VERSION ""

NS_ :

BS_:

BU_:

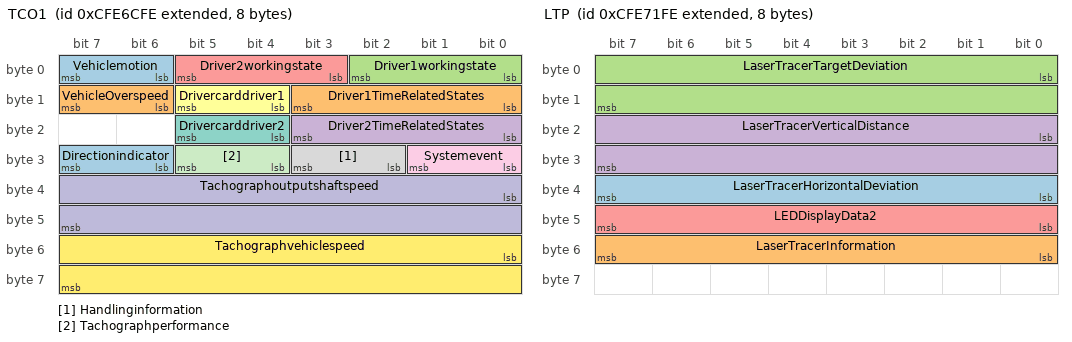
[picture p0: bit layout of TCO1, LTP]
BO_ 2365484286 TCO1: 8 Vector__XXX
 SG_ Directionindicator : 30|2@1+ (1,0) [0|3] "" Vector__XXX
 SG_ Driver1TimeRelatedStates : 8|4@1+ (1,0) [0|15] "" Vector__XXX
 SG_ Driver1workingstate : 0|3@1+ (1,0) [0|7] "" Vector__XXX
 SG_ Driver2TimeRelatedStates : 16|4@1+ (1,0) [0|15] "" Vector__XXX
 SG_ Driver2workingstate : 3|3@1+ (1,0) [0|7] "" Vector__XXX
 SG_ Drivercarddriver1 : 12|2@1+ (1,0) [0|3] "" Vector__XXX
 SG_ Drivercarddriver2 : 20|2@1+ (1,0) [0|3] "" Vector__XXX
 SG_ Handlinginformation : 26|2@1+ (1,0) [0|3] "" Vector__XXX
 SG_ Systemevent : 24|2@1+ (1,0) [0|3] "" Vector__XXX
 SG_ Tachographoutputshaftspeed : 32|16@1+ (0.125,0) [0|8031.875] "rpm" Vector__XXX
 SG_ Tachographperformance : 28|2@1+ (1,0) [0|3] "" Vector__XXX
 SG_ Tachographvehiclespeed : 48|16@1+ (0.00390625,0) [0|250.996] "km/h" Vector__XXX
 SG_ Vehiclemotion : 6|2@1+ (1,0) [0|3] "" Vector__XXX
 SG_ VehicleOverspeed : 14|2@1+ (1,0) [0|3] "" Vector__XXX

BO_ 2365485566 LTP: 8 Vector__XXX
 SG_ LaserTracerHorizontalDeviation : 32|8@1+ (1,0) [0|250] "%" Vector__XXX
 SG_ LaserTracerInformation : 48|8@1+ (1,0) [0|255] "" Vector__XXX
 SG_ LaserTracerTargetDeviation : 0|16@1+ (0.1,-3200) [-3200|3225.5] "mm" Vector__XXX
 SG_ LaserTracerVerticalDistance : 16|16@1+ (0.1,0) [0|6425.5] "mm" Vector__XXX
 SG_ LEDDisplayData2 : 40|8@1+ (1,0) [0|255] "" Vector__XXX

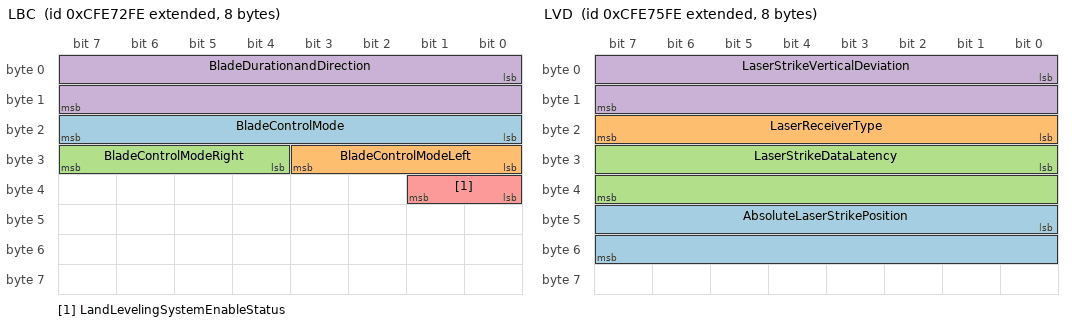
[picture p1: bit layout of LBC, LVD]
BO_ 2365485822 LBC: 8 Vector__XXX
 SG_ BladeControlMode : 16|8@1+ (1,0) [0|255] "" Vector__XXX
 SG_ BladeControlModeLeft : 24|4@1+ (1,0) [0|15] "" Vector__XXX
 SG_ BladeControlModeRight : 28|4@1+ (1,0) [0|15] "" Vector__XXX
 SG_ BladeDurationandDirection : 0|16@1+ (0.1,-3276.8) [-3276.8|3148.7] "s" Vector__XXX
 SG_ LandLevelingSystemEnableStatus : 32|2@1+ (1,0) [0|3] "" Vector__XXX

BO_ 2365486078 LMP: 8 Vector__XXX
 SG_ MastPosition : 0|16@1+ (0.1,-3200) [-3200|3225.5] "mm" Vector__XXX

BO_ 2365486334 LSP: 8 Vector__XXX
 SG_ BldHghtStPntHghRsltn : 16|32@1+ (0.0000001,-209.7152) [-209.7152|211.3929215] "m" Vector__XXX
 SG_ ModifyLevelingSystemSetPoint : 0|16@1+ (0.1,-3200) [-3200|3225.5] "mm" Vector__XXX

BO_ 2365486590 LVD: 8 Vector__XXX
 SG_ AbsoluteLaserStrikePosition : 40|16@1+ (0.1,0) [0|6425.5] "mm" Vector__XXX
 SG_ LaserReceiverType : 16|8@1+ (1,0) [0|250] "count" Vector__XXX
 SG_ LaserStrikeDataLatency : 24|16@1+ (0.0000512,0) [0|3.289856] "s" Vector__XXX
 SG_ LaserStrikeVerticalDeviation : 0|16@1+ (0.1,-3200) [-3200|3225.5] "mm" Vector__XXX

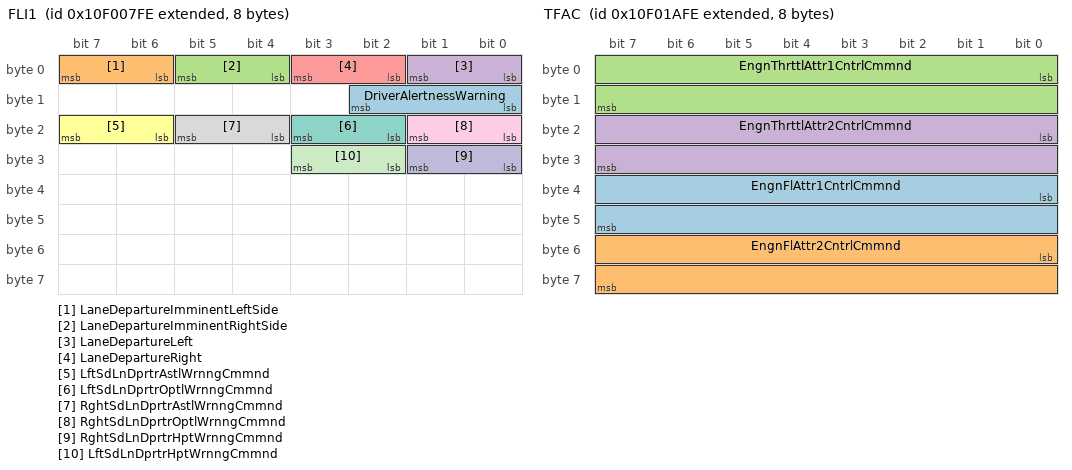
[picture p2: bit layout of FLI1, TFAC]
BO_ 2431649790 FLI1: 8 Vector__XXX
 SG_ DriverAlertnessWarning : 8|3@1+ (1,0) [0|7] "" Vector__XXX
 SG_ LaneDepartureImminentLeftSide : 6|2@1+ (1,0) [0|3] "" Vector__XXX
 SG_ LaneDepartureImminentRightSide : 4|2@1+ (1,0) [0|3] "" Vector__XXX
 SG_ LaneDepartureLeft : 0|2@1+ (1,0) [0|3] "" Vector__XXX
 SG_ LaneDepartureRight : 2|2@1+ (1,0) [0|3] "" Vector__XXX
 SG_ LftSdLnDprtrAstlWrnngCmmnd : 22|2@1+ (1,0) [0|3] "" Vector__XXX
 SG_ LftSdLnDprtrOptlWrnngCmmnd : 18|2@1+ (1,0) [0|3] "" Vector__XXX
 SG_ RghtSdLnDprtrAstlWrnngCmmnd : 20|2@1+ (1,0) [0|3] "" Vector__XXX
 SG_ RghtSdLnDprtrOptlWrnngCmmnd : 16|2@1+ (1,0) [0|3] "" Vector__XXX
 SG_ RghtSdLnDprtrHptWrnngCmmnd : 24|2@1+ (1,0) [0|3] "" Vector__XXX
 SG_ LftSdLnDprtrHptWrnngCmmnd : 26|2@1+ (1,0) [0|3] "" Vector__XXX

BO_ 2431654654 TFAC: 8 Vector__XXX
 SG_ EngnFlAttr1CntrlCmmnd : 32|16@1+ (0.0025,0) [0|160.6375] "%" Vector__XXX
 SG_ EngnFlAttr2CntrlCmmnd : 48|16@1+ (0.0025,0) [0|160.6375] "%" Vector__XXX
 SG_ EngnThrttlAttr1CntrlCmmnd : 0|16@1+ (0.0025,0) [0|160.6375] "%" Vector__XXX
 SG_ EngnThrttlAttr2CntrlCmmnd : 16|16@1+ (0.0025,0) [0|160.6375] "%" Vector__XXX

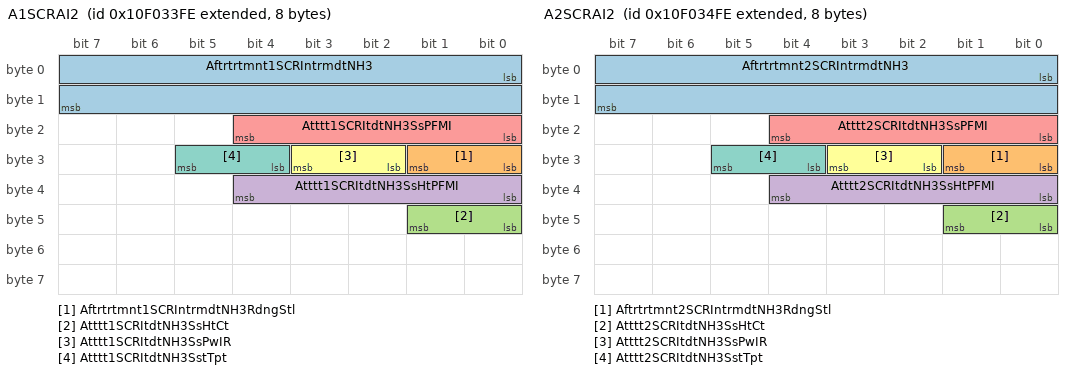
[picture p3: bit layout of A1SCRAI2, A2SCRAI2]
BO_ 2431661054 A1SCRAI2: 8 Vector__XXX
 SG_ Aftrtrtmnt1SCRIntrmdtNH3 : 0|16@1+ (0.1,-200) [-200|6225.5] "ppm" Vector__XXX
 SG_ Aftrtrtmnt1SCRIntrmdtNH3RdngStl : 24|2@1+ (1,0) [0|3] "" Vector__XXX
 SG_ Atttt1SCRItdtNH3SsHtCt : 40|2@1+ (1,0) [0|3] "" Vector__XXX
 SG_ Atttt1SCRItdtNH3SsHtPFMI : 32|5@1+ (1,0) [0|31] "binary" Vector__XXX
 SG_ Atttt1SCRItdtNH3SsPFMI : 16|5@1+ (1,0) [0|31] "binary" Vector__XXX
 SG_ Atttt1SCRItdtNH3SsPwIR : 26|2@1+ (1,0) [0|3] "" Vector__XXX
 SG_ Atttt1SCRItdtNH3SstTpt : 28|2@1+ (1,0) [0|3] "" Vector__XXX

BO_ 2431661310 A2SCRAI2: 8 Vector__XXX
 SG_ Aftrtrtmnt2SCRIntrmdtNH3 : 0|16@1+ (0.1,-200) [-200|6225.5] "ppm" Vector__XXX
 SG_ Aftrtrtmnt2SCRIntrmdtNH3RdngStl : 24|2@1+ (1,0) [0|3] "" Vector__XXX
 SG_ Atttt2SCRItdtNH3SsHtCt : 40|2@1+ (1,0) [0|3] "" Vector__XXX
 SG_ Atttt2SCRItdtNH3SsHtPFMI : 32|5@1+ (1,0) [0|31] "binary" Vector__XXX
 SG_ Atttt2SCRItdtNH3SsPFMI : 16|5@1+ (1,0) [0|31] "binary" Vector__XXX
 SG_ Atttt2SCRItdtNH3SsPwIR : 26|2@1+ (1,0) [0|3] "" Vector__XXX
 SG_ Atttt2SCRItdtNH3SstTpt : 28|2@1+ (1,0) [0|3] "" Vector__XXX

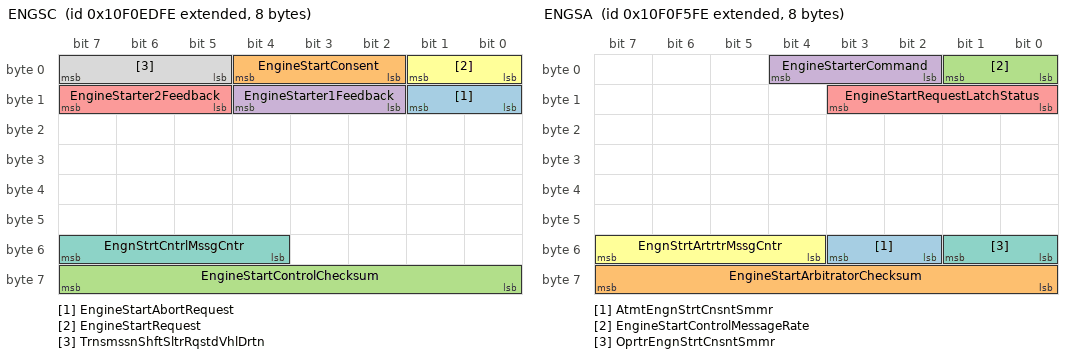
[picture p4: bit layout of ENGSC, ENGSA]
BO_ 2431708670 ENGSC: 8 Vector__XXX
 SG_ EngineStartAbortRequest : 8|2@1+ (1,0) [0|3] "" Vector__XXX
 SG_ EngineStartConsent : 2|3@1+ (1,0) [0|7] "" Vector__XXX
 SG_ EngineStartControlChecksum : 56|8@1+ (1,0) [0|255] "count" Vector__XXX
 SG_ EngineStarter1Feedback : 10|3@1+ (1,0) [0|7] "" Vector__XXX
 SG_ EngineStarter2Feedback : 13|3@1+ (1,0) [0|7] "" Vector__XXX
 SG_ EngineStartRequest : 0|2@1+ (1,0) [0|3] "" Vector__XXX
 SG_ EngnStrtCntrlMssgCntr : 52|4@1+ (1,0) [0|15] "" Vector__XXX
 SG_ TrnsmssnShftSltrRqstdVhlDrtn : 5|3@1+ (1,0) [0|7] "" Vector__XXX

BO_ 2431710718 ENGSA: 8 Vector__XXX
 SG_ AtmtEngnStrtCnsntSmmr : 50|2@1+ (1,0) [0|3] "" Vector__XXX
 SG_ EngineStartArbitratorChecksum : 56|8@1+ (1,0) [0|255] "count" Vector__XXX
 SG_ EngineStartControlMessageRate : 0|2@1+ (1,0) [0|3] "" Vector__XXX
 SG_ EngineStarterCommand : 2|3@1+ (1,0) [0|7] "" Vector__XXX
 SG_ EngineStartRequestLatchStatus : 8|4@1+ (1,0) [0|15] "" Vector__XXX
 SG_ EngnStrtArtrtrMssgCntr : 52|4@1+ (1,0) [0|15] "" Vector__XXX
 SG_ OprtrEngnStrtCnsntSmmr : 48|2@1+ (1,0) [0|3] "" Vector__XXX

BO_ 2431717886 GFP3: 8 Vector__XXX
 SG_ EngnFlVlv1DffrntlPrssrHghRsltn : 0|16@1+ (0.0078125,-100) [-100|401.99] "kPa" Vector__XXX
 SG_ EngnGssFlSpplFltrDffrntlPrssr : 16|16@1+ (0.0078125,-100) [-100|401.99] "kPa" Vector__XXX
 SG_ EngnGssFlSpplFltrIntkPrssr : 32|16@1+ (0.5,0) [0|32127.5] "kPa" Vector__XXX

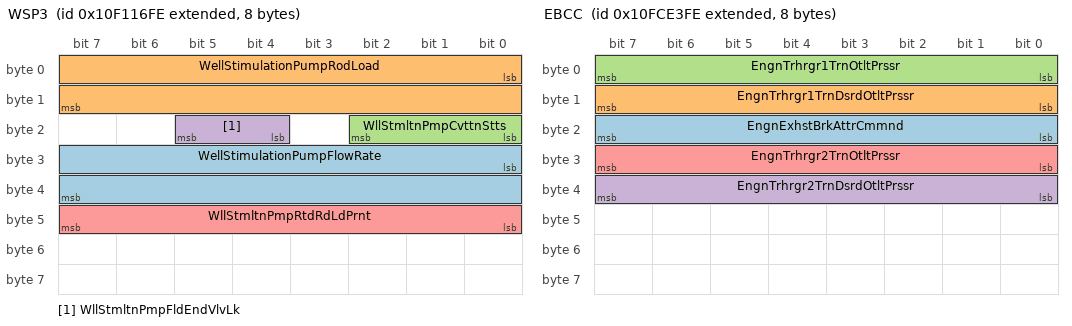
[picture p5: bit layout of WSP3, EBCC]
BO_ 2431719166 WSP3: 8 Vector__XXX
 SG_ WellStimulationPumpFlowRate : 24|16@1+ (0.5,0) [0|32127.5] "l/min" Vector__XXX
 SG_ WellStimulationPumpRodLoad : 0|16@1+ (5,0) [0|321275] "kN" Vector__XXX
 SG_ WllStmltnPmpCvttnStts : 16|3@1+ (1,0) [0|7] "" Vector__XXX
 SG_ WllStmltnPmpFldEndVlvLk : 20|2@1+ (1,0) [0|3] "" Vector__XXX
 SG_ WllStmltnPmpRtdRdLdPrnt : 40|8@1+ (0.5,0) [0|125] "%" Vector__XXX

BO_ 2432471038 AF3: 8 Vector__XXX
 SG_ EngnFlVprzr1DshrgTmprtr : 16|8@1+ (1,-40) [-40|210] "degC" Vector__XXX
 SG_ EngnGssFlSpplPrssr1ExtnddRng : 0|16@1+ (0.00390625,0) [0|250.996] "MPa" Vector__XXX
 SG_ GssFlAmltrTmprtr : 24|8@1+ (1,-40) [-40|210] "degC" Vector__XXX
 SG_ EGssFSppPssRtCtCd : 32|16@1+ (0.0025,0) [0|160.6375] "%" Vector__XXX

BO_ 2432492542 EBCC: 8 Vector__XXX
 SG_ EngnExhstBrkAttrCmmnd : 16|8@1+ (0.4,0) [0|100] "%" Vector__XXX
 SG_ EngnTrhrgr1TrnDsrdOtltPrssr : 8|8@1+ (2,0) [0|500] "kPa" Vector__XXX
 SG_ EngnTrhrgr1TrnOtltPrssr : 0|8@1+ (2,0) [0|500] "kPa" Vector__XXX
 SG_ EngnTrhrgr2TrnDsrdOtltPrssr : 32|8@1+ (2,0) [0|500] "kPa" Vector__XXX
 SG_ EngnTrhrgr2TrnOtltPrssr : 24|8@1+ (2,0) [0|500] "kPa" Vector__XXX

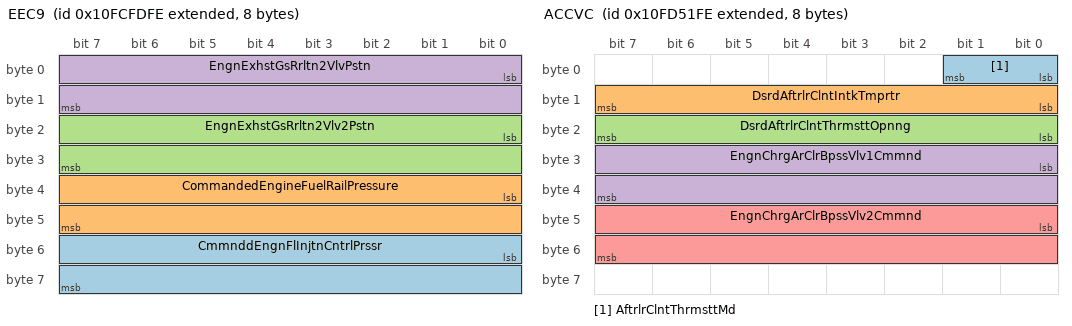
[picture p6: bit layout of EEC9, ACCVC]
BO_ 2432499198 EEC9: 8 Vector__XXX
 SG_ CmmnddEngnFlInjtnCntrlPrssr : 48|16@1+ (0.00390625,0) [0|250.996] "MPa" Vector__XXX
 SG_ CommandedEngineFuelRailPressure : 32|16@1+ (0.00390625,0) [0|250.996] "MPa" Vector__XXX
 SG_ EngnExhstGsRrltn2Vlv2Pstn : 16|16@1+ (0.0025,0) [0|160.6375] "%" Vector__XXX
 SG_ EngnExhstGsRrltn2VlvPstn : 0|16@1+ (0.0025,0) [0|160.6375] "%" Vector__XXX

BO_ 2432520702 ACCVC: 8 Vector__XXX
 SG_ AftrlrClntThrmsttMd : 0|2@1+ (1,0) [0|3] "" Vector__XXX
 SG_ DsrdAftrlrClntIntkTmprtr : 8|8@1+ (1,-40) [-40|210] "degC" Vector__XXX
 SG_ DsrdAftrlrClntThrmsttOpnng : 16|8@1+ (0.4,0) [0|100] "%" Vector__XXX
 SG_ EngnChrgArClrBpssVlv1Cmmnd : 24|16@1+ (0.0025,0) [0|160.6375] "%" Vector__XXX
 SG_ EngnChrgArClrBpssVlv2Cmmnd : 40|16@1+ (0.0025,0) [0|160.6375] "%" Vector__XXX

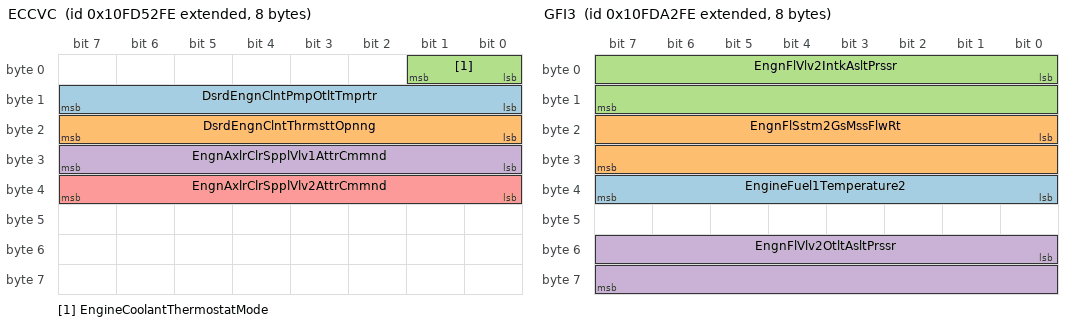
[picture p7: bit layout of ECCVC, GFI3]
BO_ 2432520958 ECCVC: 8 Vector__XXX
 SG_ DsrdEngnClntPmpOtltTmprtr : 8|8@1+ (1,-40) [-40|210] "degC" Vector__XXX
 SG_ DsrdEngnClntThrmsttOpnng : 16|8@1+ (0.4,0) [0|100] "%" Vector__XXX
 SG_ EngineCoolantThermostatMode : 0|2@1+ (1,0) [0|3] "" Vector__XXX
 SG_ EngnAxlrClrSpplVlv1AttrCmmnd : 24|8@1+ (0.4,0) [0|100] "%" Vector__XXX
 SG_ EngnAxlrClrSpplVlv2AttrCmmnd : 32|8@1+ (0.4,0) [0|100] "%" Vector__XXX

BO_ 2432541438 GFI3: 8 Vector__XXX
 SG_ EngineFuel1Temperature2 : 32|8@1+ (1,-40) [-40|210] "degC" Vector__XXX
 SG_ EngnFlSstm2GsMssFlwRt : 16|16@1+ (0.05,0) [0|3212.75] "kg/h" Vector__XXX
 SG_ EngnFlVlv2IntkAsltPrssr : 0|16@1+ (0.1,0) [0|6425.5] "kPa" Vector__XXX
 SG_ EngnFlVlv2OtltAsltPrssr : 48|16@1+ (0.1,0) [0|6425.5] "kPa" Vector__XXX

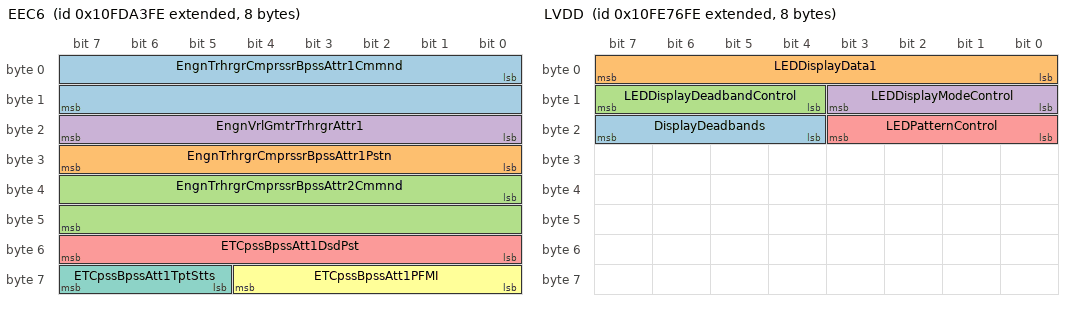
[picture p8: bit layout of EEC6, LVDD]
BO_ 2432541694 EEC6: 8 Vector__XXX
 SG_ EngnTrhrgrCmprssrBpssAttr1Cmmnd : 0|16@1+ (0.0025,0) [0|160.6375] "%" Vector__XXX
 SG_ EngnTrhrgrCmprssrBpssAttr1Pstn : 24|8@1+ (0.4,0) [0|100] "%" Vector__XXX
 SG_ EngnTrhrgrCmprssrBpssAttr2Cmmnd : 32|16@1+ (0.0025,0) [0|160.6375] "%" Vector__XXX
 SG_ EngnVrlGmtrTrhrgrAttr1 : 16|8@1+ (0.4,0) [0|100] "%" Vector__XXX
 SG_ ETCpssBpssAtt1DsdPst : 48|8@1+ (0.4,0) [0|100] "%" Vector__XXX
 SG_ ETCpssBpssAtt1PFMI : 56|5@1+ (1,0) [0|31] "binary" Vector__XXX
 SG_ ETCpssBpssAtt1TptStts : 61|3@1+ (1,0) [0|7] "" Vector__XXX

BO_ 2432593918 ACC1: 8 Vector__XXX
 SG_ ACCDistanceAlertSignal : 52|2@1+ (1,0) [0|3] "" Vector__XXX
 SG_ ACCSystemShutoffWarning : 50|2@1+ (1,0) [0|3] "" Vector__XXX
 SG_ ACCTargetDetected : 48|2@1+ (1,0) [0|3] "" Vector__XXX
 SG_ AdaptiveCruiseControlMode : 24|3@1+ (1,0) [0|7] "" Vector__XXX
 SG_ AdaptiveCruiseControlSetSpeed : 16|8@1+ (1,0) [0|250] "km/h" Vector__XXX
 SG_ Adptvrsntrlstdstnmd : 27|3@1+ (1,0) [0|7] "" Vector__XXX
 SG_ Distancetoforwardvehicle : 8|8@1+ (1,0) [0|250] "m" Vector__XXX
 SG_ ForwardCollisionWarning : 54|2@1+ (1,0) [0|3] "" Vector__XXX
 SG_ Roadcurvature : 32|16@1+ (0.0078125,-250) [-250|251.992] "1/km" Vector__XXX
 SG_ Speedofforwardvehicle : 0|8@1+ (1,0) [0|250] "km/h" Vector__XXX

BO_ 2432595710 LVDD: 8 Vector__XXX
 SG_ DisplayDeadbands : 20|4@1+ (1,0) [0|15] "" Vector__XXX
 SG_ LEDDisplayData1 : 0|8@1+ (1,0) [0|255] "" Vector__XXX
 SG_ LEDDisplayDeadbandControl : 12|4@1+ (1,0) [0|15] "" Vector__XXX
 SG_ LEDDisplayModeControl : 8|4@1+ (1,0) [0|15] "" Vector__XXX
 SG_ LEDPatternControl : 16|4@1+ (1,0) [0|15] "" Vector__XXX

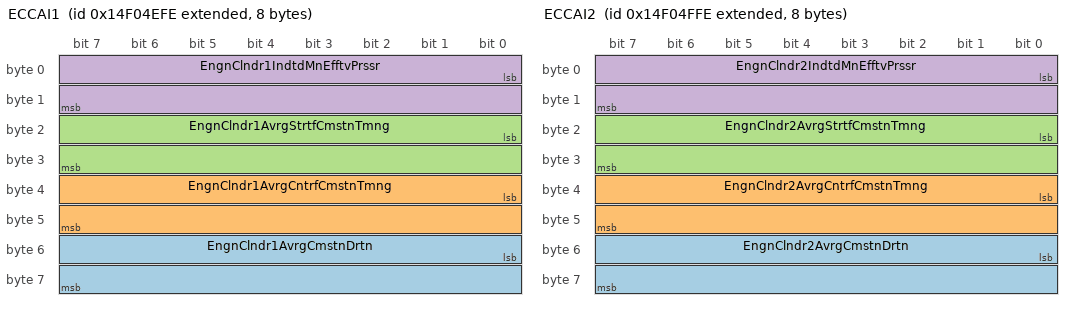
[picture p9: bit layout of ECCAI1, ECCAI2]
BO_ 2498776830 ECCAI1: 8 Vector__XXX
 SG_ EngnClndr1AvrgCmstnDrtn : 48|16@1+ (0.0078125,0) [0|501.99] "deg" Vector__XXX
 SG_ EngnClndr1AvrgCntrfCmstnTmng : 32|16@1+ (0.0078125,-250) [-250|250.992] "deg" Vector__XXX
 SG_ EngnClndr1AvrgStrtfCmstnTmng : 16|16@1+ (0.0078125,-250) [-250|250.992] "deg" Vector__XXX
 SG_ EngnClndr1IndtdMnEfftvPrssr : 0|16@1+ (0.0001220703125,-1) [-1|6.84362793] "MPa" Vector__XXX

BO_ 2498777086 ECCAI2: 8 Vector__XXX
 SG_ EngnClndr2AvrgCmstnDrtn : 48|16@1+ (0.0078125,0) [0|501.99] "deg" Vector__XXX
 SG_ EngnClndr2AvrgCntrfCmstnTmng : 32|16@1+ (0.0078125,-250) [-250|250.992] "deg" Vector__XXX
 SG_ EngnClndr2AvrgStrtfCmstnTmng : 16|16@1+ (0.0078125,-250) [-250|250.992] "deg" Vector__XXX
 SG_ EngnClndr2IndtdMnEfftvPrssr : 0|16@1+ (0.0001220703125,-1) [-1|6.84362793] "MPa" Vector__XXX

BO_ 2498777342 ECCAI3: 8 Vector__XXX
 SG_ EngnClndr3AvrgCmstnDrtn : 48|16@1+ (0.0078125,0) [0|501.99] "deg" Vector__XXX
 SG_ EngnClndr3AvrgCntrfCmstnTmng : 32|16@1+ (0.0078125,-250) [-250|250.992] "deg" Vector__XXX
 SG_ EngnClndr3AvrgStrtfCmstnTmng : 16|16@1+ (0.0078125,-250) [-250|250.992] "deg" Vector__XXX
 SG_ EngnClndr3IndtdMnEfftvPrssr : 0|16@1+ (0.0001220703125,-1) [-1|6.84362793] "MPa" Vector__XXX

BO_ 2498777598 ECCAI4: 8 Vector__XXX
 SG_ EngnClndr4AvrgCmstnDrtn : 48|16@1+ (0.0078125,0) [0|501.99] "deg" Vector__XXX
 SG_ EngnClndr4AvrgCntrfCmstnTmng : 32|16@1+ (0.0078125,-250) [-250|250.992] "deg" Vector__XXX
 SG_ EngnClndr4AvrgStrtfCmstnTmng : 16|16@1+ (0.0078125,-250) [-250|250.992] "deg" Vector__XXX
 SG_ EngnClndr4IndtdMnEfftvPrssr : 0|16@1+ (0.0001220703125,-1) [-1|6.84362793] "MPa" Vector__XXX

BO_ 2498777854 ECCAI5: 8 Vector__XXX
 SG_ EngnClndr5AvrgCmstnDrtn : 48|16@1+ (0.0078125,0) [0|501.99] "deg" Vector__XXX
 SG_ EngnClndr5AvrgCntrfCmstnTmng : 32|16@1+ (0.0078125,-250) [-250|250.992] "deg" Vector__XXX
 SG_ EngnClndr5AvrgStrtfCmstnTmng : 16|16@1+ (0.0078125,-250) [-250|250.992] "deg" Vector__XXX
 SG_ EngnClndr5IndtdMnEfftvPrssr : 0|16@1+ (0.0001220703125,-1) [-1|6.84362793] "MPa" Vector__XXX

BO_ 2498778110 ECCAI6: 8 Vector__XXX
 SG_ EngnClndr6AvrgCmstnDrtn : 48|16@1+ (0.0078125,0) [0|501.99] "deg" Vector__XXX
 SG_ EngnClndr6AvrgCntrfCmstnTmng : 32|16@1+ (0.0078125,-250) [-250|250.992] "deg" Vector__XXX
 SG_ EngnClndr6AvrgStrtfCmstnTmng : 16|16@1+ (0.0078125,-250) [-250|250.992] "deg" Vector__XXX
 SG_ EngnClndr6IndtdMnEfftvPrssr : 0|16@1+ (0.0001220703125,-1) [-1|6.84362793] "MPa" Vector__XXX

BO_ 2498778366 ECCAI7: 8 Vector__XXX
 SG_ EngnClndr7AvrgCmstnDrtn : 48|16@1+ (0.0078125,0) [0|501.99] "deg" Vector__XXX
 SG_ EngnClndr7AvrgCntrfCmstnTmng : 32|16@1+ (0.0078125,-250) [-250|250.992] "deg" Vector__XXX
 SG_ EngnClndr7AvrgStrtfCmstnTmng : 16|16@1+ (0.0078125,-250) [-250|250.992] "deg" Vector__XXX
 SG_ EngnClndr7IndtdMnEfftvPrssr : 0|16@1+ (0.0001220703125,-1) [-1|6.84362793] "MPa" Vector__XXX

BO_ 2498778622 ECCAI8: 8 Vector__XXX
 SG_ EngnClndr8AvrgCmstnDrtn : 48|16@1+ (0.0078125,0) [0|501.99] "deg" Vector__XXX
 SG_ EngnClndr8AvrgCntrfCmstnTmng : 32|16@1+ (0.0078125,-250) [-250|250.992] "deg" Vector__XXX
 SG_ EngnClndr8AvrgStrtfCmstnTmng : 16|16@1+ (0.0078125,-250) [-250|250.992] "deg" Vector__XXX
 SG_ EngnClndr8IndtdMnEfftvPrssr : 0|16@1+ (0.0001220703125,-1) [-1|6.84362793] "MPa" Vector__XXX

BO_ 2498778878 ECCAI9: 8 Vector__XXX
 SG_ EngnClndr9AvrgCmstnDrtn : 48|16@1+ (0.0078125,0) [0|501.99] "deg" Vector__XXX
 SG_ EngnClndr9AvrgCntrfCmstnTmng : 32|16@1+ (0.0078125,-250) [-250|250.992] "deg" Vector__XXX
 SG_ EngnClndr9AvrgStrtfCmstnTmng : 16|16@1+ (0.0078125,-250) [-250|250.992] "deg" Vector__XXX
 SG_ EngnClndr9IndtdMnEfftvPrssr : 0|16@1+ (0.0001220703125,-1) [-1|6.84362793] "MPa" Vector__XXX

BO_ 2498779134 ECCAI10: 8 Vector__XXX
 SG_ EngnClndr10AvrgCmstnDrtn : 48|16@1+ (0.0078125,0) [0|501.99] "deg" Vector__XXX
 SG_ EngnClndr10AvrgCntrfCmstnTmng : 32|16@1+ (0.0078125,-250) [-250|250.992] "deg" Vector__XXX
 SG_ EngnClndr10AvrgStrtfCmstnTmng : 16|16@1+ (0.0078125,-250) [-250|250.992] "deg" Vector__XXX
 SG_ EngnClndr10IndtdMnEfftvPrssr : 0|16@1+ (0.0001220703125,-1) [-1|6.84362793] "MPa" Vector__XXX

BO_ 2498779390 ECCAI11: 8 Vector__XXX
 SG_ EngnClndr11AvrgCmstnDrtn : 48|16@1+ (0.0078125,0) [0|501.99] "deg" Vector__XXX
 SG_ EngnClndr11AvrgCntrfCmstnTmng : 32|16@1+ (0.0078125,-250) [-250|250.992] "deg" Vector__XXX
 SG_ EngnClndr11AvrgStrtfCmstnTmng : 16|16@1+ (0.0078125,-250) [-250|250.992] "deg" Vector__XXX
 SG_ EngnClndr11IndtdMnEfftvPrssr : 0|16@1+ (0.0001220703125,-1) [-1|6.84362793] "MPa" Vector__XXX

BO_ 2498779646 ECCAI12: 8 Vector__XXX
 SG_ EngnClndr12AvrgCmstnDrtn : 48|16@1+ (0.0078125,0) [0|501.99] "deg" Vector__XXX
 SG_ EngnClndr12AvrgCntrfCmstnTmng : 32|16@1+ (0.0078125,-250) [-250|250.992] "deg" Vector__XXX
 SG_ EngnClndr12AvrgStrtfCmstnTmng : 16|16@1+ (0.0078125,-250) [-250|250.992] "deg" Vector__XXX
 SG_ EngnClndr12IndtdMnEfftvPrssr : 0|16@1+ (0.0001220703125,-1) [-1|6.84362793] "MPa" Vector__XXX

BO_ 2498779902 ECCAI13: 8 Vector__XXX
 SG_ EngnClndr13AvrgCmstnDrtn : 48|16@1+ (0.0078125,0) [0|501.99] "deg" Vector__XXX
 SG_ EngnClndr13AvrgCntrfCmstnTmng : 32|16@1+ (0.0078125,-250) [-250|250.992] "deg" Vector__XXX
 SG_ EngnClndr13AvrgStrtfCmstnTmng : 16|16@1+ (0.0078125,-250) [-250|250.992] "deg" Vector__XXX
 SG_ EngnClndr13IndtdMnEfftvPrssr : 0|16@1+ (0.0001220703125,-1) [-1|6.84362793] "MPa" Vector__XXX

BO_ 2498780158 ECCAI14: 8 Vector__XXX
 SG_ EngnClndr14AvrgCmstnDrtn : 48|16@1+ (0.0078125,0) [0|501.99] "deg" Vector__XXX
 SG_ EngnClndr14AvrgCntrfCmstnTmng : 32|16@1+ (0.0078125,-250) [-250|250.992] "deg" Vector__XXX
 SG_ EngnClndr14AvrgStrtfCmstnTmng : 16|16@1+ (0.0078125,-250) [-250|250.992] "deg" Vector__XXX
 SG_ EngnClndr14IndtdMnEfftvPrssr : 0|16@1+ (0.0001220703125,-1) [-1|6.84362793] "MPa" Vector__XXX

BO_ 2498780414 ECCAI15: 8 Vector__XXX
 SG_ EngnClndr15AvrgCmstnDrtn : 48|16@1+ (0.0078125,0) [0|501.99] "deg" Vector__XXX
 SG_ EngnClndr15AvrgCntrfCmstnTmng : 32|16@1+ (0.0078125,-250) [-250|250.992] "deg" Vector__XXX
 SG_ EngnClndr15AvrgStrtfCmstnTmng : 16|16@1+ (0.0078125,-250) [-250|250.992] "deg" Vector__XXX
 SG_ EngnClndr15IndtdMnEfftvPrssr : 0|16@1+ (0.0001220703125,-1) [-1|6.84362793] "MPa" Vector__XXX

BO_ 2498780670 ECCAI16: 8 Vector__XXX
 SG_ EngnClndr16AvrgCmstnDrtn : 48|16@1+ (0.0078125,0) [0|501.99] "deg" Vector__XXX
 SG_ EngnClndr16AvrgCntrfCmstnTmng : 32|16@1+ (0.0078125,-250) [-250|250.992] "deg" Vector__XXX
 SG_ EngnClndr16AvrgStrtfCmstnTmng : 16|16@1+ (0.0078125,-250) [-250|250.992] "deg" Vector__XXX
 SG_ EngnClndr16IndtdMnEfftvPrssr : 0|16@1+ (0.0001220703125,-1) [-1|6.84362793] "MPa" Vector__XXX

BO_ 2498780926 ECCAI17: 8 Vector__XXX
 SG_ EngnClndr17AvrgCmstnDrtn : 48|16@1+ (0.0078125,0) [0|501.99] "deg" Vector__XXX
 SG_ EngnClndr17AvrgCntrfCmstnTmng : 32|16@1+ (0.0078125,-250) [-250|250.992] "deg" Vector__XXX
 SG_ EngnClndr17AvrgStrtfCmstnTmng : 16|16@1+ (0.0078125,-250) [-250|250.992] "deg" Vector__XXX
 SG_ EngnClndr17IndtdMnEfftvPrssr : 0|16@1+ (0.0001220703125,-1) [-1|6.84362793] "MPa" Vector__XXX

BO_ 2498781182 ECCAI18: 8 Vector__XXX
 SG_ EngnClndr18AvrgCmstnDrtn : 48|16@1+ (0.0078125,0) [0|501.99] "deg" Vector__XXX
 SG_ EngnClndr18AvrgCntrfCmstnTmng : 32|16@1+ (0.0078125,-250) [-250|250.992] "deg" Vector__XXX
 SG_ EngnClndr18AvrgStrtfCmstnTmng : 16|16@1+ (0.0078125,-250) [-250|250.992] "deg" Vector__XXX
 SG_ EngnClndr18IndtdMnEfftvPrssr : 0|16@1+ (0.0001220703125,-1) [-1|6.84362793] "MPa" Vector__XXX

BO_ 2498781438 ECCAI19: 8 Vector__XXX
 SG_ EngnClndr19AvrgCmstnDrtn : 48|16@1+ (0.0078125,0) [0|501.99] "deg" Vector__XXX
 SG_ EngnClndr19AvrgCntrfCmstnTmng : 32|16@1+ (0.0078125,-250) [-250|250.992] "deg" Vector__XXX
 SG_ EngnClndr19AvrgStrtfCmstnTmng : 16|16@1+ (0.0078125,-250) [-250|250.992] "deg" Vector__XXX
 SG_ EngnClndr19IndtdMnEfftvPrssr : 0|16@1+ (0.0001220703125,-1) [-1|6.84362793] "MPa" Vector__XXX

BO_ 2498781694 ECCAI20: 8 Vector__XXX
 SG_ EngnClndr20AvrgCmstnDrtn : 48|16@1+ (0.0078125,0) [0|501.99] "deg" Vector__XXX
 SG_ EngnClndr20AvrgCntrfCmstnTmng : 32|16@1+ (0.0078125,-250) [-250|250.992] "deg" Vector__XXX
 SG_ EngnClndr20AvrgStrtfCmstnTmng : 16|16@1+ (0.0078125,-250) [-250|250.992] "deg" Vector__XXX
 SG_ EngnClndr20IndtdMnEfftvPrssr : 0|16@1+ (0.0001220703125,-1) [-1|6.84362793] "MPa" Vector__XXX

BO_ 2498825982 DTBI1: 8 Vector__XXX
 SG_ DmpBdRsPstnRltvtRmmnddMxmm : 32|16@1+ (0.005,-150) [-150|171.275] "%" Vector__XXX
 SG_ DumpBodyEjectorBladePosition : 48|8@1+ (0.4,0) [0|100] "%" Vector__XXX
 SG_ DumpBodyRaiseAngle : 16|16@1+ (0.0078125,-200) [-200|301.99] "deg" Vector__XXX
 SG_ DumpBodyRollAngle : 0|16@1+ (0.0078125,-200) [-200|301.99] "deg" Vector__XXX

BO_ 2499547902 CDC1: 8 Vector__XXX
 SG_ CabDoorsLockActuationCommand : 0|3@1+ (1,0) [0|7] "" Vector__XXX
 SG_ LeftFrontWindowPositionCommand : 16|3@1+ (1,0) [0|7] "" Vector__XXX
 SG_ LeftRearWindowPositionCommand : 24|3@1+ (1,0) [0|7] "" Vector__XXX
 SG_ MirrorLeft1HeatCommand : 48|2@1+ (1,0) [0|3] "" Vector__XXX
 SG_ MirrorLeft1HorizontalCommand : 32|2@1+ (1,0) [0|3] "" Vector__XXX
 SG_ MirrorLeft1VerticalCommand : 34|2@1+ (1,0) [0|3] "" Vector__XXX
 SG_ MirrorLeft2HeatCommand : 52|2@1+ (1,0) [0|3] "" Vector__XXX
 SG_ MirrorLeft2HorizontalCommand : 40|2@1+ (1,0) [0|3] "" Vector__XXX
 SG_ MirrorLeft2VerticalCommand : 42|2@1+ (1,0) [0|3] "" Vector__XXX
 SG_ MirrorRight1HeatCommand : 50|2@1+ (1,0) [0|3] "" Vector__XXX
 SG_ MirrorRight1HorizontalCommand : 36|2@1+ (1,0) [0|3] "" Vector__XXX
 SG_ MirrorRight1VerticalCommand : 38|2@1+ (1,0) [0|3] "" Vector__XXX
 SG_ MirrorRight2HeatCommand : 54|2@1+ (1,0) [0|3] "" Vector__XXX
 SG_ MirrorRight2HorizontalCommand : 44|2@1+ (1,0) [0|3] "" Vector__XXX
 SG_ MirrorRight2VerticalCommand : 46|2@1+ (1,0) [0|3] "" Vector__XXX
 SG_ RemoteCabDoorLockRequest : 8|3@1+ (1,0) [0|7] "" Vector__XXX
 SG_ RightFrontWindowPositionCommand : 19|3@1+ (1,0) [0|7] "" Vector__XXX
 SG_ RightRearWindowPositionCommand : 27|3@1+ (1,0) [0|7] "" Vector__XXX
 SG_ MirrorFoldingSwitch : 22|2@1+ (1,0) [0|3] "" Vector__XXX
 SG_ MirrorAutoPanningEnable : 30|2@1+ (1,0) [0|3] "" Vector__XXX

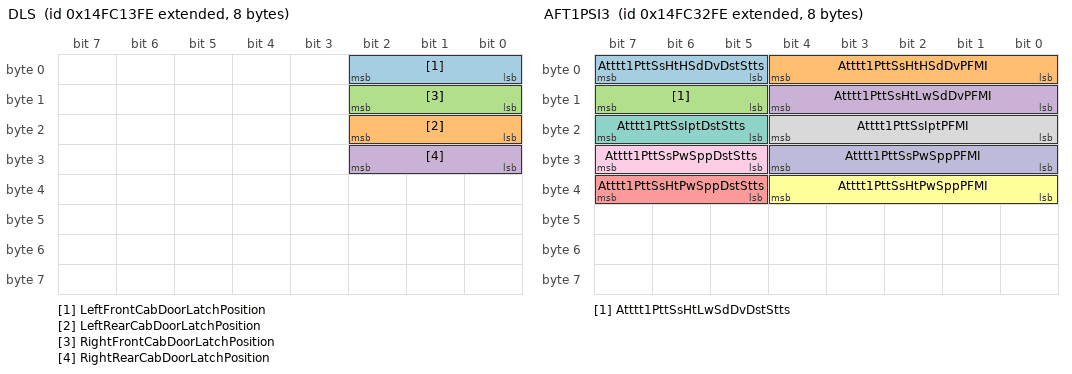
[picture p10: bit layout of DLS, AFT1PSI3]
BO_ 2499548158 DLS: 8 Vector__XXX
 SG_ LeftFrontCabDoorLatchPosition : 0|3@1+ (1,0) [0|7] "" Vector__XXX
 SG_ LeftRearCabDoorLatchPosition : 16|3@1+ (1,0) [0|7] "" Vector__XXX
 SG_ RightFrontCabDoorLatchPosition : 8|3@1+ (1,0) [0|7] "" Vector__XXX
 SG_ RightRearCabDoorLatchPosition : 24|3@1+ (1,0) [0|7] "" Vector__XXX

BO_ 2499548670 VEP6: 8 Vector__XXX
 SG_ BatteryPotentialPowerInput3 : 0|16@1+ (0.05,0) [0|3212.75] "V" Vector__XXX
 SG_ BatteryPotentialPowerInput4 : 16|16@1+ (0.05,0) [0|3212.75] "V" Vector__XXX
 SG_ SLIBattery3NetCurrent : 32|16@1+ (0.05,-1600) [-1600|1612.75] "A" Vector__XXX
 SG_ SLIBattery4NetCurrent : 48|16@1+ (0.05,-1600) [-1600|1612.75] "A" Vector__XXX

BO_ 2499548926 PLT2: 8 Vector__XXX
 SG_ PayloadTemperature5 : 0|16@1+ (0.03125,-273) [-273|1734.96875] "degC" Vector__XXX

BO_ 2499549182 PLT1: 8 Vector__XXX
 SG_ PayloadTemperature1 : 0|16@1+ (0.03125,-273) [-273|1734.96875] "degC" Vector__XXX
 SG_ PayloadTemperature2 : 16|16@1+ (0.03125,-273) [-273|1734.96875] "degC" Vector__XXX
 SG_ PayloadTemperature3 : 32|16@1+ (0.03125,-273) [-273|1734.96875] "degC" Vector__XXX
 SG_ PayloadTemperature4 : 48|16@1+ (0.03125,-273) [-273|1734.96875] "degC" Vector__XXX

BO_ 2499556094 AFT1PSI3: 8 Vector__XXX
 SG_ Atttt1PttSsHtHSdDvDstStts : 5|3@1+ (1,0) [0|7] "" Vector__XXX
 SG_ Atttt1PttSsHtHSdDvPFMI : 0|5@1+ (1,0) [0|31] "" Vector__XXX
 SG_ Atttt1PttSsHtLwSdDvDstStts : 13|3@1+ (1,0) [0|7] "" Vector__XXX
 SG_ Atttt1PttSsHtLwSdDvPFMI : 8|5@1+ (1,0) [0|31] "" Vector__XXX
 SG_ Atttt1PttSsHtPwSppDstStts : 37|3@1+ (1,0) [0|7] "" Vector__XXX
 SG_ Atttt1PttSsHtPwSppPFMI : 32|5@1+ (1,0) [0|31] "" Vector__XXX
 SG_ Atttt1PttSsIptDstStts : 21|3@1+ (1,0) [0|7] "" Vector__XXX
 SG_ Atttt1PttSsIptPFMI : 16|5@1+ (1,0) [0|31] "" Vector__XXX
 SG_ Atttt1PttSsPwSppDstStts : 29|3@1+ (1,0) [0|7] "" Vector__XXX
 SG_ Atttt1PttSsPwSppPFMI : 24|5@1+ (1,0) [0|31] "" Vector__XXX

BO_ 2499556350 EFIMRPI3: 8 Vector__XXX
 SG_ EngnFl1InjtrMtrngRl1DsrdPrssr : 0|16@1+ (5,0) [0|321275] "kPa" Vector__XXX
 SG_ EngnFl1InjtrMtrngRl2DsrdPrssr : 16|16@1+ (5,0) [0|321275] "kPa" Vector__XXX

BO_ 2499556606 EFIMRPI2: 8 Vector__XXX
 SG_ EF1ItMtR1Pss1ExtddR : 0|16@1+ (5,0) [0|321275] "kPa" Vector__XXX
 SG_ EF1ItMtR1Pss2ExtddR : 16|16@1+ (5,0) [0|321275] "kPa" Vector__XXX
 SG_ EF1ItMtR2Pss1ExtddR : 32|16@1+ (5,0) [0|321275] "kPa" Vector__XXX
 SG_ EF1ItMtR2Pss2ExtddR : 48|16@1+ (5,0) [0|321275] "kPa" Vector__XXX

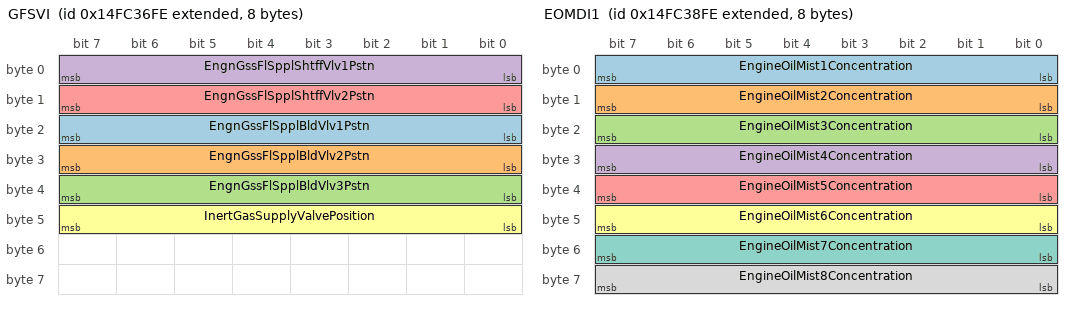
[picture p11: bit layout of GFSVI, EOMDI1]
BO_ 2499557118 GFSVI: 8 Vector__XXX
 SG_ EngnGssFlSpplBldVlv1Pstn : 16|8@1+ (0.4,0) [0|100] "%" Vector__XXX
 SG_ EngnGssFlSpplBldVlv2Pstn : 24|8@1+ (0.4,0) [0|100] "%" Vector__XXX
 SG_ EngnGssFlSpplBldVlv3Pstn : 32|8@1+ (0.4,0) [0|100] "%" Vector__XXX
 SG_ EngnGssFlSpplShtffVlv1Pstn : 0|8@1+ (0.4,0) [0|100] "%" Vector__XXX
 SG_ EngnGssFlSpplShtffVlv2Pstn : 8|8@1+ (0.4,0) [0|100] "%" Vector__XXX
 SG_ InertGasSupplyValvePosition : 40|8@1+ (0.4,0) [0|100] "%" Vector__XXX

BO_ 2499557374 EOMDI2: 8 Vector__XXX
 SG_ EngineOilMist10Concentration : 8|8@1+ (1,0) [0|250] "%" Vector__XXX
 SG_ EngineOilMist9Concentration : 0|8@1+ (1,0) [0|250] "%" Vector__XXX

BO_ 2499557630 EOMDI1: 8 Vector__XXX
 SG_ EngineOilMist1Concentration : 0|8@1+ (1,0) [0|250] "%" Vector__XXX
 SG_ EngineOilMist2Concentration : 8|8@1+ (1,0) [0|250] "%" Vector__XXX
 SG_ EngineOilMist3Concentration : 16|8@1+ (1,0) [0|250] "%" Vector__XXX
 SG_ EngineOilMist4Concentration : 24|8@1+ (1,0) [0|250] "%" Vector__XXX
 SG_ EngineOilMist5Concentration : 32|8@1+ (1,0) [0|250] "%" Vector__XXX
 SG_ EngineOilMist6Concentration : 40|8@1+ (1,0) [0|250] "%" Vector__XXX
 SG_ EngineOilMist7Concentration : 48|8@1+ (1,0) [0|250] "%" Vector__XXX
 SG_ EngineOilMist8Concentration : 56|8@1+ (1,0) [0|250] "%" Vector__XXX

BO_ 2499557886 GFSP2: 8 Vector__XXX
 SG_ PlntGssFlSpplOtltPrssr : 0|16@1+ (0.5,0) [0|32127.5] "kPa" Vector__XXX
 SG_ PlntInrtGsSpplOtltPrssr : 16|16@1+ (0.5,0) [0|32127.5] "kPa" Vector__XXX

BO_ 2499558142 GFSP1: 8 Vector__XXX
 SG_ EngnGssFlSpplPrssr2 : 0|16@1+ (0.5,0) [0|32127.5] "kPa" Vector__XXX
 SG_ EngnGssFlSpplShtffVlv1IntkPrssr : 32|16@1+ (0.5,0) [0|32127.5] "kPa" Vector__XXX
 SG_ EngnGssFlSpplShtffVlv2IntkPrssr : 48|16@1+ (0.5,0) [0|32127.5] "kPa" Vector__XXX
 SG_ EngnGssFlSpplUntIntkPrssr : 16|16@1+ (0.5,0) [0|32127.5] "kPa" Vector__XXX

BO_ 2499580158 EFIMRPI1: 8 Vector__XXX
 SG_ EngnFl1InjtrMtrngRl1Prssr1 : 0|16@1+ (0.00390625,0) [0|250.996] "MPa" Vector__XXX
 SG_ EngnFl1InjtrMtrngRl1Prssr2 : 16|16@1+ (0.00390625,0) [0|250.996] "MPa" Vector__XXX
 SG_ EngnFl1InjtrMtrngRl2Prssr1 : 32|16@1+ (0.00390625,0) [0|250.996] "MPa" Vector__XXX
 SG_ EngnFl1InjtrMtrngRl2Prssr2 : 48|16@1+ (0.00390625,0) [0|250.996] "MPa" Vector__XXX

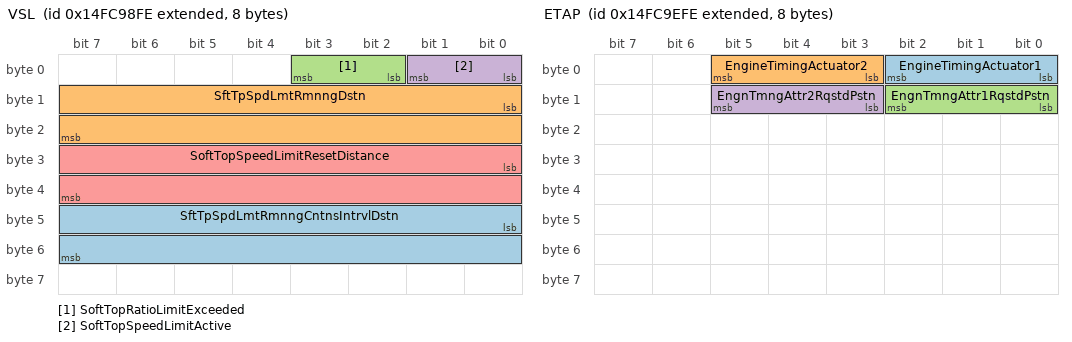
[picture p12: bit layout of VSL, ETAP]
BO_ 2499582206 VSL: 8 Vector__XXX
 SG_ SftTpSpdLmtRmnngCntnsIntrvlDstn : 40|16@1+ (1,0) [0|64255] "km" Vector__XXX
 SG_ SftTpSpdLmtRmnngDstn : 8|16@1+ (1,0) [0|64255] "km" Vector__XXX
 SG_ SoftTopRatioLimitExceeded : 2|2@1+ (1,0) [0|3] "" Vector__XXX
 SG_ SoftTopSpeedLimitActive : 0|2@1+ (1,0) [0|3] "" Vector__XXX
 SG_ SoftTopSpeedLimitResetDistance : 24|16@1+ (1,0) [0|64255] "km" Vector__XXX

BO_ 2499583486 ETAPC: 8 Vector__XXX
 SG_ EngnTmngAttr1PstnCmmnd : 0|3@1+ (1,0) [0|7] "" Vector__XXX
 SG_ EngnTmngAttr2PstnCmmnd : 3|3@1+ (1,0) [0|7] "" Vector__XXX

BO_ 2499583742 ETAP: 8 Vector__XXX
 SG_ EngineTimingActuator1 : 0|3@1+ (1,0) [0|7] "" Vector__XXX
 SG_ EngineTimingActuator2 : 3|3@1+ (1,0) [0|7] "" Vector__XXX
 SG_ EngnTmngAttr1RqstdPstn : 8|3@1+ (1,0) [0|7] "" Vector__XXX
 SG_ EngnTmngAttr2RqstdPstn : 11|3@1+ (1,0) [0|7] "" Vector__XXX

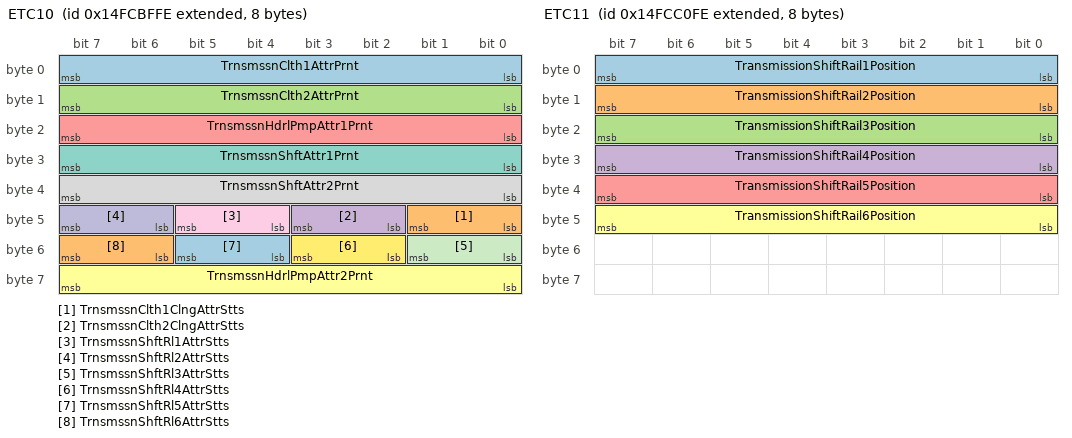
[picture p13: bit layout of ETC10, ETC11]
BO_ 2499592190 ETC10: 8 Vector__XXX
 SG_ TrnsmssnClth1AttrPrnt : 0|8@1+ (0.4,0) [0|100] "%" Vector__XXX
 SG_ TrnsmssnClth1ClngAttrStts : 40|2@1+ (1,0) [0|3] "" Vector__XXX
 SG_ TrnsmssnClth2AttrPrnt : 8|8@1+ (0.4,0) [0|100] "%" Vector__XXX
 SG_ TrnsmssnClth2ClngAttrStts : 42|2@1+ (1,0) [0|3] "" Vector__XXX
 SG_ TrnsmssnHdrlPmpAttr1Prnt : 16|8@1+ (0.4,0) [0|100] "%" Vector__XXX
 SG_ TrnsmssnHdrlPmpAttr2Prnt : 56|8@1+ (0.4,0) [0|100] "%" Vector__XXX
 SG_ TrnsmssnShftAttr1Prnt : 24|8@1+ (0.4,0) [0|100] "%" Vector__XXX
 SG_ TrnsmssnShftAttr2Prnt : 32|8@1+ (0.4,0) [0|100] "%" Vector__XXX
 SG_ TrnsmssnShftRl1AttrStts : 44|2@1+ (1,0) [0|3] "" Vector__XXX
 SG_ TrnsmssnShftRl2AttrStts : 46|2@1+ (1,0) [0|3] "" Vector__XXX
 SG_ TrnsmssnShftRl3AttrStts : 48|2@1+ (1,0) [0|3] "" Vector__XXX
 SG_ TrnsmssnShftRl4AttrStts : 50|2@1+ (1,0) [0|3] "" Vector__XXX
 SG_ TrnsmssnShftRl5AttrStts : 52|2@1+ (1,0) [0|3] "" Vector__XXX
 SG_ TrnsmssnShftRl6AttrStts : 54|2@1+ (1,0) [0|3] "" Vector__XXX

BO_ 2499592446 ETC11: 8 Vector__XXX
 SG_ TransmissionShiftRail1Position : 0|8@1+ (0.4,0) [0|100] "%" Vector__XXX
 SG_ TransmissionShiftRail2Position : 8|8@1+ (0.4,0) [0|100] "%" Vector__XXX
 SG_ TransmissionShiftRail3Position : 16|8@1+ (0.4,0) [0|100] "%" Vector__XXX
 SG_ TransmissionShiftRail4Position : 24|8@1+ (0.4,0) [0|100] "%" Vector__XXX
 SG_ TransmissionShiftRail5Position : 32|8@1+ (0.4,0) [0|100] "%" Vector__XXX
 SG_ TransmissionShiftRail6Position : 40|8@1+ (0.4,0) [0|100] "%" Vector__XXX

BO_ 2499604222 LLRE: 8 Vector__XXX
 SG_ BladeElevationDeviationLeft : 0|16@1+ (1,-32000) [-32000|32255] "mm" Vector__XXX
 SG_ BladeElevationDeviationRight : 16|16@1+ (1,-32000) [-32000|32255] "mm" Vector__XXX
 SG_ BldRfrnElvtnOffstLft : 32|16@1+ (1,-32000) [-32000|32255] "mm" Vector__XXX
 SG_ BldRfrnElvtnOffstRght : 48|16@1+ (1,-32000) [-32000|32255] "mm" Vector__XXX

BO_ 2499604478 EFLP11: 8 Vector__XXX
 SG_ EExstGsRt1OttAstPssHRst : 16|16@1+ (0.1,0) [0|6425.5] "kPa" Vector__XXX
 SG_ EFDvPssHRstExtddR : 48|16@1+ (0.1,0) [0|6425.5] "kPa" Vector__XXX
 SG_ EngnExhstGsRrltn1IntkAsltPrssr : 0|16@1+ (0.1,0) [0|6425.5] "kPa" Vector__XXX
 SG_ EngnOlPrssrHghRsltnExtnddRng : 32|16@1+ (0.1,0) [0|6425.5] "kPa" Vector__XXX

BO_ 2499607550 EMAP: 8 Vector__XXX
 SG_ EExstMdB1FwBVvAttPst : 0|16@1+ (0.0025,0) [0|160.6375] "%" Vector__XXX
 SG_ EExstMdB2FwBVvAttPst : 16|16@1+ (0.0025,0) [0|160.6375] "%" Vector__XXX

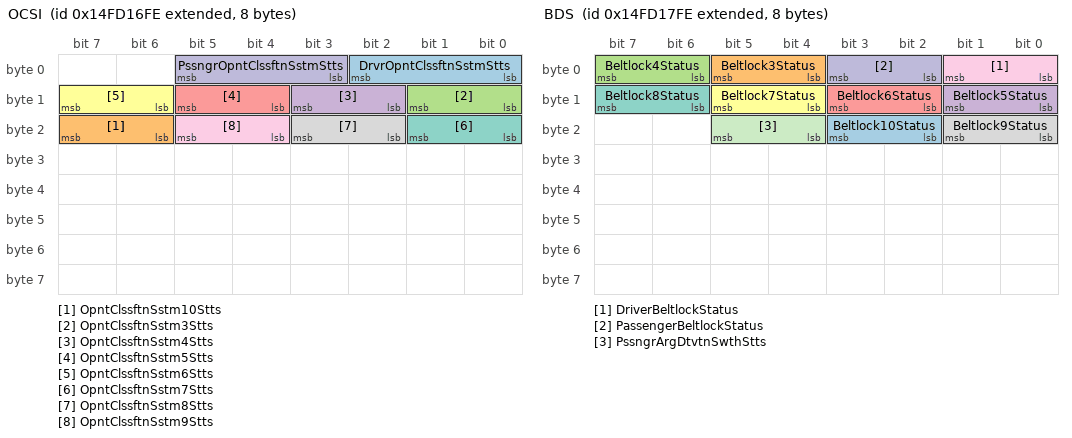
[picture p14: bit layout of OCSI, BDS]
BO_ 2499614462 OCSI: 8 Vector__XXX
 SG_ DrvrOpntClssftnSstmStts : 0|3@1+ (1,0) [0|7] "" Vector__XXX
 SG_ OpntClssftnSstm10Stts : 22|2@1+ (1,0) [0|3] "" Vector__XXX
 SG_ OpntClssftnSstm3Stts : 8|2@1+ (1,0) [0|3] "" Vector__XXX
 SG_ OpntClssftnSstm4Stts : 10|2@1+ (1,0) [0|3] "" Vector__XXX
 SG_ OpntClssftnSstm5Stts : 12|2@1+ (1,0) [0|3] "" Vector__XXX
 SG_ OpntClssftnSstm6Stts : 14|2@1+ (1,0) [0|3] "" Vector__XXX
 SG_ OpntClssftnSstm7Stts : 16|2@1+ (1,0) [0|3] "" Vector__XXX
 SG_ OpntClssftnSstm8Stts : 18|2@1+ (1,0) [0|3] "" Vector__XXX
 SG_ OpntClssftnSstm9Stts : 20|2@1+ (1,0) [0|3] "" Vector__XXX
 SG_ PssngrOpntClssftnSstmStts : 3|3@1+ (1,0) [0|7] "" Vector__XXX

BO_ 2499614718 BDS: 8 Vector__XXX
 SG_ Beltlock10Status : 18|2@1+ (1,0) [0|3] "" Vector__XXX
 SG_ Beltlock3Status : 4|2@1+ (1,0) [0|3] "" Vector__XXX
 SG_ Beltlock4Status : 6|2@1+ (1,0) [0|3] "" Vector__XXX
 SG_ Beltlock5Status : 8|2@1+ (1,0) [0|3] "" Vector__XXX
 SG_ Beltlock6Status : 10|2@1+ (1,0) [0|3] "" Vector__XXX
 SG_ Beltlock7Status : 12|2@1+ (1,0) [0|3] "" Vector__XXX
 SG_ Beltlock8Status : 14|2@1+ (1,0) [0|3] "" Vector__XXX
 SG_ Beltlock9Status : 16|2@1+ (1,0) [0|3] "" Vector__XXX
 SG_ DriverBeltlockStatus : 0|2@1+ (1,0) [0|3] "" Vector__XXX
 SG_ PassengerBeltlockStatus : 2|2@1+ (1,0) [0|3] "" Vector__XXX
 SG_ PssngrArgDtvtnSwthStts : 20|2@1+ (1,0) [0|3] "" Vector__XXX

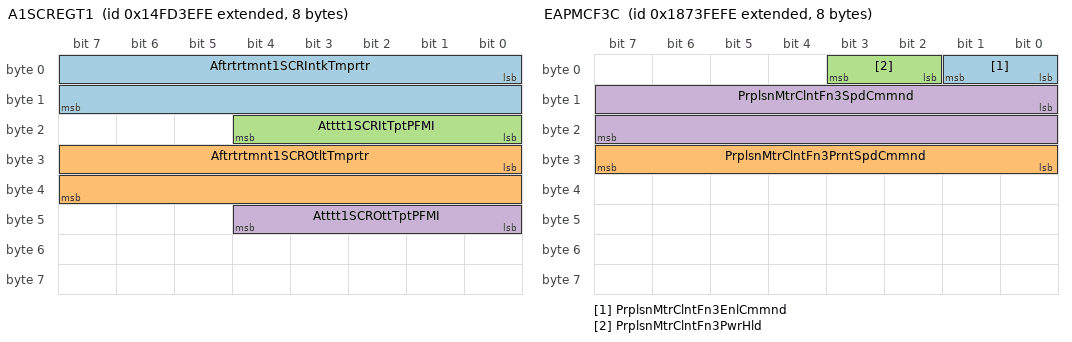
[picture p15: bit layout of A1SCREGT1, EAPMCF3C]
BO_ 2499624702 A1SCREGT1: 8 Vector__XXX
 SG_ Aftrtrtmnt1SCRIntkTmprtr : 0|16@1+ (0.03125,-273) [-273|1734.96875] "degC" Vector__XXX
 SG_ Aftrtrtmnt1SCROtltTmprtr : 24|16@1+ (0.03125,-273) [-273|1734.96875] "degC" Vector__XXX
 SG_ Atttt1SCRItTptPFMI : 16|5@1+ (1,0) [0|31] "" Vector__XXX
 SG_ Atttt1SCROttTptPFMI : 40|5@1+ (1,0) [0|31] "" Vector__XXX

BO_ 2499630078 EAI: 8 Vector__XXX
 SG_ EngineExhaustTemperatureAverage : 0|16@1+ (0.03125,-273) [-273|1734.96875] "degC" Vector__XXX
 SG_ EngnExhstBnk1TmprtrAvrg : 16|16@1+ (0.03125,-273) [-273|1734.96875] "degC" Vector__XXX
 SG_ EngnExhstBnk2TmprtrAvrg : 32|16@1+ (0.03125,-273) [-273|1734.96875] "degC" Vector__XXX

BO_ 2499635454 GCVW: 8 Vector__XXX
 SG_ GrossCombinationWeight : 0|24@1+ (2,0) [0|32899070] "kg" Vector__XXX
 SG_ NetVehicleWeightChange : 24|24@1+ (2,-16449535) [-16449535|16449535] "kg" Vector__XXX

BO_ 2499635966 AGW: 8 Vector__XXX
 SG_ AdditionalAxleGroupLocation : 4|4@1+ (1,0) [0|15] "" Vector__XXX
 SG_ AxleGroupLocation : 0|4@1+ (1,0) [0|15] "" Vector__XXX
 SG_ AxleGroupWeight : 8|16@1+ (2,0) [0|128510] "kg" Vector__XXX

BO_ 2499641854 EGRBV: 8 Vector__XXX
 SG_ EExstGsRt1CBpssAttPst : 0|8@1+ (0.4,0) [0|100] "%" Vector__XXX

BO_ 2550660862 GPV4: 8 Vector__XXX
 SG_ ValveAssemblyLoadsensePressure : 24|16@1+ (5,0) [0|321275] "kPa" Vector__XXX
 SG_ ValveAssemblySupplyPressure : 40|16@1+ (5,0) [0|321275] "kPa" Vector__XXX
 SG_ ValveLoadSensePressure : 0|16@1+ (5,0) [0|321275] "kPa" Vector__XXX
 SG_ ValvePilotPressure : 16|8@1+ (16,0) [0|4000] "kPa" Vector__XXX

BO_ 2550988542 EEC16: 8 Vector__XXX
 SG_ EngineClutchEngageRequestStatus : 10|2@1+ (1,0) [0|3] "" Vector__XXX
 SG_ ReadyForClutchEngagementStatus : 8|2@1+ (1,0) [0|3] "" Vector__XXX
 SG_ AcceleratorPedal3Position : 0|8@1+ (0.4,0) [0|100] "%" Vector__XXX

BO_ 2557214462 WSPSCC: 8 Vector__XXX
 SG_ WSttPpDsPssCtStPtCd : 8|4@1+ (1,0) [0|15] "" Vector__XXX
 SG_ WSttPpStPssCtStPtCd : 0|4@1+ (1,0) [0|15] "" Vector__XXX

BO_ 2557345534 WSPT1: 19 Vector__XXX
 SG_ WllStmltnPmpPlngrFrngOrdr : 144|4@1+ (1,0) [0|15] "" Vector__XXX
 SG_ WllStmltnPmpRdLdHghThrshld : 128|16@1+ (5,0) [0|321275] "kN" Vector__XXX
 SG_ WllStmltnPmpStnPrssrHghThrshld : 64|16@1+ (0.1,-3212.7) [-3212.7|3212.8] "kPa" Vector__XXX
 SG_ WllStmltnPmpStnPrssrLwThrshld : 48|16@1+ (0.1,-3212.7) [-3212.7|3212.8] "kPa" Vector__XXX
 SG_ WSttPpCstSpdHTsd : 112|16@1+ (0.125,0) [0|8031.875] "rpm" Vector__XXX
 SG_ WSttPpCstSpdLwTsd : 96|16@1+ (0.125,0) [0|8031.875] "rpm" Vector__XXX
 SG_ WSttPpDsPssHTsd : 80|16@1+ (5,0) [0|321275] "kPa" Vector__XXX
 SG_ WSttPpGBxOPssHTsd : 16|16@1+ (0.1,0) [0|6425.5] "kPa" Vector__XXX
 SG_ WSttPpGBxOPssLwTsd : 0|16@1+ (0.1,0) [0|6425.5] "kPa" Vector__XXX
 SG_ WSttPpGBxOTptHTsd : 40|8@1+ (1,-40) [-40|210] "degC" Vector__XXX
 SG_ WSttPpGBxOTptLwTsd : 32|8@1+ (1,-40) [-40|210] "degC" Vector__XXX

BO_ 2557673214 ODMCC: 37 Vector__XXX
 SG_ OlDrsMntrCnfgrtnIdntftnNmr : 0|8@1+ (1,0) [0|250] "count" Vector__XXX
 SG_ OlDrsMntrFrrsBn1CntCmmnd : 8|24@1+ (1,0) [0|16449535] "count" Vector__XXX
 SG_ OlDrsMntrFrrsBn2CntCmmnd : 32|24@1+ (1,0) [0|16449535] "count" Vector__XXX
 SG_ OlDrsMntrFrrsBn3CntCmmnd : 56|24@1+ (1,0) [0|16449535] "count" Vector__XXX
 SG_ OlDrsMntrFrrsBn4CntCmmnd : 80|24@1+ (1,0) [0|16449535] "count" Vector__XXX
 SG_ OlDrsMntrFrrsBn5CntCmmnd : 104|24@1+ (1,0) [0|16449535] "count" Vector__XXX
 SG_ OlDrsMntrFrrsBn6CntCmmnd : 128|24@1+ (1,0) [0|16449535] "count" Vector__XXX
 SG_ OlDrsMntrNnFrrsBn1CntCmmnd : 152|24@1+ (1,0) [0|16449535] "count" Vector__XXX
 SG_ OlDrsMntrNnFrrsBn2CntCmmnd : 176|24@1+ (1,0) [0|16449535] "count" Vector__XXX
 SG_ OlDrsMntrNnFrrsBn3CntCmmnd : 200|24@1+ (1,0) [0|16449535] "count" Vector__XXX
 SG_ OlDrsMntrNnFrrsBn4CntCmmnd : 224|24@1+ (1,0) [0|16449535] "count" Vector__XXX
 SG_ OlDrsMntrNnFrrsBn5CntCmmnd : 248|24@1+ (1,0) [0|16449535] "count" Vector__XXX
 SG_ OlDrsMntrNnFrrsBn6CntCmmnd : 272|24@1+ (1,0) [0|16449535] "count" Vector__XXX

BO_ 2557738750 EAPMCF3C: 8 Vector__XXX
 SG_ PrplsnMtrClntFn3EnlCmmnd : 0|2@1+ (1,0) [0|3] "" Vector__XXX
 SG_ PrplsnMtrClntFn3PrntSpdCmmnd : 24|8@1+ (0.5,0) [0|125] "%" Vector__XXX
 SG_ PrplsnMtrClntFn3PwrHld : 2|2@1+ (1,0) [0|3] "" Vector__XXX
 SG_ PrplsnMtrClntFn3SpdCmmnd : 8|16@1+ (0.5,0) [0|32127.5] "rpm" Vector__XXX

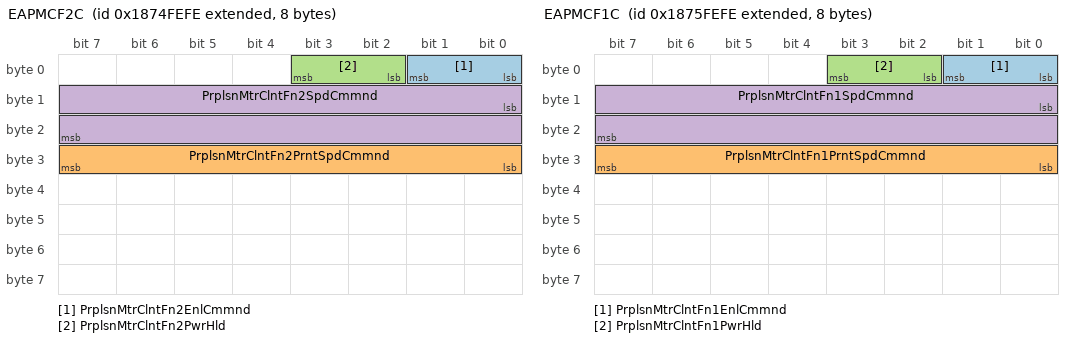
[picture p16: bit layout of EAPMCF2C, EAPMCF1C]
BO_ 2557804286 EAPMCF2C: 8 Vector__XXX
 SG_ PrplsnMtrClntFn2EnlCmmnd : 0|2@1+ (1,0) [0|3] "" Vector__XXX
 SG_ PrplsnMtrClntFn2PrntSpdCmmnd : 24|8@1+ (0.5,0) [0|125] "%" Vector__XXX
 SG_ PrplsnMtrClntFn2PwrHld : 2|2@1+ (1,0) [0|3] "" Vector__XXX
 SG_ PrplsnMtrClntFn2SpdCmmnd : 8|16@1+ (0.5,0) [0|32127.5] "rpm" Vector__XXX

BO_ 2557869822 EAPMCF1C: 8 Vector__XXX
 SG_ PrplsnMtrClntFn1EnlCmmnd : 0|2@1+ (1,0) [0|3] "" Vector__XXX
 SG_ PrplsnMtrClntFn1PrntSpdCmmnd : 24|8@1+ (0.5,0) [0|125] "%" Vector__XXX
 SG_ PrplsnMtrClntFn1PwrHld : 2|2@1+ (1,0) [0|3] "" Vector__XXX
 SG_ PrplsnMtrClntFn1SpdCmmnd : 8|16@1+ (0.5,0) [0|32127.5] "rpm" Vector__XXX

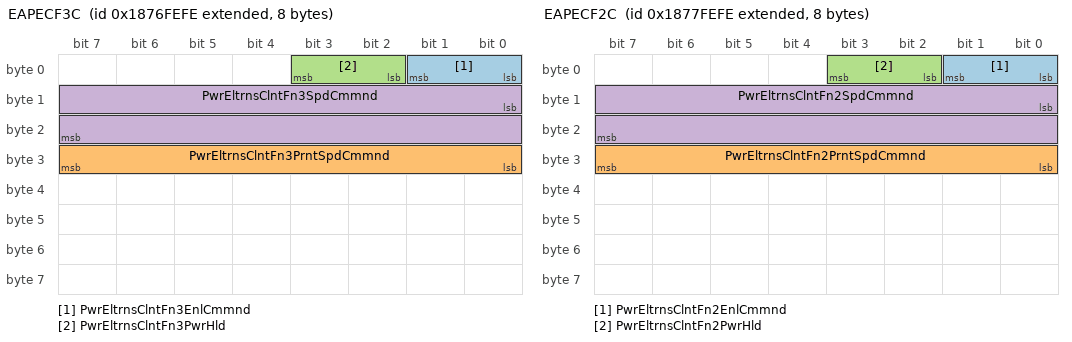
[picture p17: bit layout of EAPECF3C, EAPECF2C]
BO_ 2557935358 EAPECF3C: 8 Vector__XXX
 SG_ PwrEltrnsClntFn3EnlCmmnd : 0|2@1+ (1,0) [0|3] "" Vector__XXX
 SG_ PwrEltrnsClntFn3PrntSpdCmmnd : 24|8@1+ (0.5,0) [0|125] "%" Vector__XXX
 SG_ PwrEltrnsClntFn3PwrHld : 2|2@1+ (1,0) [0|3] "" Vector__XXX
 SG_ PwrEltrnsClntFn3SpdCmmnd : 8|16@1+ (0.5,0) [0|32127.5] "rpm" Vector__XXX

BO_ 2558000894 EAPECF2C: 8 Vector__XXX
 SG_ PwrEltrnsClntFn2EnlCmmnd : 0|2@1+ (1,0) [0|3] "" Vector__XXX
 SG_ PwrEltrnsClntFn2PrntSpdCmmnd : 24|8@1+ (0.5,0) [0|125] "%" Vector__XXX
 SG_ PwrEltrnsClntFn2PwrHld : 2|2@1+ (1,0) [0|3] "" Vector__XXX
 SG_ PwrEltrnsClntFn2SpdCmmnd : 8|16@1+ (0.5,0) [0|32127.5] "rpm" Vector__XXX

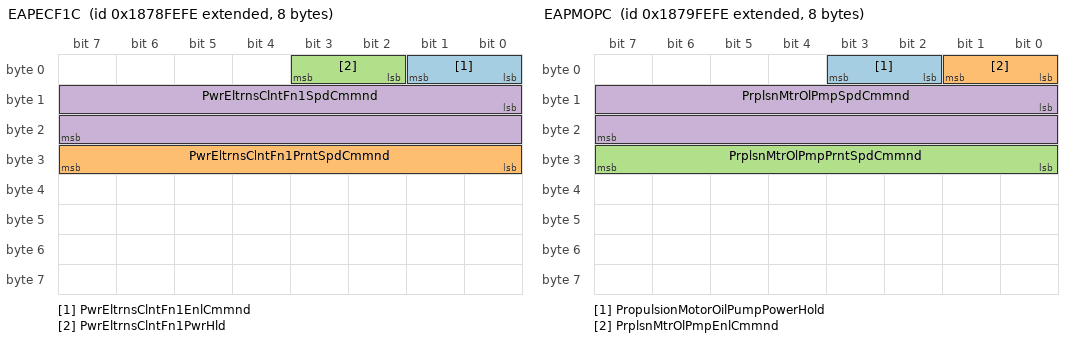
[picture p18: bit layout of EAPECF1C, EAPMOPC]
BO_ 2558066430 EAPECF1C: 8 Vector__XXX
 SG_ PwrEltrnsClntFn1EnlCmmnd : 0|2@1+ (1,0) [0|3] "" Vector__XXX
 SG_ PwrEltrnsClntFn1PrntSpdCmmnd : 24|8@1+ (0.5,0) [0|125] "%" Vector__XXX
 SG_ PwrEltrnsClntFn1PwrHld : 2|2@1+ (1,0) [0|3] "" Vector__XXX
 SG_ PwrEltrnsClntFn1SpdCmmnd : 8|16@1+ (0.5,0) [0|32127.5] "rpm" Vector__XXX

BO_ 2558131966 EAPMOPC: 8 Vector__XXX
 SG_ PropulsionMotorOilPumpPowerHold : 2|2@1+ (1,0) [0|3] "" Vector__XXX
 SG_ PrplsnMtrOlPmpEnlCmmnd : 0|2@1+ (1,0) [0|3] "" Vector__XXX
 SG_ PrplsnMtrOlPmpPrntSpdCmmnd : 24|8@1+ (0.5,0) [0|125] "%" Vector__XXX
 SG_ PrplsnMtrOlPmpSpdCmmnd : 8|16@1+ (0.5,0) [0|32127.5] "rpm" Vector__XXX

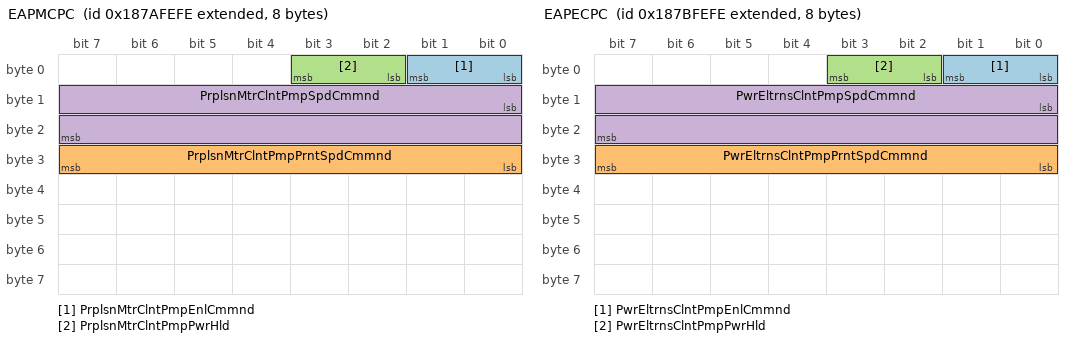
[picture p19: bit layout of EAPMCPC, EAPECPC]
BO_ 2558197502 EAPMCPC: 8 Vector__XXX
 SG_ PrplsnMtrClntPmpEnlCmmnd : 0|2@1+ (1,0) [0|3] "" Vector__XXX
 SG_ PrplsnMtrClntPmpPrntSpdCmmnd : 24|8@1+ (0.5,0) [0|125] "%" Vector__XXX
 SG_ PrplsnMtrClntPmpPwrHld : 2|2@1+ (1,0) [0|3] "" Vector__XXX
 SG_ PrplsnMtrClntPmpSpdCmmnd : 8|16@1+ (0.5,0) [0|32127.5] "rpm" Vector__XXX

BO_ 2558263038 EAPECPC: 8 Vector__XXX
 SG_ PwrEltrnsClntPmpEnlCmmnd : 0|2@1+ (1,0) [0|3] "" Vector__XXX
 SG_ PwrEltrnsClntPmpPrntSpdCmmnd : 24|8@1+ (0.5,0) [0|125] "%" Vector__XXX
 SG_ PwrEltrnsClntPmpPwrHld : 2|2@1+ (1,0) [0|3] "" Vector__XXX
 SG_ PwrEltrnsClntPmpSpdCmmnd : 8|16@1+ (0.5,0) [0|32127.5] "rpm" Vector__XXX

CM_ BO_ 2365484286 "Tachograph";
CM_ SG_ 2365484286 Directionindicator "Direction indicator: Indicates the direction of the vehicle.00b = Forward01b = Reverse10b = Error11b = Not available";
CM_ SG_ 2365484286 Driver1TimeRelatedStates "Driver 1 Time Related States: Indicates if the driver approaches or exceeds working time limits (or other limits).  0000b = Normal/No limits reached0001b = Limit #1 – 15 min before 4 ½ h0010b = Limit #2 – 4 ½ h reached0011b = Limit #3 – 15 min before...";
CM_ SG_ 2365484286 Driver1workingstate "Driver 1 working state: State of work of the driver.  000b = Rest - sleeping001b = Driver available – short break010b = Work – loading, unloading, working in an office011b = Drive – behind wheel 100b = Reserved101b = Reserved110b = Error111b = Not av...";
CM_ SG_ 2365484286 Driver2TimeRelatedStates "Driver 2 Time Related States: Indicates if the driver approaches or exceeds working time limits (or other limits).  0000b = Normal/No limits reached0001b = Limit #1 – 15 min before 4 ½ h0010b = Limit #2 – 4 ½ h reached0011b = Limit #3 – 15 min before...";
CM_ SG_ 2365484286 Driver2workingstate "Driver 2 working state: State of work of the driver.  000b = Rest - sleeping001b = Driver available – short break010b = Work – loading, unloading, working in an office011b = Drive – behind wheel 100b = Reserved101b = Reserved110b = Error111b = Not av...";
CM_ SG_ 2365484286 Drivercarddriver1 "Driver card, driver 1: Indicates the presence of a driver card00b = Driver card not present01b = Driver card present10b = Error11b = Not available";
CM_ SG_ 2365484286 Drivercarddriver2 "Driver card, driver 2: Indicates the presence of a driver card00b = Driver card not present01b = Driver card present10b = Error11b = Not available";
CM_ SG_ 2365484286 Handlinginformation "Handling information: Indicates that handling information is present.  Information could include no printer paper, no driver card, etc.00b = No handling information01b = Handling information10b = Error11b = Not available";
CM_ SG_ 2365484286 Systemevent "System event: Indicates that a tachograph event has occurred.  This may include power supply interruption, interruption of the speed sensor, incorrect data on the driver card, driving without a driver card, illegal removal of a driver card, insertion...";
CM_ SG_ 2365484286 Tachographoutputshaftspeed "Tachograph output shaft speed: Calculated speed of the transmission output shaft.";
CM_ SG_ 2365484286 Tachographperformance "Tachograph performance: Indicates the tachograph performance; including electronic or mechanical analysis, instrument analysis, speed sensor analysis, mass storage analysis, and printer analysis.00b = Normal performance01b = Performance analysis10b =...";
CM_ SG_ 2365484286 Tachographvehiclespeed "Tachograph vehicle speed: Speed of the vehicle registered by the tachograph.";
CM_ SG_ 2365484286 Vehiclemotion "Vehicle motion: Indicates whether motion of the vehicle is detected or not.00b = Vehicle motion not detected01b = Vehicle motion detected10b = Error11b = Not available";
CM_ SG_ 2365484286 VehicleOverspeed "Vehicle Overspeed: Indicates whether the vehicle is exceeding the legal speed limit set in the tachograph.00b = No overspeed01b = Overspeed10b = Error11b = Not available";
CM_ BO_ 2365485566 "Laser Tracer Position";
CM_ SG_ 2365485566 LaserTracerHorizontalDeviation "Laser Tracer Horizontal Deviation: The calculated percent deviation between the target distance and the center of the laser tracer.The values 0 to 99% indicates target is left of center, 101 to 200% indicates  target is right of center, 100% indicate...";
CM_ SG_ 2365485566 LaserTracerInformation "Laser Tracer Information: Provides the status of the laser tracer to the operator. 00000001b = Laser power is on00000010b = Laser is ready00000100b = Valid target (1 = yes)00001000b = Previous pass (1 = yes)00010000b = Stringline (1 = yes)00100000b =...";
CM_ SG_ 2365485566 LaserTracerTargetDeviation "Laser Tracer Target Deviation: The calculated distance for the laser target to the current laser tracer reference point.Negative values are below setpoint, positive values are above setpoint, zero is on grade.Parameter specific parameter: FE03h indic...";
CM_ SG_ 2365485566 LaserTracerVerticalDistance "Laser Tracer Vertical Distance: The elevation of the laser tracer sensor in a laser leveling system.";
CM_ SG_ 2365485566 LEDDisplayData2 "LED Display Data #2: Informs display devices how to display the current position of the laser tracer.Values which are less than 128 decimal are bit-mapped values and any combination of these values is considered a valid value.  For example communicat...";
CM_ BO_ 2365485822 "Laser Leveling System Blade Control";
CM_ SG_ 2365485822 BladeControlMode "Blade Control Mode: Allows the user to select the type of blade control for the land leveling system.  00000000b = Manual mode00000001b = Automatic mode00000010b = Inactive automatic modeAll other values Reserved";
CM_ SG_ 2365485822 BladeControlModeLeft "Blade Control Mode - Left: Indicate if the land leveling system's automatic control is active or inactive for the elevation sensor on the left side of the blade.  The left notation is applicable to grading machines such tractors and motor graders whe...";
CM_ SG_ 2365485822 BladeControlModeRight "Blade Control Mode - Right: Indicate if the land leveling system's automatic control is active or inactive for the elevation sensor on the right side of the blade.  The left notation is applicable to grading machines such tractors and motor graders w...";
CM_ SG_ 2365485822 BladeDurationandDirection "Blade Duration and Direction: Used to indicate the duration and direction that the land leveling system blade moves.Negative values indicate move the blade up, positive values indicate move the blade down, zero indicates no change.";
CM_ SG_ 2365485822 LandLevelingSystemEnableStatus "Land Leveling System Enable Status: Communicate the enable/disable status of the Land Leveling System.00b = Disabled01b = Enabled10b = Error11b = Not available / Not installed";
CM_ BO_ 2365486078 "Laser Receiver Mast Position";
CM_ SG_ 2365486078 MastPosition "Mast Position: Used to monitor the position of the sensor attached to the land leveling mast.Negative values indicate below current position, positive values are above current position, zero indicates no change.";
CM_ BO_ 2365486334 "Modify Leveling System Control Set Point";
CM_ SG_ 2365486334 BldHghtStPntHghRsltn "Blade Height Set Point (High Resolution): High resolution for the laser guided blade set point.  The high resolution required for more accurate control and 'accurate' unit conversions.Negative values are below grade, positive values are above grade, ...";
CM_ SG_ 2365486334 ModifyLevelingSystemSetPoint "Modify Leveling System Set Point: Used to control and coordinate the set point for the leveling system.Operating Range: -3200 to +3200 mm, negative values are below current position, positive values are above current position, zero is no change.Param...";
CM_ BO_ 2365486590 "Laser Leveling System Vertical Deviation";
CM_ SG_ 2365486590 AbsoluteLaserStrikePosition "Absolute Laser Strike Position: Laser Strike location on the survey type  laser receiver.";
CM_ SG_ 2365486590 LaserReceiverType "Laser Receiver Type: Identifies which type of Laser Receiver transmitted the message.0 = Reserved 1 = Linear Laser Receiver2 = 1 Meter Survey Receiver3 = 2 Meter Survey Receiver4 = 2.5 Meter Survey Receiver5 to 250 = Reserved";
CM_ SG_ 2365486590 LaserStrikeDataLatency "Laser Strike Data Latency: Time from laser strike to CAN message transmission.  This parameter will be reported by survey receiver type devices only. Byte 3 (SPN 2576) of  PGN 65141 identifies the type of Laser Receiver.";
CM_ SG_ 2365486590 LaserStrikeVerticalDeviation "Laser Strike Vertical Deviation: The calculated distance from the laser strike position to the current land leveling system reference point.Negative values indicate below grade, positive values are above grade, zero is on gradeParameter specific para...";
CM_ BO_ 2431649790 "Forward Lane Image 1";
CM_ SG_ 2431649790 DriverAlertnessWarning "Driver Alertness Warning: Indicates when a distracted driving condition is detected. This signal can be used independent of the technology and ECU used to estimate the distracted driver condition.000b = No distracted driving condition detected001b = ...";
CM_ SG_ 2431649790 LaneDepartureImminentLeftSide "Lane Departure Imminent, Left Side: Indicates departure imminent on left side of lane.00b = Not imminent01b = Imminent10b = Reserved11b = Not used";
CM_ SG_ 2431649790 LaneDepartureImminentRightSide "Lane Departure Imminent, Right Side: Indicates departure imminent on right side of lane.00b = Not imminent01b = Imminent10b = Reserved11b = Not Used";
CM_ SG_ 2431649790 LaneDepartureLeft "Lane Departure Left: Indicates that the middle of vehicle departs the lane on the left side. The parameter indicates that the vehicle is changing the lane to the left.00b = Middle of the vehicle does not depart the lane to the left side01b = Middle o...";
CM_ SG_ 2431649790 LaneDepartureRight "Lane Departure Right: Indicates that the middle of vehicle departs the lane on the right side. The parameter indicates that the vehicle is changing the lane to the right.00b = Middle of the vehicle does not depart the lane to the right side01b = Midd...";
CM_ SG_ 2431649790 LftSdLnDprtrAstlWrnngCmmnd "Left Side Lane Departure Acoustical Warning Command: Indicates that the forward lane imaging system is commanding an acoustical warning for the lane departure on the left side of the vehicle.Used for driving acoustical alert devices with minimal inte...";
CM_ SG_ 2431649790 LftSdLnDprtrOptlWrnngCmmnd "Left Side Lane Departure Optical Warning Command: Indicates that the forward lane imaging system is commanding an optical warning for the lane departure on the left side of the vehicle.Used for driving optical alert devices with minimal internal logi...";
CM_ SG_ 2431649790 RghtSdLnDprtrAstlWrnngCmmnd "Right Side Lane Departure Acoustical Warning Command: Indicates that the forward lane imaging system is commanding an acoustical warning for the lane departure on the right side of the vehicle.Used for driving acoustical alert devices with minimal in...";
CM_ SG_ 2431649790 RghtSdLnDprtrOptlWrnngCmmnd "Right Side Lane Departure Optical Warning Command: Indicates that the forward lane imaging system is commanding an optical warning for the lane departure on the right side of the vehicle.Used for driving optical alert devices with minimal internal lo...";
CM_ SG_ 2431649790 RghtSdLnDprtrHptWrnngCmmnd "Right Side Lane Departure Haptic Warning Command: Indicates that the forward lane imaging system is commanding an haptic warning for the lane departure on the right side of the vehicle.Used for driving haptic alert devices with minimal internal logic...";
CM_ SG_ 2431649790 LftSdLnDprtrHptWrnngCmmnd "Left Side Lane Departure Haptic Warning Command: Indicates that the forward lane imaging system is commanding an haptic warning for the lane departure on the left side of the vehicle.Used for driving haptic alert devices with minimal internal logic (...";
CM_ BO_ 2431654654 "Engine Throttle / Fuel Actuator Control Command";
CM_ SG_ 2431654654 EngnFlAttr1CntrlCmmnd "Engine Fuel Actuator 1 Control Command: The control command to fuel actuator 1, normalized to percent, where 0% represents fully closed and 100% represents fully open. In applications where the fuel actuator controls to differential pressure, 0% repr...";
CM_ SG_ 2431654654 EngnFlAttr2CntrlCmmnd "Engine Fuel Actuator 2 Control Command: The control command to fuel actuator 2, normalized to percent, where 0% represents fully closed and 100% represents fully open. Typically, this fuel actuator is used to regulate low pressure natural gas flow ra...";
CM_ SG_ 2431654654 EngnThrttlAttr1CntrlCmmnd "Engine Throttle Actuator 1 Control Command: The control command to throttle actuator 1, normalized to percent, where 0% represents fully closed and 100% represents fully open.  Typically, this throttle actuator is used to regulate air or air / fuel m...";
CM_ SG_ 2431654654 EngnThrttlAttr2CntrlCmmnd "Engine Throttle Actuator 2 Control Command: The control command to throttle actuator 2, normalized to percent, where 0% represents fully closed and 100% represents fully open.  Typically, this throttle actuator is used to regulate air or air / fuel m...";
CM_ BO_ 2431661054 "Aftertreatment 1 SCR Ammonia Information 2";
CM_ SG_ 2431661054 Aftrtrtmnt1SCRIntrmdtNH3 "Aftertreatment 1 SCR Intermediate NH3: The amount of NH3 in the exhaust aftertreatment system measured by a NH3 sensor at an intermediate point in the SCR system, represented in NH3 molecule parts per million non-NH3 molecules in exhaust bank 1.";
CM_ SG_ 2431661054 Aftrtrtmnt1SCRIntrmdtNH3RdngStl "Aftertreatment 1 SCR Intermediate NH3 Reading Stable: Indicates that the NH3 reading of the aftertreatment SCR intermediate NH3 sensor is stable as determined by the manufacturer's control software in exhaust bank 1.00b = Reading is not stable01b = R...";
CM_ SG_ 2431661054 Atttt1SCRItdtNH3SsHtCt "Aftertreatment 1 SCR Intermediate NH3 Sensor Heater Control: Indicates the heater status in the warm-up process. Upon receiving a power-up command, the NH3 sensor ramps up according to a manufacturer defined profile. The Preheat 1, Preheat 2, and Aut...";
CM_ SG_ 2431661054 Atttt1SCRItdtNH3SsHtPFMI "Aftertreatment 1 SCR Intermediate NH3 Sensor Heater Preliminary FMI: Used to identify the applicable J1939-73 FMI detected in the heater of the outlet NH3 exhaust sensor by the manufacturer’s sensor control software in exhaust bank 1. In the case of ...";
CM_ SG_ 2431661054 Atttt1SCRItdtNH3SsPFMI "Aftertreatment 1 SCR Intermediate NH3 Sensor Preliminary FMI: Used to identify the applicable J1939-73 FMI detected in the aftertreatment SCR intermediate NH3 sensor by the manufacturer’s sensor control software in exhaust bank 1. In the case of mult...";
CM_ SG_ 2431661054 Atttt1SCRItdtNH3SsPwIR "Aftertreatment 1 SCR Intermediate NH3 Sensor Power In Range: Indicates that the power supplied to the aftertreatment SCR intermediate NH3 sensor is within the manufacturer's specification in exhaust bank 1.00b = Power is not in range01b = Power is in...";
CM_ SG_ 2431661054 Atttt1SCRItdtNH3SstTpt "Aftertreatment 1 SCR Intermediate NH3 Sensor at Temperature: Indicates that the heater element of the aftertreatment SCR intermediate NH3 sensor is within the manufacturer's specified range for accurate measurements in exhaust bank 1.00b = Heater ele...";
CM_ BO_ 2431661310 "Aftertreatment 2 SCR Ammonia Information 2";
CM_ SG_ 2431661310 Aftrtrtmnt2SCRIntrmdtNH3 "Aftertreatment 2 SCR Intermediate NH3: The amount of NH3 in the exhaust aftertreatment system measured by a NH3 sensor at an intermediate point in the SCR system, represented in NH3 molecule parts per million non-NH3 molecules in exhaust bank 2.";
CM_ SG_ 2431661310 Aftrtrtmnt2SCRIntrmdtNH3RdngStl "Aftertreatment 2 SCR Intermediate NH3 Reading Stable: Indicates that the NH3 reading of the aftertreatment SCR intermediate NH3 sensor is stable as determined by the manufacturer's control software in exhaust bank 2.00b = Reading is not stable01b = R...";
CM_ SG_ 2431661310 Atttt2SCRItdtNH3SsHtCt "Aftertreatment 2 SCR Intermediate NH3 Sensor Heater Control: Indicates the heater status in the warm-up process. Upon receiving a power-up command, the NH3 sensor ramps up according to a manufacturer defined profile. The Preheat 1, Preheat 2, and Aut...";
CM_ SG_ 2431661310 Atttt2SCRItdtNH3SsHtPFMI "Aftertreatment 2 SCR Intermediate NH3 Sensor Heater Preliminary FMI: Used to identify the applicable J1939-73 FMI detected in the heater of the SCR intermediate NH3 exhaust sensor by the manufacturer’s sensor control software in exhaust bank 2. In th...";
CM_ SG_ 2431661310 Atttt2SCRItdtNH3SsPFMI "Aftertreatment 2 SCR Intermediate NH3 Sensor Preliminary FMI: Used to identify the applicable J1939-73 FMI detected in the aftertreatment SCR intermediate NH3 sensor by the manufacturer’s sensor control software in exhaust bank 2. In the case of mult...";
CM_ SG_ 2431661310 Atttt2SCRItdtNH3SsPwIR "Aftertreatment 2 SCR Intermediate NH3 Sensor Power In Range: Indicates that the power supplied to the aftertreatment SCR intermediate NH3 sensor is within the manufacturer's specification in exhaust bank 2.00b = Heater element is not in range01b = He...";
CM_ SG_ 2431661310 Atttt2SCRItdtNH3SstTpt "Aftertreatment 2 SCR Intermediate NH3 Sensor at Temperature: Indicates that the heater element of the aftertreatment SCR intermediate NH3 sensor is within the manufacturer's specified range for accurate measurements in exhaust bank 2.00b = Heater ele...";
CM_ BO_ 2431708670 "Engine Start Control";
CM_ SG_ 2431708670 EngineStartAbortRequest "Engine Start Abort Request: Indicates the sender's desire to abort an engine start. This signal is used by requesters and consenters to request that the arbitrator cancel an engine start that is in progress.The sender of this signal may increase the ...";
CM_ SG_ 2431708670 EngineStartConsent "Engine Start Consent: Indicates the sender's consent to start the engine for different start types. An operator-requested engine start is a start that is initiated directly by the operator (i.e. via the key switch). An automatic engine start is one t...";
CM_ SG_ 2431708670 EngineStartControlChecksum "Engine Start Control Checksum: Checksum to allow detection of data integrity issues. The receiving node shall calculate the checksum and compare its calculated value with the received checksum. In case of a mismatch the message shall be discarded.The...";
CM_ SG_ 2431708670 EngineStarter1Feedback "Engine Starter 1 Feedback: Feedback of the current state of first engine starter. This signal is intended to be used by the arbitrator as feedback to its command signal (SPN 7753).Additional details regarding the starter state may be available in SPN...";
CM_ SG_ 2431708670 EngineStarter2Feedback "Engine Starter 2 Feedback: Feedback of the current state of second engine starter. This signal is intended to be used by the arbitrator as feedback to its command signal (SPN 7753).Additional details regarding the starter state may be available in SP...";
CM_ SG_ 2431708670 EngineStartRequest "Engine Start Request: Indicates the sender's desire to start the engine. The engine start arbitrator latches this signal and, if possible, completes the engine start regardless of a change of state of this signal. Use Engine Start Abort Request (SPN ...";
CM_ SG_ 2431708670 EngnStrtCntrlMssgCntr "Engine Start Control Message Counter: Message counter to allow detection of data integrity issues. The counter is incremented every time a device sends out the Engine Start Control message. When the counter has reached a value of 15 it starts over at...";
CM_ SG_ 2431708670 TrnsmssnShftSltrRqstdVhlDrtn "Transmission Shift Selector Requested Vehicle Direction: This parameter indicates the direction selected by the operator via the active transmission shift selector.Some regulations (e.g., Federal Motor Vehicle Safety Standards 102) require specific E...";
CM_ BO_ 2431710718 "Engine Start Arbitrator";
CM_ SG_ 2431710718 AtmtEngnStrtCnsntSmmr "Automatic Engine Start Consent Summary: Arbitrator's summary of the consent statuses of all devices which the arbitrator considers for automatic start requests. The purpose of this parameter is for requesters to determine if an automatic start reques...";
CM_ SG_ 2431710718 EngineStartArbitratorChecksum "Engine Start Arbitrator Checksum: Checksum to allow detection of data integrity issues. The receiving node shall calculate the checksum and compare its calculated value with the received checksum. In case of a mismatch the message shall be discarded....";
CM_ SG_ 2431710718 EngineStartControlMessageRate "Engine Start Control Message Rate: This signal is sent by the arbitrator to control the rate at which other participants send the Engine Start Control Message (ENGSC). The arbitrator sets this signal to the slower rate after the first engine start at...";
CM_ SG_ 2431710718 EngineStarterCommand "Engine Starter Command: Command from the arbitrator to the engine starter controller(s).The arbitrator takes input from consenters and requesters to initiate an engine start. This signal is used by the arbitrator to command the first or second starte...";
CM_ SG_ 2431710718 EngineStartRequestLatchStatus "Engine Start Request Latch Status: Indicates the arbitrator's latch status for engine start requests. All unlatched states shall transition to state 0 – Start Request not received after 1000 ms unless a different state becomes more appropriate in the...";
CM_ SG_ 2431710718 EngnStrtArtrtrMssgCntr "Engine Start Arbitrator Message Counter: Message counter to allow detection of data integrity issues. The counter is incremented every time a device sends out the Engine Start Control message. When the counter has reached a value of 15 it starts over...";
CM_ SG_ 2431710718 OprtrEngnStrtCnsntSmmr "Operator Engine Start Consent Summary: Arbitrator's summary of the consent statuses of all devices which the arbitrator considers for operator start requests. The purpose of this parameter is for requesters to determine if an operator start request w...";
CM_ BO_ 2431717886 "Gaseous Fuel Pressure 3";
CM_ SG_ 2431717886 EngnFlVlv1DffrntlPrssrHghRsltn "Engine Fuel Valve 1 Differential Pressure (High Resolution): The differential pressure between the intake and the outlet of the first or only gaseous fuel valve.See SPN 1391 for alternate range and resolution.";
CM_ SG_ 2431717886 EngnGssFlSpplFltrDffrntlPrssr "Engine Gaseous Fuel Supply Filter Differential Pressure: Change in gaseous fuel delivery pressure, measured across the filter, due to accumulation of solid or semisolid matter on the filter element.";
CM_ SG_ 2431717886 EngnGssFlSpplFltrIntkPrssr "Engine Gaseous Fuel Supply Filter Intake Pressure: Pressure of gaseous fuel supply measured at the intake of gaseous fuel supply filter.";
CM_ BO_ 2431719166 "Well Stimulation Pump System 3";
CM_ SG_ 2431719166 WellStimulationPumpFlowRate "Well Stimulation Pump Flow Rate: The amount of fluid that is being pumped by the well stimulation pump.";
CM_ SG_ 2431719166 WellStimulationPumpRodLoad "Well Stimulation Pump Rod Load: The load on the plungers of the well stimulation pump.";
CM_ SG_ 2431719166 WllStmltnPmpCvttnStts "Well Stimulation Pump Cavitation Status: Indicates the level of cavitation detected on the well stimulation pump.000b = No Cavitation001b = Low010b = Medium011b = High100b = Reserved101b = Reserved110b = Error111b = Not Available";
CM_ SG_ 2431719166 WllStmltnPmpFldEndVlvLk "Well Stimulation Pump Fluid End Valve Leak: Indicates the leakage detected in the well stimulation pump fluid end.00b = No Leak Detected01b = Leak Detected10b = Error11b = Not Available";
CM_ SG_ 2431719166 WllStmltnPmpRtdRdLdPrnt "Well Stimulation Pump Rated Rod Load Percent: Parameter which represents the ratio of the calculated rod load (reference SPN 8648) divided by the rated rod load of the pump * 100.";
CM_ BO_ 2432471038 "Alternate Fuel 3";
CM_ SG_ 2432471038 EngnFlVprzr1DshrgTmprtr "Engine Fuel Vaporizer 1 Discharge Temperature: The temperature of the fuel in its gaseous state at the outlet of the first fuel vaporizer";
CM_ SG_ 2432471038 EngnGssFlSpplPrssr1ExtnddRng "Engine Gaseous Fuel Supply Pressure 1 (Extended Range): Pressure of gaseous fuel supply to fuel metering device in systems where the pressure range defined for SPN 159 is not sufficient.";
CM_ SG_ 2432471038 GssFlAmltrTmprtr "Gaseous Fuel Accumulator Temperature: Gaseous fuel temperature at the outlet of the Gas Filter.";
CM_ SG_ 2432471038 EGssFSppPssRtCtCd "Engine Gaseous Fuel Supply Pressure Regulator Control Command: The command to the fuel pressure regulator which regulates the pressure of gaseous fuel supply to the engine. This command is normalized to percent, where 0% nominally represents fully cl...";
CM_ BO_ 2432492542 "Engine Exhaust Brake Control";
CM_ SG_ 2432492542 EngnExhstBrkAttrCmmnd "Engine Exhaust Brake Actuator Command: The control command applied to the engine exhaust brake actuator, where 0% represents no braking and 100% represents full braking.";
CM_ SG_ 2432492542 EngnTrhrgr1TrnDsrdOtltPrssr "Engine Turbocharger 1 Turbine Desired Outlet Pressure: The desired gage pressure of the combustion by-products exiting the turbine side of the turbocharger 1 at the current engine operating conditions.";
CM_ SG_ 2432492542 EngnTrhrgr1TrnOtltPrssr "Engine Turbocharger 1 Turbine Outlet Pressure: Gage pressure of the combustion by-products exiting the turbine side of the turbocharger 1.";
CM_ SG_ 2432492542 EngnTrhrgr2TrnDsrdOtltPrssr "Engine Turbocharger 2 Turbine Desired Outlet Pressure: The desired gage pressure of the combustion by-products exiting the turbine side of the turbocharger 2 at the current engine operating conditions.";
CM_ SG_ 2432492542 EngnTrhrgr2TrnOtltPrssr "Engine Turbocharger 2 Turbine Outlet Pressure: Gage pressure of the combustion by-products exiting the turbine side of the turbocharger 2.";
CM_ BO_ 2432499198 "Electronic Engine Controller 9";
CM_ SG_ 2432499198 CmmnddEngnFlInjtnCntrlPrssr "Commanded Engine Fuel Injection Control Pressure: Provides the commanded set point value for the engine fuel injection control pressure.";
CM_ SG_ 2432499198 CommandedEngineFuelRailPressure "Commanded Engine Fuel Rail Pressure: Provides the commanded set point value for the engine fuel rail gage pressure";
CM_ SG_ 2432499198 EngnExhstGsRrltn2Vlv2Pstn "Engine Exhaust Gas Recirculation 2 Valve 2 Position: The position of the second exhaust gas recirculation valve of EGR 2 expressed as a percentage of full travel. 0% means the valve is closed and no exhaust gas is flowing into the air stream. 100% me...";
CM_ SG_ 2432499198 EngnExhstGsRrltn2VlvPstn "Engine Exhaust Gas Recirculation 2 Valve Position: Position of EGR2 valve expressed as a percentage of full travel. 0% means the valve is closed and no exhaust gas is flowing into the air stream. 100% means the valve is fully opened.";
CM_ BO_ 2432520702 "Aftercooler Coolant Control Valve Command";
CM_ SG_ 2432520702 AftrlrClntThrmsttMd "Aftercooler Coolant Thermostat Mode: Specifies if the aftercooler coolant thermostat valve will operate in temperature control mode or position control mode.00b = temperature control mode01b = position control mode (used for service only)10b = reserv...";
CM_ SG_ 2432520702 DsrdAftrlrClntIntkTmprtr "Desired Aftercooler Coolant Intake Temperature: Indicates the desired temperature of the fluid in the low temperature aftercooler circuit to an electronic thermostat.  If the aftercooler coolant thermostat valve is operating in position control mode ...";
CM_ SG_ 2432520702 DsrdAftrlrClntThrmsttOpnng "Desired Aftercooler Coolant Thermostat Opening: Used to transmit the desired position of the low temperature aftercooler temperature control valve.  0% represents the thermostat allows flow to completely bypass the aftercooler and 100% represents the...";
CM_ SG_ 2432520702 EngnChrgArClrBpssVlv1Cmmnd "Engine Charge Air Cooler Bypass Valve 1 Command: Desired percentage of charge air cooler Bypass Valve 1 opening. 0% means no air is bypassed. 100% means full bypass capacity.";
CM_ SG_ 2432520702 EngnChrgArClrBpssVlv2Cmmnd "Engine Charge Air Cooler Bypass Valve 2 Command: Desired percentage of charge air cooler Bypass Valve 2 opening. 0% means no air is bypassed. 100% means full bypass capacity.";
CM_ BO_ 2432520958 "Engine Coolant Control Valve Command";
CM_ SG_ 2432520958 DsrdEngnClntPmpOtltTmprtr "Desired Engine Coolant Pump Outlet Temperature: Desired engine coolant temperature of the engine to an electronic thermostat.  If the electronic thermostat valve is operating in position control mode (see SPN 4195)  then transmit FFh.";
CM_ SG_ 2432520958 DsrdEngnClntThrmsttOpnng "Desired Engine Coolant Thermostat Opening: Indicates the desired position of the engine coolant control valve.   0% represents the thermostat allows flow to completely bypass the radiator and 100% represents the flow is fully through the radiator.  I...";
CM_ SG_ 2432520958 EngineCoolantThermostatMode "Engine Coolant Thermostat Mode: Specifies if the engine coolant thermostat valve will operate in temperature control mode or position control mode.00b = temperature control mode01b = position control mode (used for service only)10b = reserved11b = do...";
CM_ SG_ 2432520958 EngnAxlrClrSpplVlv1AttrCmmnd "Engine Auxiliary Cooler Supply Valve 1 Actuator Command: The control command applied to the engine auxiliary cooler supply valve 1 actuator, where 0% represents closed and 100% represents open.See SPN 4197 for primary engine thermostat valve.";
CM_ SG_ 2432520958 EngnAxlrClrSpplVlv2AttrCmmnd "Engine Auxiliary Cooler Supply Valve 2 Actuator Command: The control command applied to the engine auxiliary cooler supply valve 2 actuator, where 0% represents closed and 100% represents open.";
CM_ BO_ 2432541438 "Fuel Information 3 (Gaseous)";
CM_ SG_ 2432541438 EngineFuel1Temperature2 "Engine Fuel 1 Temperature 2: Second Temperature measurement of fuel (or gas) of the first fuel type. See SPN 174 for first fuel temperature measurement.";
CM_ SG_ 2432541438 EngnFlSstm2GsMssFlwRt "Engine Fuel System 2 Gas Mass Flow Rate: Gas mass flow rate delivered to an engine through its second fuel control system, using standard convention for determining position.In a system with two fuel system control valves, left/front is #1 (SPN 1241)...";
CM_ SG_ 2432541438 EngnFlVlv2IntkAsltPrssr "Engine Fuel Valve 2 Intake Absolute Pressure: Absolute pressure of gas on intake side of the second fuel system control valve, using standard convention for determining position.In a system with two fuel system control valves, left/front is #1 (SPN 1...";
CM_ SG_ 2432541438 EngnFlVlv2OtltAsltPrssr "Engine Fuel Valve 2 Outlet Absolute Pressure: Absolute pressure of gas on outlet side of the second fuel system control valve.  See SPN 2980 for the first or only fuel system control valve.";
CM_ BO_ 2432541694 "Electronic Engine Controller 6";
CM_ SG_ 2432541694 EngnTrhrgrCmprssrBpssAttr1Cmmnd "Engine Turbocharger Compressor Bypass Actuator 1 Command: The command to a compressor bypass actuator, normalized to percent, where 0% nominally represents fully closed and 100% represents fully open.  Typically, the turbocharger compressor bypass ac...";
CM_ SG_ 2432541694 EngnTrhrgrCmprssrBpssAttr1Pstn "Engine Turbocharger Compressor Bypass Actuator 1 Position: Measures the position of the turbocharger compressor bypass actuator, where 0% represents bypass fully closed and 100% represents bypass fully open.  Typically, the compressor bypass is used ...";
CM_ SG_ 2432541694 EngnTrhrgrCmprssrBpssAttr2Cmmnd "Engine Turbocharger Compressor Bypass Actuator 2 Command: The command to a compressor bypass actuator 2, normalized to percent, where 0% nominally represents fully closed and 100% represents fully open. Typically, the turbocharger compressor bypass a...";
CM_ SG_ 2432541694 EngnVrlGmtrTrhrgrAttr1 "Engine Variable Geometry Turbocharger Actuator #1: Actuator that controls the variable geometry turbocharger geometry.The control command to the actuator, normalized to percent, where 0% nominally represents fully closed (smallest turbocharger geomet...";
CM_ SG_ 2432541694 ETCpssBpssAtt1DsdPst "Engine Turbocharger Compressor Bypass Actuator 1 Desired Position: The requested position of the Engine Turbocharger Compressor Bypass actuator by the engine ECU, where 0% represents bypass fully closed and 100% represents bypass fully open.This is t...";
CM_ SG_ 2432541694 ETCpssBpssAtt1PFMI "Engine Turbocharger Compressor Bypass Actuator 1 Preliminary FMI: Used to identify the applicable J1939-73 FMI detected in the Engine Turbocharger Compressor Bypass Actuator 1 by the manufacturers software.  When there is multiple failures, the most ...";
CM_ SG_ 2432541694 ETCpssBpssAtt1TptStts "Engine Turbocharger Compressor Bypass Actuator 1 Temperature Status: Used to identify the status of the Engine Turbocharger Compresssor Bypass Actuator 1 drive circuitry temperature.  Temperature excursions may affect the torque output.000b = High Mo...";
CM_ BO_ 2432593918 "Adaptive Cruise Control 1";
CM_ SG_ 2432593918 ACCDistanceAlertSignal "ACC Distance Alert Signal: Signal to indicate to the operator that the ACC system is not able to maintain the distance to the target. Example: Target stopping rapidly. This signal may be used to activate warning sounds or indicators.00b = ACC DAS Not...";
CM_ SG_ 2432593918 ACCSystemShutoffWarning "ACC System Shutoff Warning: Signal to warn the driver of system deactivation due to non-driver actions. Example: Attempting to control vehicle speed below or above limits of ACC. This signal may be used to activate warning sounds or indicators.00b = ...";
CM_ SG_ 2432593918 ACCTargetDetected "ACC Target Detected: Signal to indicate to the driver that the ACC system has detected a target. 00b = No targets detected01b = Target detected10b = Reserved11b = Take no action";
CM_ SG_ 2432593918 AdaptiveCruiseControlMode "Adaptive Cruise Control Mode: This parameter is used to indicate the current state, or mode, of operation by the Adaptive Cruise Control (ACC) device. The states characterize independent system states (e.g., it is not possible to express distance con...";
CM_ SG_ 2432593918 AdaptiveCruiseControlSetSpeed "Adaptive Cruise Control Set Speed: Value of the desired (chosen) velocity of the adaptive cruise control system.";
CM_ SG_ 2432593918 Adptvrsntrlstdstnmd "Adaptive cruise control set distance mode: Selected distance mode for adaptive cruise control. 000b = ACC Distance mode #1 (largest distance)001b = ACC Distance mode #2010b = ACC Distance mode #3011b = ACC Distance mode #4100b = ACC Distance mode #5 ...";
CM_ SG_ 2432593918 Distancetoforwardvehicle "Distance to forward vehicle: Distance to the preceding vehicle situated within 250 m in the same lane and moving in the same direction.The value of FFh indicates that no vehicle is detected.";
CM_ SG_ 2432593918 ForwardCollisionWarning "Forward Collision Warning: This parameter indicates if a collision is imminent and strong driver reaction either by braking hard or by an avoidance maneuver are imperative to prevent a collision.  00b = No warning01b = Collision is imminent10b = Erro...";
CM_ SG_ 2432593918 Roadcurvature "Road curvature: Estimated value of the current road curvature for use by the adaptive cruise control system.  Positive values are used for left curves.  Curvature is the inverse of the radius and is zero for straight roads.";
CM_ SG_ 2432593918 Speedofforwardvehicle "Speed of forward vehicle: Absolute velocity of the preceding vehicle situated within 250 m in the same lane and moving in the same direction.The value of FFh indicates that no vehicle is detected.";
CM_ BO_ 2432595710 "Laser Leveling System Vertical Position Display Data";
CM_ SG_ 2432595710 DisplayDeadbands "Display Deadbands: Sets Display Deadbands mode.0000b = Narrow = +/- 4.5mm0001b = Standard = +/- 12mm0010b = Wide = +/- 24mm0011b to 1110b = Reserved1111b = Not Available";
CM_ SG_ 2432595710 LEDDisplayData1 "LED Display Data #1: Informs display devices how to display the current vertical position.Values which are less than 128 decimal are bit-mapped values and any combination of these values is considered a valid value.  For example communicating the Hig...";
CM_ SG_ 2432595710 LEDDisplayDeadbandControl "LED Display Deadband Control: This parameter informs the system what the selected Display deadband will be.0000b = +/- 4.5 mm  (0.015 feet, 0.18 inches)0001b = +/- 12 mm   (0.040 feet, 0.45 inches)0010b = +/- 24 mm   (0.080 feet, 0.96 inches)0011b = ...";
CM_ SG_ 2432595710 LEDDisplayModeControl "LED Display Mode Control: This parameter informs the system what the selected Display mode will be.0000b = Center On-Grade Display Mode 1 ( 5 CHANNEL )0001b = Offset On-Grade Display Mode 0010b = Center On-Grade Display Mode 2 ( 7 CHANNEL )0011b to 1...";
CM_ SG_ 2432595710 LEDPatternControl "LED Pattern Control: Sets LED Pattern control mode on laser leveling systems.0000b = 5 Channel0001b = Offset0010b = 7 Channel0011b to 1110b = Reserved1111b = Not Available";
CM_ BO_ 2498776830 "Engine Cylinder 1 Combustion Average Information";
CM_ SG_ 2498776830 EngnClndr1AvrgCmstnDrtn "Engine Cylinder 1 Average Combustion Duration: Average duration of combustion calculated over defined number of combustion cycles for engine cylinder 1 with reference to the crank angle.  Combustion duration is the difference between end of combustio...";
CM_ SG_ 2498776830 EngnClndr1AvrgCntrfCmstnTmng "Engine Cylinder 1 Average Center of Combustion Timing: Average timing calculated over defined number of combustion cycles for the center of combustion in engine cylinder 1 with reference to the crank angle.  Center of Combustion is used to indicate t...";
CM_ SG_ 2498776830 EngnClndr1AvrgStrtfCmstnTmng "Engine Cylinder 1 Average Start of Combustion Timing: Average start of combustion timing calculated over defined number of combustion cycles for engine cylinder 1 with reference to the crank angle.  When the combustion happens after the TDC (Top Dead...";
CM_ SG_ 2498776830 EngnClndr1IndtdMnEfftvPrssr "Engine Cylinder 1 Indicated Mean Effective Pressure: Average cylinder pressure calculated over defined number of combustion cycles for engine cylinder 1.   Negative range is to cover thermodynamic behavior during misfire.";
CM_ BO_ 2498777086 "Engine Cylinder 2 Combustion Average Information";
CM_ SG_ 2498777086 EngnClndr2AvrgCmstnDrtn "Engine Cylinder 2 Average Combustion Duration: Average duration of combustion calculated over defined number of combustion cycles for engine cylinder 2 with reference to the crank angle.  Combustion duration is the difference between end of combustio...";
CM_ SG_ 2498777086 EngnClndr2AvrgCntrfCmstnTmng "Engine Cylinder 2 Average Center of Combustion Timing: Average timing calculated over defined number of combustion cycles for the center of combustion in engine cylinder 2 with reference to the crank angle.  Center of Combustion is used to indicate t...";
CM_ SG_ 2498777086 EngnClndr2AvrgStrtfCmstnTmng "Engine Cylinder 2 Average Start of Combustion Timing: Average start of combustion timing calculated over defined number of combustion cycles for engine cylinder 2 with reference to the crank angle.  When the combustion happens after the TDC (Top Dead...";
CM_ SG_ 2498777086 EngnClndr2IndtdMnEfftvPrssr "Engine Cylinder 2 Indicated Mean Effective Pressure: Average cylinder pressure calculated over defined number of combustion cycles for engine cylinder 2.  Negative range is to cover thermodynamic behavior during misfire.";
CM_ BO_ 2498777342 "Engine Cylinder 3 Combustion Average Information";
CM_ SG_ 2498777342 EngnClndr3AvrgCmstnDrtn "Engine Cylinder 3 Average Combustion Duration: Average duration of combustion calculated over defined number of combustion cycles for engine cylinder 3 with reference to the crank angle.  Combustion duration is the difference between end of combustio...";
CM_ SG_ 2498777342 EngnClndr3AvrgCntrfCmstnTmng "Engine Cylinder 3 Average Center of Combustion Timing: Average timing calculated over defined number of combustion cycles for the center of combustion in engine cylinder 3 with reference to the crank angle.  Center of Combustion is used to indicate t...";
CM_ SG_ 2498777342 EngnClndr3AvrgStrtfCmstnTmng "Engine Cylinder 3 Average Start of Combustion Timing: Average start of combustion timing calculated over defined number of combustion cycles for engine cylinder 3 with reference to the crank angle.  When the combustion happens after the TDC (Top Dead...";
CM_ SG_ 2498777342 EngnClndr3IndtdMnEfftvPrssr "Engine Cylinder 3 Indicated Mean Effective Pressure: Average cylinder pressure calculated over defined number of combustion cycles for engine cylinder 3.  Negative range is to cover thermodynamic behavior during misfire.";
CM_ BO_ 2498777598 "Engine Cylinder 4 Combustion Average Information";
CM_ SG_ 2498777598 EngnClndr4AvrgCmstnDrtn "Engine Cylinder 4 Average Combustion Duration: Average duration of combustion calculated over defined number of combustion cycles for engine cylinder 4 with reference to the crank angle.  Combustion duration is the difference between end of combustio...";
CM_ SG_ 2498777598 EngnClndr4AvrgCntrfCmstnTmng "Engine Cylinder 4 Average Center of Combustion Timing: Average timing calculated over defined number of combustion cycles for the center of combustion in engine cylinder 4 with reference to the crank angle.  Center of Combustion is used to indicate t...";
CM_ SG_ 2498777598 EngnClndr4AvrgStrtfCmstnTmng "Engine Cylinder 4 Average Start of Combustion Timing: Average start of combustion timing calculated over defined number of combustion cycles for engine cylinder 4 with reference to the crank angle.  When the combustion happens after the TDC (Top Dead...";
CM_ SG_ 2498777598 EngnClndr4IndtdMnEfftvPrssr "Engine Cylinder 4 Indicated Mean Effective Pressure: Average cylinder pressure calculated over defined number of combustion cycles for engine cylinder 4.  Negative range is to cover thermodynamic behavior during misfire.";
CM_ BO_ 2498777854 "Engine Cylinder 5 Combustion Average Information";
CM_ SG_ 2498777854 EngnClndr5AvrgCmstnDrtn "Engine Cylinder 5 Average Combustion Duration: Average duration of combustion calculated over defined number of combustion cycles for engine cylinder 5 with reference to the crank angle.  Combustion duration is the difference between end of combustio...";
CM_ SG_ 2498777854 EngnClndr5AvrgCntrfCmstnTmng "Engine Cylinder 5 Average Center of Combustion Timing: Average timing calculated over defined number of combustion cycles for the center of combustion in engine cylinder 5 with reference to the crank angle.  Center of Combustion is used to indicate t...";
CM_ SG_ 2498777854 EngnClndr5AvrgStrtfCmstnTmng "Engine Cylinder 5 Average Start of Combustion Timing: Average start of combustion timing calculated over defined number of combustion cycles for engine cylinder 5 with reference to the crank angle.  When the combustion happens after the TDC (Top Dead...";
CM_ SG_ 2498777854 EngnClndr5IndtdMnEfftvPrssr "Engine Cylinder 5 Indicated Mean Effective Pressure: Average cylinder pressure calculated over defined number of combustion cycles for engine cylinder 5.  Negative range is to cover thermodynamic behavior during misfire.";
CM_ BO_ 2498778110 "Engine Cylinder 6 Combustion Average Information";
CM_ SG_ 2498778110 EngnClndr6AvrgCmstnDrtn "Engine Cylinder 6 Average Combustion Duration: Average duration of combustion calculated over defined number of combustion cycles for engine cylinder 6 with reference to the crank angle.  Combustion duration is the difference between end of combustio...";
CM_ SG_ 2498778110 EngnClndr6AvrgCntrfCmstnTmng "Engine Cylinder 6 Average Center of Combustion Timing: Average timing calculated over defined number of combustion cycles for the center of combustion in engine cylinder 6 with reference to the crank angle.  Center of Combustion is used to indicate t...";
CM_ SG_ 2498778110 EngnClndr6AvrgStrtfCmstnTmng "Engine Cylinder 6 Average Start of Combustion Timing: Average start of combustion timing calculated over defined number of combustion cycles for engine cylinder 6 with reference to the crank angle.  When the combustion happens after the TDC (Top Dead...";
CM_ SG_ 2498778110 EngnClndr6IndtdMnEfftvPrssr "Engine Cylinder 6 Indicated Mean Effective Pressure: Average cylinder pressure calculated over defined number of combustion cycles for engine cylinder 6.  Negative range is to cover thermodynamic behavior during misfire.";
CM_ BO_ 2498778366 "Engine Cylinder 7 Combustion Average Information";
CM_ SG_ 2498778366 EngnClndr7AvrgCmstnDrtn "Engine Cylinder 7 Average Combustion Duration: Average duration of combustion calculated over defined number of combustion cycles for engine cylinder 7 with reference to the crank angle.  Combustion duration is the difference between end of combustio...";
CM_ SG_ 2498778366 EngnClndr7AvrgCntrfCmstnTmng "Engine Cylinder 7 Average Center of Combustion Timing: Average timing calculated over defined number of combustion cycles for the center of combustion in engine cylinder 7 with reference to the crank angle.  Center of Combustion is used to indicate t...";
CM_ SG_ 2498778366 EngnClndr7AvrgStrtfCmstnTmng "Engine Cylinder 7 Average Start of Combustion Timing: Average start of combustion timing calculated over defined number of combustion cycles for engine cylinder 7 with reference to the crank angle.  When the combustion happens after the TDC (Top Dead...";
CM_ SG_ 2498778366 EngnClndr7IndtdMnEfftvPrssr "Engine Cylinder 7 Indicated Mean Effective Pressure: Average cylinder pressure calculated over defined number of combustion cycles for engine cylinder 7.  Negative range is to cover thermodynamic behavior during misfire.";
CM_ BO_ 2498778622 "Engine Cylinder 8 Combustion Average Information";
CM_ SG_ 2498778622 EngnClndr8AvrgCmstnDrtn "Engine Cylinder 8 Average Combustion Duration: Average duration of combustion calculated over defined number of combustion cycles for engine cylinder 8 with reference to the crank angle.  Combustion duration is the difference between end of combustio...";
CM_ SG_ 2498778622 EngnClndr8AvrgCntrfCmstnTmng "Engine Cylinder 8 Average Center of Combustion Timing: Average timing calculated over defined number of combustion cycles for the center of combustion in engine cylinder 8 with reference to the crank angle.  Center of Combustion is used to indicate t...";
CM_ SG_ 2498778622 EngnClndr8AvrgStrtfCmstnTmng "Engine Cylinder 8 Average Start of Combustion Timing: Average start of combustion timing calculated over defined number of combustion cycles for engine cylinder 8 with reference to the crank angle.  When the combustion happens after the TDC (Top Dead...";
CM_ SG_ 2498778622 EngnClndr8IndtdMnEfftvPrssr "Engine Cylinder 8 Indicated Mean Effective Pressure: Average cylinder pressure calculated over defined number of combustion cycles for engine cylinder 8.  Negative range is to cover thermodynamic behavior during misfire.";
CM_ BO_ 2498778878 "Engine Cylinder 9 Combustion Average Information";
CM_ SG_ 2498778878 EngnClndr9AvrgCmstnDrtn "Engine Cylinder 9 Average Combustion Duration: Average duration of combustion calculated over defined number of combustion cycles for engine cylinder 9 with reference to the crank angle.  Combustion duration is the difference between end of combustio...";
CM_ SG_ 2498778878 EngnClndr9AvrgCntrfCmstnTmng "Engine Cylinder 9 Average Center of Combustion Timing: Average timing calculated over defined number of combustion cycles for the center of combustion in engine cylinder 9 with reference to the crank angle.  Center of Combustion is used to indicate t...";
CM_ SG_ 2498778878 EngnClndr9AvrgStrtfCmstnTmng "Engine Cylinder 9 Average Start of Combustion Timing: Average start of combustion timing calculated over defined number of combustion cycles for engine cylinder 9 with reference to the crank angle.  When the combustion happens after the TDC (Top Dead...";
CM_ SG_ 2498778878 EngnClndr9IndtdMnEfftvPrssr "Engine Cylinder 9 Indicated Mean Effective Pressure: Average cylinder pressure calculated over defined number of combustion cycles for engine cylinder 9.  Negative range is to cover thermodynamic behavior during misfire.";
CM_ BO_ 2498779134 "Engine Cylinder 10 Combustion Average Information";
CM_ SG_ 2498779134 EngnClndr10AvrgCmstnDrtn "Engine Cylinder 10 Average Combustion Duration: Average duration of combustion calculated over defined number of combustion cycles for engine cylinder 10 with reference to the crank angle.  Combustion duration is the difference between end of combust...";
CM_ SG_ 2498779134 EngnClndr10AvrgCntrfCmstnTmng "Engine Cylinder 10 Average Center of Combustion Timing: Average timing calculated over defined number of combustion cycles for the center of combustion in engine cylinder 10 with reference to the crank angle.  Center of Combustion is used to indicate...";
CM_ SG_ 2498779134 EngnClndr10AvrgStrtfCmstnTmng "Engine Cylinder 10 Average Start of Combustion Timing: Average start of combustion timing calculated over defined number of combustion cycles for engine cylinder 10 with reference to the crank angle.  When the combustion happens after the TDC (Top De...";
CM_ SG_ 2498779134 EngnClndr10IndtdMnEfftvPrssr "Engine Cylinder 10 Indicated Mean Effective Pressure: Average cylinder pressure calculated over defined number of combustion cycles for engine cylinder 10.  Negative range is to cover thermodynamic behavior during misfire.";
CM_ BO_ 2498779390 "Engine Cylinder 11 Combustion Average Information";
CM_ SG_ 2498779390 EngnClndr11AvrgCmstnDrtn "Engine Cylinder 11 Average Combustion Duration: Average duration of combustion calculated over defined number of combustion cycles for engine cylinder 11 with reference to the crank angle.  Combustion duration is the difference between end of combust...";
CM_ SG_ 2498779390 EngnClndr11AvrgCntrfCmstnTmng "Engine Cylinder 11 Average Center of Combustion Timing: Average timing calculated over defined number of combustion cycles for the center of combustion in engine cylinder 11 with reference to the crank angle.  Center of Combustion is used to indicate...";
CM_ SG_ 2498779390 EngnClndr11AvrgStrtfCmstnTmng "Engine Cylinder 11 Average Start of Combustion Timing: Average start of combustion timing calculated over defined number of combustion cycles for engine cylinder 11 with reference to the crank angle.  When the combustion happens after the TDC (Top De...";
CM_ SG_ 2498779390 EngnClndr11IndtdMnEfftvPrssr "Engine Cylinder 11 Indicated Mean Effective Pressure: Average cylinder pressure calculated over defined number of combustion cycles for engine cylinder 11.  Negative range is to cover thermodynamic behavior during misfire.";
CM_ BO_ 2498779646 "Engine Cylinder 12 Combustion Average Information";
CM_ SG_ 2498779646 EngnClndr12AvrgCmstnDrtn "Engine Cylinder 12 Average Combustion Duration: Average duration of combustion calculated over defined number of combustion cycles for engine cylinder 12 with reference to the crank angle.  Combustion duration is the difference between end of combust...";
CM_ SG_ 2498779646 EngnClndr12AvrgCntrfCmstnTmng "Engine Cylinder 12 Average Center of Combustion Timing: Average timing calculated over defined number of combustion cycles for the center of combustion in engine cylinder 12 with reference to the crank angle.  Center of Combustion is used to indicate...";
CM_ SG_ 2498779646 EngnClndr12AvrgStrtfCmstnTmng "Engine Cylinder 12 Average Start of Combustion Timing: Average start of combustion timing calculated over defined number of combustion cycles for engine cylinder 12 with reference to the crank angle.  When the combustion happens after the TDC (Top De...";
CM_ SG_ 2498779646 EngnClndr12IndtdMnEfftvPrssr "Engine Cylinder 12 Indicated Mean Effective Pressure: Average cylinder pressure calculated over defined number of combustion cycles for engine cylinder 12.  Negative range is to cover thermodynamic behavior during misfire.";
CM_ BO_ 2498779902 "Engine Cylinder 13 Combustion Average Information";
CM_ SG_ 2498779902 EngnClndr13AvrgCmstnDrtn "Engine Cylinder 13 Average Combustion Duration: Average duration of combustion calculated over defined number of combustion cycles for engine cylinder 13 with reference to the crank angle.  Combustion duration is the difference between end of combust...";
CM_ SG_ 2498779902 EngnClndr13AvrgCntrfCmstnTmng "Engine Cylinder 13 Average Center of Combustion Timing: Average timing calculated over defined number of combustion cycles for the center of combustion in engine cylinder 13 with reference to the crank angle.  Center of Combustion is used to indicate...";
CM_ SG_ 2498779902 EngnClndr13AvrgStrtfCmstnTmng "Engine Cylinder 13 Average Start of Combustion Timing: Average start of combustion timing calculated over defined number of combustion cycles for engine cylinder 13 with reference to the crank angle.  When the combustion happens after the TDC (Top De...";
CM_ SG_ 2498779902 EngnClndr13IndtdMnEfftvPrssr "Engine Cylinder 13 Indicated Mean Effective Pressure: Average cylinder pressure calculated over defined number of combustion cycles for engine cylinder 13.  Negative range is to cover thermodynamic behavior during misfire.";
CM_ BO_ 2498780158 "Engine Cylinder 14 Combustion Average Information";
CM_ SG_ 2498780158 EngnClndr14AvrgCmstnDrtn "Engine Cylinder 14 Average Combustion Duration: Average duration of combustion calculated over defined number of combustion cycles for engine cylinder 14 with reference to the crank angle.  Combustion duration is the difference between end of combust...";
CM_ SG_ 2498780158 EngnClndr14AvrgCntrfCmstnTmng "Engine Cylinder 14 Average Center of Combustion Timing: Average timing calculated over defined number of combustion cycles for the center of combustion in engine cylinder 14 with reference to the crank angle.  Center of Combustion is used to indicate...";
CM_ SG_ 2498780158 EngnClndr14AvrgStrtfCmstnTmng "Engine Cylinder 14 Average Start of Combustion Timing: Average start of combustion timing calculated over defined number of combustion cycles for engine cylinder 14 with reference to the crank angle.  When the combustion happens after the TDC (Top De...";
CM_ SG_ 2498780158 EngnClndr14IndtdMnEfftvPrssr "Engine Cylinder 14 Indicated Mean Effective Pressure: Average cylinder pressure calculated over defined number of combustion cycles for engine cylinder 14.  Negative range is to cover thermodynamic behavior during misfire.";
CM_ BO_ 2498780414 "Engine Cylinder 15 Combustion Average Information";
CM_ SG_ 2498780414 EngnClndr15AvrgCmstnDrtn "Engine Cylinder 15 Average Combustion Duration: Average duration of combustion calculated over defined number of combustion cycles for engine cylinder 15 with reference to the crank angle.  Combustion duration is the difference between end of combust...";
CM_ SG_ 2498780414 EngnClndr15AvrgCntrfCmstnTmng "Engine Cylinder 15 Average Center of Combustion Timing: Average timing calculated over defined number of combustion cycles for the center of combustion in engine cylinder 15 with reference to the crank angle.  Center of Combustion is used to indicate...";
CM_ SG_ 2498780414 EngnClndr15AvrgStrtfCmstnTmng "Engine Cylinder 15 Average Start of Combustion Timing: Average start of combustion timing calculated over defined number of combustion cycles for engine cylinder 15 with reference to the crank angle.  When the combustion happens after the TDC (Top De...";
CM_ SG_ 2498780414 EngnClndr15IndtdMnEfftvPrssr "Engine Cylinder 15 Indicated Mean Effective Pressure: Average cylinder pressure calculated over defined number of combustion cycles for engine cylinder 15.  Negative range is to cover thermodynamic behavior during misfire.";
CM_ BO_ 2498780670 "Engine Cylinder 16 Combustion Average Information";
CM_ SG_ 2498780670 EngnClndr16AvrgCmstnDrtn "Engine Cylinder 16 Average Combustion Duration: Average duration of combustion calculated over defined number of combustion cycles for engine cylinder 16 with reference to the crank angle.  Combustion duration is the difference between end of combust...";
CM_ SG_ 2498780670 EngnClndr16AvrgCntrfCmstnTmng "Engine Cylinder 16 Average Center of Combustion Timing: Average timing calculated over defined number of combustion cycles for the center of combustion in engine cylinder 16 with reference to the crank angle.  Center of Combustion is used to indicate...";
CM_ SG_ 2498780670 EngnClndr16AvrgStrtfCmstnTmng "Engine Cylinder 16 Average Start of Combustion Timing: Average start of combustion timing calculated over defined number of combustion cycles for engine cylinder 16 with reference to the crank angle.  When the combustion happens after the TDC (Top De...";
CM_ SG_ 2498780670 EngnClndr16IndtdMnEfftvPrssr "Engine Cylinder 16 Indicated Mean Effective Pressure: Average cylinder pressure calculated over defined number of combustion cycles for engine cylinder 16.  Negative range is to cover thermodynamic behavior during misfire.";
CM_ BO_ 2498780926 "Engine Cylinder 17 Combustion Average Information";
CM_ SG_ 2498780926 EngnClndr17AvrgCmstnDrtn "Engine Cylinder 17 Average Combustion Duration: Average duration of combustion calculated over defined number of combustion cycles for engine cylinder 17 with reference to the crank angle.  Combustion duration is the difference between end of combust...";
CM_ SG_ 2498780926 EngnClndr17AvrgCntrfCmstnTmng "Engine Cylinder 17 Average Center of Combustion Timing: Average timing calculated over defined number of combustion cycles for the center of combustion in engine cylinder 17 with reference to the crank angle.  Center of Combustion is used to indicate...";
CM_ SG_ 2498780926 EngnClndr17AvrgStrtfCmstnTmng "Engine Cylinder 17 Average Start of Combustion Timing: Average start of combustion timing calculated over defined number of combustion cycles for engine cylinder 17 with reference to the crank angle.  When the combustion happens after the TDC (Top De...";
CM_ SG_ 2498780926 EngnClndr17IndtdMnEfftvPrssr "Engine Cylinder 17 Indicated Mean Effective Pressure: Average cylinder pressure calculated over defined number of combustion cycles for engine cylinder 17.  Negative range is to cover thermodynamic behavior during misfire.";
CM_ BO_ 2498781182 "Engine Cylinder 18 Combustion Average Information";
CM_ SG_ 2498781182 EngnClndr18AvrgCmstnDrtn "Engine Cylinder 18 Average Combustion Duration: Average duration of combustion calculated over defined number of combustion cycles for engine cylinder 18 with reference to the crank angle.  Combustion duration is the difference between end of combust...";
CM_ SG_ 2498781182 EngnClndr18AvrgCntrfCmstnTmng "Engine Cylinder 18 Average Center of Combustion Timing: Average timing calculated over defined number of combustion cycles for the center of combustion in engine cylinder 18 with reference to the crank angle.  Center of Combustion is used to indicate...";
CM_ SG_ 2498781182 EngnClndr18AvrgStrtfCmstnTmng "Engine Cylinder 18 Average Start of Combustion Timing: Average start of combustion timing calculated over defined number of combustion cycles for engine cylinder 18 with reference to the crank angle.  When the combustion happens after the TDC (Top De...";
CM_ SG_ 2498781182 EngnClndr18IndtdMnEfftvPrssr "Engine Cylinder 18 Indicated Mean Effective Pressure: Average cylinder pressure calculated over defined number of combustion cycles for engine cylinder 18.  Negative range is to cover thermodynamic behavior during misfire.";
CM_ BO_ 2498781438 "Engine Cylinder 19 Combustion Average Information";
CM_ SG_ 2498781438 EngnClndr19AvrgCmstnDrtn "Engine Cylinder 19 Average Combustion Duration: Average duration of combustion calculated over defined number of combustion cycles for engine cylinder 19 with reference to the crank angle.  Combustion duration is the difference between end of combust...";
CM_ SG_ 2498781438 EngnClndr19AvrgCntrfCmstnTmng "Engine Cylinder 19 Average Center of Combustion Timing: Average timing calculated over defined number of combustion cycles for the center of combustion in engine cylinder 19 with reference to the crank angle.  Center of Combustion is used to indicate...";
CM_ SG_ 2498781438 EngnClndr19AvrgStrtfCmstnTmng "Engine Cylinder 19 Average Start of Combustion Timing: Average start of combustion timing calculated over defined number of combustion cycles for engine cylinder 19 with reference to the crank angle.  When the combustion happens after the TDC (Top De...";
CM_ SG_ 2498781438 EngnClndr19IndtdMnEfftvPrssr "Engine Cylinder 19 Indicated Mean Effective Pressure: Average cylinder pressure calculated over defined number of combustion cycles for engine cylinder 19.  Negative range is to cover thermodynamic behavior during misfire.";
CM_ BO_ 2498781694 "Engine Cylinder 20 Combustion Average Information";
CM_ SG_ 2498781694 EngnClndr20AvrgCmstnDrtn "Engine Cylinder 20 Average Combustion Duration: Average duration of combustion calculated over defined number of combustion cycles for engine cylinder 20 with reference to the crank angle.  Combustion duration is the difference between end of combust...";
CM_ SG_ 2498781694 EngnClndr20AvrgCntrfCmstnTmng "Engine Cylinder 20 Average Center of Combustion Timing: Average timing calculated over defined number of combustion cycles for the center of combustion in engine cylinder 20 with reference to the crank angle.  Center of Combustion is used to indicate...";
CM_ SG_ 2498781694 EngnClndr20AvrgStrtfCmstnTmng "Engine Cylinder 20 Average Start of Combustion Timing: Average start of combustion timing calculated over defined number of combustion cycles for engine cylinder 20 with reference to the crank angle.  When the combustion happens after the TDC (Top De...";
CM_ SG_ 2498781694 EngnClndr20IndtdMnEfftvPrssr "Engine Cylinder 20 Indicated Mean Effective Pressure: Average cylinder pressure calculated over defined number of combustion cycles for engine cylinder 20.  Negative range is to cover thermodynamic behavior during misfire.";
CM_ BO_ 2498825982 "Dump Truck Body Information";
CM_ SG_ 2498825982 DmpBdRsPstnRltvtRmmnddMxmm "Dump Body Raise Position Relative to Recommended Maximum: The angular position of the dump body expressed as a percentage of the maximum recommended body raised position. 100% represents the maximum default raised position of the dump body and is mea...";
CM_ SG_ 2498825982 DumpBodyEjectorBladePosition "Dump Body Ejector Blade Position: The dump body ejector blade is used to push material out of the dump body of a dump truck. 0% represents the fully retracted position and 100% represents the fully extended position.";
CM_ SG_ 2498825982 DumpBodyRaiseAngle "Dump Body Raise Angle: The angular position of the dump body referenced to the vehicle chassis. 0 degrees represents the body in its resting position.";
CM_ SG_ 2498825982 DumpBodyRollAngle "Dump Body Roll Angle: The angle between the dump body y-axis and the ground plane (i.e. rotation about the X-axis). The roll angle for a roll to the right is reported with a positive value. Roll angle is the same for both Z-Down and Z-Up axis systems...";
CM_ BO_ 2499547902 "Cab Door Control 1";
CM_ SG_ 2499547902 CabDoorsLockActuationCommand "Cab Doors Lock Actuation Command: Commands cab door latch state change: lock or unlock.000b = Unlock left front cab door latch (driver door on LH steer vehicles)001b = Unlock right front cab door latch (front passenger door for LH steer vehicles)010b...";
CM_ SG_ 2499547902 LeftFrontWindowPositionCommand "Left Front Window Position Command: Commands position change of left front window (driver door window on left-hand steer vehicles).000b = Window move up001b = Window move down010b = Window auto up011b = Window auto down100b = Reserved101b = Reserved1...";
CM_ SG_ 2499547902 LeftRearWindowPositionCommand "Left Rear Window Position Command: Commands position change of left rear window.000b = Window move up001b = Window move down010b = Window auto up011b = Window auto down100b = Reserved101b = Reserved110b = Reserved111b = Take no action...";
CM_ SG_ 2499547902 MirrorLeft1HeatCommand "Mirror Left 1 Heat Command: Command to activate heater for primary mirror on the left side (driver side for left-hand steer vehicle).  Mirror heat may be expected to latch in the on state upon receipt of the command, stay on while the command is take...";
CM_ SG_ 2499547902 MirrorLeft1HorizontalCommand "Mirror Left 1 Horizontal Command: Commands horizontal position change of the primary mirror on the left side (driver side for left-hand steer vehicles).00b = Move left01b = Move right10b = Reset (Move to predefined position)11b = Take no action...";
CM_ SG_ 2499547902 MirrorLeft1VerticalCommand "Mirror Left 1 Vertical Command: Commands vertical position change of the primary mirror on the left side (driver side for left-hand steer vehicles).00b = Move up01b = Move down10b = Reset (Move to predefined position)11b = Take no action";
CM_ SG_ 2499547902 MirrorLeft2HeatCommand "Mirror Left 2 Heat Command: Command to activate heater for second mirror on the left side (driver side for left-hand steer vehicle).  Mirror heat may be expected to latch in the on state upon receipt of the command, stay on while the command is take ...";
CM_ SG_ 2499547902 MirrorLeft2HorizontalCommand "Mirror Left 2 Horizontal Command: Commands horizontal position change of the second mirror on the left side (driver side for left-hand steer vehicles).00b = Move left01b = Move right10b = Reset (Move to predefined position)11b = Take no action...";
CM_ SG_ 2499547902 MirrorLeft2VerticalCommand "Mirror Left 2 Vertical Command: Commands vertical position change of the second mirror on the left side (driver side for left-hand steer vehicles). 00b = Move up01b = Move down10b = Reset (Move to predefined position)11b = Take no action";
CM_ SG_ 2499547902 MirrorRight1HeatCommand "Mirror Right 1 Heat Command: Command to activate heater for primary mirror on the right side (passenger side for left-hand steer vehicle).  Mirror heat may be expected to latch in the on state upon receipt of the command, stay on while the command is...";
CM_ SG_ 2499547902 MirrorRight1HorizontalCommand "Mirror Right 1 Horizontal Command: Commands horizontal position change of the primary mirror on the right side (passenger side for lefthand steer vehicles).00b = Move left01b = Move right10b = Reset (Move to predefined position)11b = Take no action...";
CM_ SG_ 2499547902 MirrorRight1VerticalCommand "Mirror Right 1 Vertical Command: Commands vertical position change of the primary mirror on the right side (passenger side for lefthand steer vehicles).00b = Move up01b = Move down10b = Reset (Move to predefined position)11b = Take no action...";
CM_ SG_ 2499547902 MirrorRight2HeatCommand "Mirror Right 2 Heat Command: Command to activate heater for second mirror on the right side (passenger side for left-hand steer vehicle).  Mirror heat may be expected to latch in the on state upon receipt of the command, stay on while the command is ...";
CM_ SG_ 2499547902 MirrorRight2HorizontalCommand "Mirror Right 2 Horizontal Command: Commands horizontal position change of the second mirror on the right side (passenger side for lefthand steer vehicles).00b = Move left01b = Move right10b = Reset (Move to predefined position)11b = Take no action...";
CM_ SG_ 2499547902 MirrorRight2VerticalCommand "Mirror Right 2 Vertical Command: Commands vertical position change of the second mirror on the right side (passenger side for lefthand steer vehicles).00b = Move up01b = Move down10b = Reset (Move to predefined position)11b = Take no action";
CM_ SG_ 2499547902 RemoteCabDoorLockRequest "Remote Cab Door Lock Request: Request to the cab door lock controller from Remote Keyless Entry or or other external device to lock or unlock doors.This parameter is different from Cab Doors Lock Actuation Command (SPN 7727) because this is a request...";
CM_ SG_ 2499547902 RightFrontWindowPositionCommand "Right Front Window Position Command: Commands position change of right front window (passenger door window on left-hand steer vehicles).000b = Window move up001b = Window move down010b = Window auto up011b = Window auto down100b = Reserved101b = Rese...";
CM_ SG_ 2499547902 RightRearWindowPositionCommand "Right Rear Window Position Command: Commands position change of the right rear window.000b = Window move up001b = Window move down010b = Window auto up011b = Window auto down100b = Reserved101b = Reserved110b = Reserved111b = Take no action...";
CM_ SG_ 2499547902 MirrorFoldingSwitch "Mirror Folding Switch: Status of momentary switch used to toggle position of folding mirrors.00b = No Request01b = Request to toggle mirror position (fold/unfold)10b = Reserved11b = Take no action";
CM_ SG_ 2499547902 MirrorAutoPanningEnable "Mirror Auto Panning Enable: Command to enable/disable the auto panning (trailer tracking) function of the mirror or mirror replacement camera.00b = Disable panning01b = Enable panning10b = Reserved11b = Not available/Take no action";
CM_ BO_ 2499548158 "Door Latch Status";
CM_ SG_ 2499548158 LeftFrontCabDoorLatchPosition "Left Front Cab Door Latch Position: Status of the left front cab door latch (driver door for left-hand steer vehicles). Door latches may have 3 positions indicating fully open, 1st detent or ajar, and 2nd detent or fully closed.000b = Door Latch Open...";
CM_ SG_ 2499548158 LeftRearCabDoorLatchPosition "Left Rear Cab Door Latch Position: Status of the left rear cab door latch. Door latches may have 3 positions indicating fully open, 1st detent or ajar, and 2nd detent or fully closed.000b = Door Latch Open001b = Door Latch Fully Closed/Latched010b = ...";
CM_ SG_ 2499548158 RightFrontCabDoorLatchPosition "Right Front Cab Door Latch Position: Status of the right front cab door latch (passenger door for left-hand steer vehicles). Door latches may have 3 positions indicating fully open, 1st detent or ajar, and 2nd detent or fully closed.000b = Door Latch...";
CM_ SG_ 2499548158 RightRearCabDoorLatchPosition "Right Rear Cab Door Latch Position: Status of the right rear cab door latch. Door latches may have 3 positions indicating fully open, 1st detent or ajar, and 2nd detent or fully closed.000b = Door Latch Open001b = Door Latch Fully Closed/Latched010b ...";
CM_ BO_ 2499548670 "Vehicle Electrical Power 6";
CM_ SG_ 2499548670 BatteryPotentialPowerInput3 "Battery Potential / Power Input 3: This parameter measures the third source of battery potential as measured at the input of the ECU/actuator etc. coming from one or more batteries, irrespective of the distance between the component and the battery. ...";
CM_ SG_ 2499548670 BatteryPotentialPowerInput4 "Battery Potential / Power Input 4: This parameter measures the fourth source of battery potential as measured at the input of the ECU/actuator etc. coming from one or more batteries, irrespective of the distance between the component and the battery....";
CM_ SG_ 2499548670 SLIBattery3NetCurrent "SLI Battery 3 Net Current: Net flow of electrical current into/out of the third battery or third set of batteries used for starting the engine, for lighting, and for ignition (SLI).";
CM_ SG_ 2499548670 SLIBattery4NetCurrent "SLI Battery 4 Net Current: Net flow of electrical current into/out of the fourth battery or fourth set of batteries used for starting the engine, for lighting, and for ignition (SLI).";
CM_ BO_ 2499548926 "Payload Temperature 2";
CM_ SG_ 2499548926 PayloadTemperature5 "Payload Temperature 5: Temperature of payload at measurement point 5.Measurement position is manufacturer or regulation specific.";
CM_ BO_ 2499549182 "Payload Temperature 1";
CM_ SG_ 2499549182 PayloadTemperature1 "Payload Temperature 1: Temperature of payload at measurement point 1.Measurement position is manufacturer or regulation specific.";
CM_ SG_ 2499549182 PayloadTemperature2 "Payload Temperature 2: Temperature of payload at measurement point 2.Measurement position is manufacturer or regulation specific.";
CM_ SG_ 2499549182 PayloadTemperature3 "Payload Temperature 3: Temperature of payload at measurement point 3.Measurement position is manufacturer or regulation specific.";
CM_ SG_ 2499549182 PayloadTemperature4 "Payload Temperature 4: Temperature of payload at measurement point 4.Measurement position is manufacturer or regulation specific.";
CM_ BO_ 2499556094 "Aftertreatment 1 Particulate Sensor Information 3";
CM_ SG_ 2499556094 Atttt1PttSsHtHSdDvDstStts "Aftertreatment 1 Particulate Sensor Heater High Side Driver Diagnostic Status: The value of this parameter is not retained when power is removed from the particulate sensor.000b = Tests monitored continuously. There are no enable or pause conditions....";
CM_ SG_ 2499556094 Atttt1PttSsHtHSdDvPFMI "Aftertreatment 1 Particulate Sensor Heater High Side Driver Preliminary FMI: Used to identify the applicable J1939-73 FMI detected in the aftertreatment particulate sensor heater high side driver by the manufacturer’s sensor control software in exhau...";
CM_ SG_ 2499556094 Atttt1PttSsHtLwSdDvDstStts "Aftertreatment 1 Particulate Sensor Heater Low Side Driver Diagnostic Status: The value of this parameter is not retained when power is removed from the particulate sensor.000b = Tests monitored continuously. There are no enable or pause conditions. ...";
CM_ SG_ 2499556094 Atttt1PttSsHtLwSdDvPFMI "Aftertreatment 1 Particulate Sensor Heater Low Side Driver Preliminary FMI: Used to identify the applicable J1939-73 FMI detected in the aftertreatment particulate sensor heater high side driver by the manufacturer’s sensor control software in exhaus...";
CM_ SG_ 2499556094 Atttt1PttSsHtPwSppDstStts "Aftertreatment 1 Particulate Sensor Heater Power Supply Diagnostic Status: The value of this parameter is not retained when power is removed from the particulate sensor.000b = Tests monitored continuously. There are no enable or pause conditions. See...";
CM_ SG_ 2499556094 Atttt1PttSsHtPwSppPFMI "Aftertreatment 1 Particulate Sensor Heater Power Supply Preliminary FMI: Used to identify the applicable J1939-73 FMI detected in the aftertreatment particulate sensor heater power supply by the manufacturer’s sensor control software in exhaust bank ...";
CM_ SG_ 2499556094 Atttt1PttSsIptDstStts "Aftertreatment 1 Particulate Sensor Input Diagnostic Status: The value of this parameter is not retained when power is removed from the particulate sensor.000b = Tests monitored continuously. There are no enable or pause conditions. See Aftertreatmen...";
CM_ SG_ 2499556094 Atttt1PttSsIptPFMI "Aftertreatment 1 Particulate Sensor Input Preliminary FMI: Used to identify the applicable J1939-73 FMI detected in the aftertreatment particulate sensor input by the manufacturer’s sensor control software in exhaust bank 1. In the case of multiple f...";
CM_ SG_ 2499556094 Atttt1PttSsPwSppDstStts "Aftertreatment 1 Particulate Sensor Power Supply Diagnostic Status: The value of this parameter is not retained when power is removed from the particulate sensor.000b = Tests monitored continuously. There are no enable or pause conditions. See Aftert...";
CM_ SG_ 2499556094 Atttt1PttSsPwSppPFMI "Aftertreatment 1 Particulate Sensor Power Supply Preliminary FMI: Used to identify the applicable J1939-73 FMI detected in the aftertreatment particulate sensor power supply by the manufacturer’s sensor control software in exhaust bank 1. In the case...";
CM_ BO_ 2499556350 "Engine Fuel Injector Metering Rail Pressure Information 3";
CM_ SG_ 2499556350 EngnFl1InjtrMtrngRl1DsrdPrssr "Engine Fuel 1 Injector Metering Rail 1 Desired Pressure: The desired pressure of fuel in the primary, or first, metering rail as delivered from the supply pump to the injector metering intake.";
CM_ SG_ 2499556350 EngnFl1InjtrMtrngRl2DsrdPrssr "Engine Fuel 1 Injector Metering Rail 2 Desired Pressure: The desired pressure of fuel in metering rail 2 as delivered from the supply pump to the injector metering intake.";
CM_ BO_ 2499556606 "Engine Fuel Injector Metering Rail Pressure Information 2";
CM_ SG_ 2499556606 EF1ItMtR1Pss1ExtddR "Engine Fuel 1 Injector Metering Rail 1 Pressure 1 (Extended Range): The pressure of fuel measured by first rail pressure sensor in the primary, or first, metering rail as delivered from the supply pump to the injector metering intake.";
CM_ SG_ 2499556606 EF1ItMtR1Pss2ExtddR "Engine Fuel 1 Injector Metering Rail 1 Pressure 2 (Extended Range): The pressure of fuel measured by the second rail pressure sensor in the primary, or first, metering rail as delivered from the supply pump to the injector metering intake.";
CM_ SG_ 2499556606 EF1ItMtR2Pss1ExtddR "Engine Fuel 1 Injector Metering Rail 2 Pressure 1 (Extended Range): The pressure of fuel measured by first rail pressure sensor in the metering rail 2 as delivered from the supply pump to the injector metering intake.";
CM_ SG_ 2499556606 EF1ItMtR2Pss2ExtddR "Engine Fuel 1 Injector Metering Rail 2 Pressure 2 (Extended Range): The pressure of fuel measured by second rail pressure sensor in the metering rail 2 as delivered from the supply pump to the injector metering intake.";
CM_ BO_ 2499557118 "Gaseous Fuel Supply Valve Information";
CM_ SG_ 2499557118 EngnGssFlSpplBldVlv1Pstn "Engine Gaseous Fuel Supply Bleed Valve 1 Position: Position of bleed valve 1, which is used to control the flow of gaseous fuel through the fuel supply unit. 0% represents valve fully closed and 100% represents valve fully open.";
CM_ SG_ 2499557118 EngnGssFlSpplBldVlv2Pstn "Engine Gaseous Fuel Supply Bleed Valve 2 Position: Position of bleed valve 2, which is used to control the flow of gaseous fuel through the fuel supply unit. 0% represents valve fully closed and 100% represents valve fully open.";
CM_ SG_ 2499557118 EngnGssFlSpplBldVlv3Pstn "Engine Gaseous Fuel Supply Bleed Valve 3 Position: Position of bleed valve 3, which is used to control the flow of gaseous fuel through the fuel supply unit. 0% represents valve fully closed and 100% represents valve fully open.";
CM_ SG_ 2499557118 EngnGssFlSpplShtffVlv1Pstn "Engine Gaseous Fuel Supply Shutoff Valve 1 Position: Position of shutoff valve 1, which is used to control the flow of gaseous fuel through the fuel supply unit. 0% represents valve fully closed and 100% represents valve fully open.";
CM_ SG_ 2499557118 EngnGssFlSpplShtffVlv2Pstn "Engine Gaseous Fuel Supply Shutoff Valve 2 Position: Position of shutoff valve 2, which is used to control the flow of gaseous fuel through the fuel supply unit. 0% represents valve fully closed and 100% represents valve fully open.";
CM_ SG_ 2499557118 InertGasSupplyValvePosition "Inert Gas Supply Valve Position: Position of inert gas supply valve used to control the flow of inert gas into the engine to purge the system.0% represents valve fully closed and 100% represents valve fully open.";
CM_ BO_ 2499557374 "Engine Oil Mist Detection Information 2";
CM_ SG_ 2499557374 EngineOilMist10Concentration "Engine Oil Mist 10 Concentration: Percentage of detected oil mist in compartment 10 compared to the lower explosion limit (LEL). 100% means the measured value is on the lower explosion limit,whereas 0% means no detected oil mist in the air.";
CM_ SG_ 2499557374 EngineOilMist9Concentration "Engine Oil Mist 9 Concentration: Percentage of detected oil mist in compartment 9 compared to the lower explosion limit (LEL). 100% means the measured value is on the lower explosion limit,whereas 0% means no detected oil mist in the air.";
CM_ BO_ 2499557630 "Engine Oil Mist Detection Information 1";
CM_ SG_ 2499557630 EngineOilMist1Concentration "Engine Oil Mist 1 Concentration: Percentage of detected oil mist in compartment 1 compared to the lower explosion limit (LEL). 100% means the measured value is on the lower explosion limit, whereas 0% means no detected oil mist in the air. This measu...";
CM_ SG_ 2499557630 EngineOilMist2Concentration "Engine Oil Mist 2 Concentration: Percentage of detected oil mist in compartment 2 compared to the lower explosion limit (LEL). 100% means the measured value is on the lower explosion limit,whereas 0% means no detected oil mist in the air.";
CM_ SG_ 2499557630 EngineOilMist3Concentration "Engine Oil Mist 3 Concentration: Percentage of detected oil mist in compartment 3 compared to the lower explosion limit (LEL). 100% means the measured value is on the lower explosion limit,whereas 0% means no detected oil mist in the air.";
CM_ SG_ 2499557630 EngineOilMist4Concentration "Engine Oil Mist 4 Concentration: Percentage of detected oil mist in compartment 4 compared to the lower explosion limit (LEL). 100% means the measured value is on the lower explosion limit,whereas 0% means no detected oil mist in the air.";
CM_ SG_ 2499557630 EngineOilMist5Concentration "Engine Oil Mist 5 Concentration: Percentage of detected oil mist in compartment 5 compared to the lower explosion limit (LEL). 100% means the measured value is on the lower explosion limit,whereas 0% means no detected oil mist in the air.";
CM_ SG_ 2499557630 EngineOilMist6Concentration "Engine Oil Mist 6 Concentration: Percentage of detected oil mist in compartment 6 compared to the lower explosion limit (LEL). 100% means the measured value is on the lower explosion limit,whereas 0% means no detected oil mist in the air.";
CM_ SG_ 2499557630 EngineOilMist7Concentration "Engine Oil Mist 7 Concentration: Percentage of detected oil mist in compartment 7 compared to the lower explosion limit (LEL). 100% means the measured value is on the lower explosion limit,whereas 0% means no detected oil mist in the air.";
CM_ SG_ 2499557630 EngineOilMist8Concentration "Engine Oil Mist 8 Concentration: Percentage of detected oil mist in compartment 8 compared to the lower explosion limit (LEL). 100% means the measured value is on the lower explosion limit,whereas 0% means no detected oil mist in the air.";
CM_ BO_ 2499557886 "Gaseous Fuel Supply Pressure 2";
CM_ SG_ 2499557886 PlntGssFlSpplOtltPrssr "Plant Gaseous Fuel Supply Outlet Pressure: Pressure of the gaseous fuel supplied from the plant room for one or more engines.  Based on the application, plant room will contain fuel tank for gas, vaporizer and heater and cooler compartments.";
CM_ SG_ 2499557886 PlntInrtGsSpplOtltPrssr "Plant Inert Gas Supply Outlet Pressure: Pressure of the purge gas supplied to the engine. Inert gas is used to remove gaseous fuel build-up in the engines and in the fuel supply lines when gaseous fuel is not in operation.";
CM_ BO_ 2499558142 "Gaseous Fuel Supply Pressure 1";
CM_ SG_ 2499558142 EngnGssFlSpplPrssr2 "Engine Gaseous Fuel Supply Pressure 2: Second gage pressure measurement of gaseous fuel supply to fuel metering device. If only one sensor is used for gas supply pressure measurement, use SPN 159 instead.";
CM_ SG_ 2499558142 EngnGssFlSpplShtffVlv1IntkPrssr "Engine Gaseous Fuel Supply Shutoff Valve 1 Intake Pressure: Pressure of gaseous fuel supply measured at shutoff valve 1 in gaseous fuel supply unit. Shutoff valves are used to regulate gaseous fuel supply to engine.";
CM_ SG_ 2499558142 EngnGssFlSpplShtffVlv2IntkPrssr "Engine Gaseous Fuel Supply Shutoff Valve 2 Intake Pressure: Pressure of gaseous fuel supply measured at shutoff valve 2 in gaseous fuel supply unit. Shutoff valves are used to regulate gaseous fuel supply to engine.";
CM_ SG_ 2499558142 EngnGssFlSpplUntIntkPrssr "Engine Gaseous Fuel Supply Unit Intake Pressure: Pressure of gaseous fuel supply measured at the intake of gaseous fuel supply unit. Gaseous fuel valve unit contains block and bleed valves to regulate the flow of gaseous fuel from the plant to engine...";
CM_ BO_ 2499580158 "Engine Fuel Injector Metering Rail Pressure Information 1";
CM_ SG_ 2499580158 EngnFl1InjtrMtrngRl1Prssr1 "Engine Fuel 1 Injector Metering Rail 1 Pressure 1: The pressure of fuel measured by first rail pressure sensor in the primary, or first, metering rail as delivered from the supply pump to the injector metering intake.Note:  This is for the rail press...";
CM_ SG_ 2499580158 EngnFl1InjtrMtrngRl1Prssr2 "Engine Fuel 1 Injector Metering Rail 1 Pressure 2: The pressure of fuel measured by the second rail pressure sensor in the primary, or first, metering rail as delivered from the supply pump to the injector metering intake. Note:  This is for the rail...";
CM_ SG_ 2499580158 EngnFl1InjtrMtrngRl2Prssr1 "Engine Fuel 1 Injector Metering Rail 2 Pressure 1: The pressure of fuel measured by first rail pressure sensor in the metering rail 2 as delivered from the supply pump to the injector metering intake.Note:  This is for the rail pressure from the 1st ...";
CM_ SG_ 2499580158 EngnFl1InjtrMtrngRl2Prssr2 "Engine Fuel 1 Injector Metering Rail 2 Pressure 2: The pressure of fuel measured by second rail pressure sensor in the metering rail 2 as delivered from the supply pump to the injector metering intake. Note:  This is for the rail pressure from the 2n...";
CM_ BO_ 2499582206 "Vehicle Speed Limiter";
CM_ SG_ 2499582206 SftTpSpdLmtRmnngCntnsIntrvlDstn "Soft Top Speed Limit Remaining Continuous Interval Distance: Indicates the remaining distance that the vehicle can continuously travel at the Soft Top Speed Limit.  This parameter will decrement while the Soft Top Speed Limit Active (SPN 6370) is 1 a...";
CM_ SG_ 2499582206 SftTpSpdLmtRmnngDstn "Soft Top Speed Limit Remaining Distance: Indicates the remaining distance that the vehicle can travel at the Soft Top Speed Limit within the larger reset window. The reset window may be distance (possibly indicated by SPN 6373), time, or something el...";
CM_ SG_ 2499582206 SoftTopRatioLimitExceeded "Soft Top Ratio Limit Exceeded: Greenhouse Gas Regulations limit the overall distance that Soft Top Speed can be used in relation to the total distance traveled. This parameter indicates the allowable ratio has been exceeded and Soft Top Speed is unav...";
CM_ SG_ 2499582206 SoftTopSpeedLimitActive "Soft Top Speed Limit Active: Indicates that the current Maximum Vehicle Speed Limit (SPN 74) has been temporarily increased to the Soft Top Speed Limit. Under certain conditions, the legal speed limit allowed by the Greenhouse Gas Regulations can be ...";
CM_ SG_ 2499582206 SoftTopSpeedLimitResetDistance "Soft Top Speed Limit Reset Distance: This parameter will decrement as long as the vehicle is moving. When this parameter reaches 0, it will be reset to its maximum value and continue to decrement.";
CM_ BO_ 2499583486 "Engine Timing Actuator Position Command";
CM_ SG_ 2499583486 EngnTmngAttr1PstnCmmnd "Engine Timing Actuator 1 Position Command: The commanded position of actuator 1 on the engine timing system by Engine Control Module.  The engine timing system has different timing positions and the timing positions may be used to determine intake an...";
CM_ SG_ 2499583486 EngnTmngAttr2PstnCmmnd "Engine Timing Actuator 2 Position Command: The commanded position of actuator 2 on the engine timing system by Engine Control Module.  The engine timing system has different timing positions and the timing positions may be used to determine intake an...";
CM_ BO_ 2499583742 "Engine Timing Actuator Position";
CM_ SG_ 2499583742 EngineTimingActuator1 "Engine Timing Actuator 1: The detected position of actuator 1 on the Engine Timing System, where the system has different timing positions depending on current operating status of the engine. Timing positions may be used to determine intake and outle...";
CM_ SG_ 2499583742 EngineTimingActuator2 "Engine Timing Actuator 2: The detected position of actuator 2 on the Engine Timing System, where the system has different timing positions depending on current operating status of the engine. Timing positions may be used to determine intake and outle...";
CM_ SG_ 2499583742 EngnTmngAttr1RqstdPstn "Engine Timing Actuator 1 Requested Position: The requested position of actuator 1 on the Engine Timing System, as determined by external system such as operator, monitoring, or protection system. Requested position is sent to the Control Module sendi...";
CM_ SG_ 2499583742 EngnTmngAttr2RqstdPstn "Engine Timing Actuator 2 Requested Position: The requested position of actuator 2 on the Engine Timing System, as determined by external system such as operator, monitoring or protection system. Requested position is sent to the Control Module sendin...";
CM_ BO_ 2499592190 "Electronic Transmission Controller #10";
CM_ SG_ 2499592190 TrnsmssnClth1AttrPrnt "Transmission Clutch 1 Actuator Percent: The current modulated value for the transmission clutch 1 actuator, where 0% = no hydraulic pressure and 100% = full hydraulic pressure.";
CM_ SG_ 2499592190 TrnsmssnClth1ClngAttrStts "Transmission Clutch 1 Cooling Actuator Status: Identifies the status of the actuator that cools transmission clutch 1.00b = off01b = on10b = error11b = not available";
CM_ SG_ 2499592190 TrnsmssnClth2AttrPrnt "Transmission Clutch 2 Actuator Percent: The current modulated value for the transmission clutch 2 actuator, where 0% = no hydraulic pressure and 100% = full hydraulic pressure.";
CM_ SG_ 2499592190 TrnsmssnClth2ClngAttrStts "Transmission Clutch 2 Cooling Actuator Status: Identifies the status of the actuator that cools transmission clutch 2.00b = off01b = on10b = error11b = not available";
CM_ SG_ 2499592190 TrnsmssnHdrlPmpAttr1Prnt "Transmission Hydraulic Pump Actuator 1 Percent: The current modulated value for the actuator that controls the transmission hydraulic pump, where 0% = no hydraulic pressure and 100% = full hydraulic pressure.";
CM_ SG_ 2499592190 TrnsmssnHdrlPmpAttr2Prnt "Transmission Hydraulic Pump Actuator 2 Percent: The current modulated value for actuator 2 that controls the transmission hydraulic pump, where 0% = no hydraulic pressure and 100% = full hydraulic pressure.";
CM_ SG_ 2499592190 TrnsmssnShftAttr1Prnt "Transmission Shift Actuator 1 Percent: The current modulated value for the transmission shift 1 actuator, where 0% = no hydraulic pressure and 100% = full hydraulic pressure.";
CM_ SG_ 2499592190 TrnsmssnShftAttr2Prnt "Transmission Shift Actuator 2 Percent: The current modulated value for the transmission shift 2 actuator, where 0% = no hydraulic pressure and 100% = full hydraulic pressure.";
CM_ SG_ 2499592190 TrnsmssnShftRl1AttrStts "Transmission Shift Rail 1 Actuator Status: Identifies the status of the actuator that moves the transmission shift rail identified as rail #1.00b = off01b = on10b = error11b = not available";
CM_ SG_ 2499592190 TrnsmssnShftRl2AttrStts "Transmission Shift Rail 2 Actuator Status: Identifies the status of the actuator that moves the transmission shift rail identified as rail #2.00b = off01b = on10b = error11b = not available";
CM_ SG_ 2499592190 TrnsmssnShftRl3AttrStts "Transmission Shift Rail 3 Actuator Status: Identifies the status of the actuator that moves the transmission shift rail identified as rail #3.00b = off01b = on10b = error11b = not available";
CM_ SG_ 2499592190 TrnsmssnShftRl4AttrStts "Transmission Shift Rail 4 Actuator Status: Identifies the status of the actuator that moves the transmission shift rail identified as rail #4.00b = off01b = on10b = error11b = not available";
CM_ SG_ 2499592190 TrnsmssnShftRl5AttrStts "Transmission Shift Rail 5 Actuator Status: Identifies the status of the actuator that moves the transmission shift rail identified as rail #5.00b = off01b = on10b = error11b = not available";
CM_ SG_ 2499592190 TrnsmssnShftRl6AttrStts "Transmission Shift Rail 6 Actuator Status: Identifies the status of the actuator that moves the transmission shift rail identified as rail #6.00b = off01b = on10b = error11b = not available";
CM_ BO_ 2499592446 "Electronic Transmission Controller #11";
CM_ SG_ 2499592446 TransmissionShiftRail1Position "Transmission Shift Rail 1 Position: The current position of transmission shift rail identified as rail #1.";
CM_ SG_ 2499592446 TransmissionShiftRail2Position "Transmission Shift Rail 2 Position: The current position of transmission shift rail identified as rail #2.";
CM_ SG_ 2499592446 TransmissionShiftRail3Position "Transmission Shift Rail 3 Position: The current position of transmission shift rail identified as rail #3.";
CM_ SG_ 2499592446 TransmissionShiftRail4Position "Transmission Shift Rail 4 Position: The current position of transmission shift rail identified as rail #4.";
CM_ SG_ 2499592446 TransmissionShiftRail5Position "Transmission Shift Rail 5 Position: The current position of transmission shift rail identified as rail #5.";
CM_ SG_ 2499592446 TransmissionShiftRail6Position "Transmission Shift Rail 6 Position: The current position of transmission shift rail identified as rail #6.";
CM_ BO_ 2499604222 "Land Leveling System Reference Elevation Data";
CM_ SG_ 2499604222 BladeElevationDeviationLeft "Blade Elevation Deviation - Left: Indicate the blade's left elevation deviation with respect to the reference elevation.  Serves as an indication of how far the left end of the blade is above or below grade.  A positive number indicates that the blad...";
CM_ SG_ 2499604222 BladeElevationDeviationRight "Blade Elevation Deviation - Right: Indicate the blade's right elevation deviation with respect to the reference elevation.  Serves as an indication of how far the left end of the blade is above or below grade.  A positive number indicates that the bl...";
CM_ SG_ 2499604222 BldRfrnElvtnOffstLft "Blade Reference Elevation Offset - Left: Indicates the blade's left elevation offset with respect to the reference elevation.  An offset of 0 m represents no offset from the reference elevation.  A positive number indicates that the offset elevation ...";
CM_ SG_ 2499604222 BldRfrnElvtnOffstRght "Blade Reference Elevation Offset - Right: Indicates the blade's right elevation offset with respect to the reference elevation.  An offset of 0 m represents no offset from the reference elevation.  A positive number indicates that the offset elevatio...";
CM_ BO_ 2499604478 "Engine Fluid Level/Pressure 11";
CM_ SG_ 2499604478 EExstGsRt1OttAstPssHRst "Engine Exhaust Gas Recirculation 1 Outlet Absolute Pressure (High Resolution): EGR outlet absolute pressure is measured after the EGR 1 valve. See SPN 5019 for 1 byte resolution.";
CM_ SG_ 2499604478 EFDvPssHRstExtddR "Engine Fuel Delivery Pressure (High Resolution/Extended Range): Gage pressure of fuel in system as delivered from supply pump to the injection pump. See SPN 94 for alternate resolution.See also SPN 5578 for Engine Fuel Delivery Absolute Pressure.";
CM_ SG_ 2499604478 EngnExhstGsRrltn1IntkAsltPrssr "Engine Exhaust Gas Recirculation 1 Intake Absolute Pressure: EGR intake absolute pressure measured before the EGR 1 valve.";
CM_ SG_ 2499604478 EngnOlPrssrHghRsltnExtnddRng "Engine Oil Pressure (High Resolution/Extended Range): Gage pressure of oil in engine lubrication system as provided by oil pump. See SPN 100 for alternate resolution.";
CM_ BO_ 2499607550 "Engine Manifold Actuator Position";
CM_ SG_ 2499607550 EExstMdB1FwBVvAttPst "Engine Exhaust Manifold Bank 1 Flow Balance Valve Actuator Position: Actual percentage of maximum Engine Exhaust Manifold Bank 1 Balance valve opening. 0% means valve is closed. 100% means maximum valve opening (full gas flow).";
CM_ SG_ 2499607550 EExstMdB2FwBVvAttPst "Engine Exhaust Manifold Bank 2 Flow Balance Valve Actuator Position: Actual percentage of maximum Engine Manifold Bank 2 Balance valve opening. 0% means valve is closed. 100% means maximum valve opening (full gas flow).";
CM_ BO_ 2499614462 "Occupant Classification System Information";
CM_ SG_ 2499614462 DrvrOpntClssftnSstmStts "Driver Occupant Classification System Status: State of Occupant Classification System for driver.000b = empty001b = child010b = small adult011b = adult100b = large adult101b = reserved110b = Error - Classification of occupant cannot be determined111b...";
CM_ SG_ 2499614462 OpntClssftnSstm10Stts "Occupant Classification System 10 Status: State of Occupant Classification System for seat position 10.00b = empty01b = occupied10b = Error - Classification cannot be determined11b = not available";
CM_ SG_ 2499614462 OpntClssftnSstm3Stts "Occupant Classification System 3 Status: State of Occupant Classification System for seat position 3.00b = empty01b = occupied10b = Error - Classification cannot be determined11b = not available";
CM_ SG_ 2499614462 OpntClssftnSstm4Stts "Occupant Classification System 4 Status: State of Occupant Classification System for seat position 4.00b = empty01b = occupied10b = Error - Classification cannot be determined11b = not available";
CM_ SG_ 2499614462 OpntClssftnSstm5Stts "Occupant Classification System 5 Status: State of Occupant Classification System for seat position 5.00b = empty01b = occupied10b = Error - Classification cannot be determined11b = not available";
CM_ SG_ 2499614462 OpntClssftnSstm6Stts "Occupant Classification System 6 Status: State of Occupant Classification System for seat position 6.00b = empty01b = occupied10b = Error - Classification cannot be determined11b = not available";
CM_ SG_ 2499614462 OpntClssftnSstm7Stts "Occupant Classification System 7 Status: State of Occupant Classification System for seat position 7.00b = empty01b = occupied10b = Error - Classification cannot be determined11b = not available";
CM_ SG_ 2499614462 OpntClssftnSstm8Stts "Occupant Classification System 8 Status: State of Occupant Classification System for seat position 8.00b = empty01b = occupied10b = Error - Classification cannot be determined11b = not available";
CM_ SG_ 2499614462 OpntClssftnSstm9Stts "Occupant Classification System 9 Status: State of Occupant Classification System for seat position 9.00b = empty01b = occupied10b = Error - Classification cannot be determined11b = not available";
CM_ SG_ 2499614462 PssngrOpntClssftnSstmStts "Passenger Occupant Classification System Status: State of Occupant Classification System for passenger.000b = empty001b = child010b = small adult011b = adult100b = large adult101b = Error - Classification of occupant cannot be determined110b = reserv...";
CM_ BO_ 2499614718 "Beltlock and Airbag Deactivation Switch Information";
CM_ SG_ 2499614718 Beltlock10Status "Beltlock 10 Status: State of switch used to determine if Beltlock 10 is buckled.00b = unlocked01b = locked10b = Error - Beltlock state cannot be determined11b = not available";
CM_ SG_ 2499614718 Beltlock3Status "Beltlock 3 Status: State of switch used to determine if Beltlock 3 is buckled.00b = unlocked01b = locked10b = Error - Beltlock state cannot be determined11b = not available";
CM_ SG_ 2499614718 Beltlock4Status "Beltlock 4 Status: State of switch used to determine if Beltlock 4 is buckled.00b = unlocked01b = locked10b = Error - Beltlock state cannot be determined11b = not available";
CM_ SG_ 2499614718 Beltlock5Status "Beltlock 5 Status: State of switch used to determine if Beltlock 5 is buckled.00b = unlocked01b = locked10b = Error - Beltlock state cannot be determined11b = not available";
CM_ SG_ 2499614718 Beltlock6Status "Beltlock 6 Status: State of switch used to determine if Beltlock 6 is buckled.00b = unlocked01b = locked10b = Error - Beltlock state cannot be determined11b = not available";
CM_ SG_ 2499614718 Beltlock7Status "Beltlock 7 Status: State of switch used to determine if Beltlock 7 is buckled.00b = unlocked01b = locked10b = Error - Beltlock state cannot be determined11b = not available";
CM_ SG_ 2499614718 Beltlock8Status "Beltlock 8 Status: State of switch used to determine if Beltlock 8 is buckled.00b = unlocked01b = locked10b = Error - Beltlock state cannot be determined11b = not available";
CM_ SG_ 2499614718 Beltlock9Status "Beltlock 9 Status: State of switch used to determine if Beltlock 9 is buckled.00b = unlocked01b = locked10b = Error - Beltlock state cannot be determined11b = not available";
CM_ SG_ 2499614718 DriverBeltlockStatus "Driver Beltlock Status: State of switch used to determine if Driver Beltlock is buckled.00b = unlocked01b = locked10b = Error - Beltlock state cannot be determined11b = not available";
CM_ SG_ 2499614718 PassengerBeltlockStatus "Passenger Beltlock Status: State of switch used to determine if Passenger Beltlock is buckled.00b = unlocked01b = locked10b = Error - Beltlock state cannot be determined11b = not available";
CM_ SG_ 2499614718 PssngrArgDtvtnSwthStts "Passenger Airbag Deactivation Switch Status: State of switch used to deactivate Passenger Airbag manually.00b = passenger airbag activated01b = passenger airbag deactivated10b = Error - State of deactivation switch cannot be determined11b = not avail...";
CM_ BO_ 2499624702 "Aftertreatment 1 SCR Exhaust Gas Temperature 1";
CM_ SG_ 2499624702 Aftrtrtmnt1SCRIntkTmprtr "Aftertreatment 1 SCR Intake Temperature: Temperature of engine combustion byproducts entering the SCR in exhaust bank 1.";
CM_ SG_ 2499624702 Aftrtrtmnt1SCROtltTmprtr "Aftertreatment 1 SCR Outlet Temperature: Temperature of engine combustion byproducts leaving the SCR outlet in exhaust bank 1.";
CM_ SG_ 2499624702 Atttt1SCRItTptPFMI "Aftertreatment 1 SCR Intake Temperature Preliminary FMI: Used to identify the applicable J1939-73 FMI detected in the SCR intake temperature sensor by the manufacturer’s sensor control software in exhaust bank 1.  In the case of multiple failures the...";
CM_ SG_ 2499624702 Atttt1SCROttTptPFMI "Aftertreatment 1 SCR Outlet Temperature Preliminary FMI: Used to identify the applicable J1939-73 FMI detected in the SCR outlet temperature sensor by the manufacturer’s sensor control software in exhaust bank 1. In the case of multiple failures the ...";
CM_ BO_ 2499630078 "Engine Average Information";
CM_ SG_ 2499630078 EngineExhaustTemperatureAverage "Engine Exhaust Temperature Average: The calculated average temperature based upon all of the engine exhaust port temperatures.  This is the average temperature based upon the exhaust port temperature measurements at each of the engine cylinders.Notes...";
CM_ SG_ 2499630078 EngnExhstBnk1TmprtrAvrg "Engine Exhaust Bank 1 Temperature Average: The calculated average temperature based upon all of the Bank 1 (left bank) engine exhaust port temperatures.  This is the average temperature based upon the exhaust port temperature measurements of each of ...";
CM_ SG_ 2499630078 EngnExhstBnk2TmprtrAvrg "Engine Exhaust Bank 2 Temperature Average: The calculated average temperature based upon all of the Bank 2 (right bank) engine exhaust port temperatures.  This is the average temperature based upon the exhaust port temperature measurements of each of...";
CM_ BO_ 2499635454 "Gross Combination Vehicle Weight";
CM_ SG_ 2499635454 GrossCombinationWeight "Gross Combination Weight: Total weight of the truck and all the trailers with on-board scales.";
CM_ SG_ 2499635454 NetVehicleWeightChange "Net Vehicle Weight Change: Identifies the net vehicle weight change from the time of last vehicle net weight zeroing.";
CM_ BO_ 2499635966 "Axle Group Weight";
CM_ SG_ 2499635966 AdditionalAxleGroupLocation "Additional Axle Group Location: Location of the axle group, listed from front of the vehicle to rear.  If the value of SPN 4073 is 15, then this SP is used to indicate the axle group referred to by this PG. Otherwise, this SP should be broadcast as 1...";
CM_ SG_ 2499635966 AxleGroupLocation "Axle Group Location: Specific axle group used in conjunction with and when communicating the axle group weight, listed from the front of the vehicle to the rear.If the value of SPN 5935 is 1111b, then this SP is used to indicate the axle group referr...";
CM_ SG_ 2499635966 AxleGroupWeight "Axle Group Weight: Total mass imposed on the road surface by all the tires in the axle group";
CM_ BO_ 2499641854 "EGR Cooler Bypass";
CM_ SG_ 2499641854 EExstGsRt1CBpssAttPst "Engine Exhaust Gas Recirculation 1 Cooler Bypass Actuator Position: The parameter gives the % open of the exhaust gas recirculation cooler bypass actuator, where 0% = Fully Closed (no gas flowing through the bypass), and 100% = Fully Open.";
CM_ BO_ 2550660862 "General Purpose Valve Pressure";
CM_ SG_ 2550660862 ValveAssemblyLoadsensePressure "Valve Assembly Load sense Pressure: The maximum pressure of a valve assembly's current collective load sense pressures where a valve assembly can consist of two or more valves.";
CM_ SG_ 2550660862 ValveAssemblySupplyPressure "Valve Assembly Supply Pressure: Pressure of the hydraulic supply port to a valve assembly.";
CM_ SG_ 2550660862 ValveLoadSensePressure "Valve Load Sense Pressure: The maximum of the currently measured pressures of a valve's work port A and work port B.";
CM_ SG_ 2550660862 ValvePilotPressure "Valve Pilot Pressure: Pressure of a valve's pilot supply port.";
CM_ BO_ 2550988542 "Electronic Engine Controller 16";
CM_ SG_ 2550988542 EngineClutchEngageRequestStatus "Engine Clutch Engage Request Status: Indicates if the engine has an external request to establish its operating conditions to be appropriate for engagement of the transmission or gearbox.00b = Engine does not have an external request01b = Engine has ...";
CM_ SG_ 2550988542 ReadyForClutchEngagementStatus "Ready For Clutch Engagement Status: Indicates the engine operating conditions are appropriate for engagement of the transmission or gearbox clutch.00b = Engine Not Ready For Clutch Engagement01b = Engine is Ready For Clutch Engagement10b = Error11b =...";
CM_ SG_ 2550988542 AcceleratorPedal3Position "Accelerator Pedal 3 Position: The ratio of actual position of the third analog engine speed/torque request input device (such as an accelerator pedal or throttle lever) to the maximum position of the input device.  This parameter is intended for the ...";
CM_ BO_ 2557214462 "Well Stimulation Pump Sensor Calibration Command";
CM_ SG_ 2557214462 WSttPpDsPssCtStPtCd "Well Stimulation Pump Discharge Pressure Calibration Set Point Command: Specifies the current discharge pressure whose calibration status is being reported. Multipoint calibration of the discharge pressure system is performed by increasing the pressu...";
CM_ SG_ 2557214462 WSttPpStPssCtStPtCd "Well Stimulation Pump Suction Pressure Calibration Set Point Command: Specifies the current suction pressure being calibrated. Multipoint calibration of the suction pressuresystem is performed by increasing the pressure with up to 10 known calibratio...";
CM_ BO_ 2557345534 "Well Stimulation Pump System Configuration Command";
CM_ SG_ 2557345534 WllStmltnPmpPlngrFrngOrdr "Well Stimulation Pump Plunger Firing Order: Well stimulation pump plunger firing order0000b = Firing order 1-2-30001b = Firing order 1-5-2-3-40010b = Reserved0011b = Reserved0100b = Reserved0101b = Reserved0110b = Reserved0111b = Reserved1000b = Rese...";
CM_ SG_ 2557345534 WllStmltnPmpRdLdHghThrshld "Well Stimulation Pump Rod Load High Threshold: Rod load force at which the rod load is considered at the highest acceptable force.";
CM_ SG_ 2557345534 WllStmltnPmpStnPrssrHghThrshld "Well Stimulation Pump Suction Pressure High Threshold: Pressure at which the suction pressure is considered at the highest acceptable pressure.";
CM_ SG_ 2557345534 WllStmltnPmpStnPrssrLwThrshld "Well Stimulation Pump Suction Pressure Low Threshold: Pressure at which the suction pressure is considered at the lowest acceptable pressure.";
CM_ SG_ 2557345534 WSttPpCstSpdHTsd "Well Stimulation Pump Crankshaft Speed High Threshold: Well stimulation pump crankshaft speed that has been considered to be the highest acceptable speed.";
CM_ SG_ 2557345534 WSttPpCstSpdLwTsd "Well Stimulation Pump Crankshaft Speed Low Threshold: The minimum speed of Well stimulation pump crankshaft that is considered to be valid.";
CM_ SG_ 2557345534 WSttPpDsPssHTsd "Well Stimulation Pump Discharge Pressure High Threshold: Pressure at which the discharge pressure is considered at the highest acceptable pressure.";
CM_ SG_ 2557345534 WSttPpGBxOPssHTsd "Well Stimulation Pump Gear Box Oil Pressure High Threshold: Pressure at which the gearbox oil pressure is considered at the highest acceptable pressure.";
CM_ SG_ 2557345534 WSttPpGBxOPssLwTsd "Well Stimulation Pump Gear Box Oil Pressure Low Threshold: Pressure at which the gearbox oil pressure is considered at the lowest acceptable pressure.";
CM_ SG_ 2557345534 WSttPpGBxOTptHTsd "Well Stimulation Pump Gear Box Oil Temperature High Threshold: Temperature at which the gearbox oil temperature is considered at the highest acceptable temperature.";
CM_ SG_ 2557345534 WSttPpGBxOTptLwTsd "Well Stimulation Pump Gear Box Oil Temperature Low Threshold: Temperature at which the gearbox oil temperature is considered at the lowest acceptable temperature.";
CM_ BO_ 2557673214 "Oil Debris Monitor Configuration Command";
CM_ SG_ 2557673214 OlDrsMntrCnfgrtnIdntftnNmr "Oil Debris Monitor Configuration Identification Number: Identification number of the Oil Debris Monitoring (ODM) sensor being configured. Identification numbers are application specific.";
CM_ SG_ 2557673214 OlDrsMntrFrrsBn1CntCmmnd "Oil Debris Monitor Ferrous Bin 1 Count Command: New starting value for total count of particles detected in Ferrous bin 1.NOTE: The value FFFFFFh indicates Do Not Change (i.e. the current count value of the Oil Debris Monitor for this bin will not be...";
CM_ SG_ 2557673214 OlDrsMntrFrrsBn2CntCmmnd "Oil Debris Monitor Ferrous Bin 2 Count Command: New starting value for total count of particles detected in Ferrous bin 2.NOTE: The value FFFFFFh indicates Do Not Change (i.e. the current count value of the Oil Debris Monitor for this bin will not be...";
CM_ SG_ 2557673214 OlDrsMntrFrrsBn3CntCmmnd "Oil Debris Monitor Ferrous Bin 3 Count Command: New starting value for total count of particles detected in Ferrous bin 3.NOTE: The value FFFFFFh indicates Do Not Change (i.e. the current count value of the Oil Debris Monitor for this bin will not be...";
CM_ SG_ 2557673214 OlDrsMntrFrrsBn4CntCmmnd "Oil Debris Monitor Ferrous Bin 4 Count Command: New starting value for total count of particles detected in Ferrous bin 4.NOTE: The value FFFFFFh indicates Do Not Change (i.e. the current count value of the Oil Debris Monitor for this bin will not be...";
CM_ SG_ 2557673214 OlDrsMntrFrrsBn5CntCmmnd "Oil Debris Monitor Ferrous Bin 5 Count Command: New starting value for total count of particles detected in Ferrous bin 5.NOTE: The value FFFFFFh indicates Do Not Change (i.e. the current count value of the Oil Debris Monitor for this bin will not be...";
CM_ SG_ 2557673214 OlDrsMntrFrrsBn6CntCmmnd "Oil Debris Monitor Ferrous Bin 6 Count Command: New starting value for total count of particles detected in Ferrous bin 6.NOTE: The value FFFFFFh indicates Do Not Change (i.e. the current count value of the Oil Debris Monitor for this bin will not be...";
CM_ SG_ 2557673214 OlDrsMntrNnFrrsBn1CntCmmnd "Oil Debris Monitor Non-Ferrous Bin 1 Count Command: New starting value for total count of particles detected in Non-Ferrous bin 1.NOTE: The value FFFFFFh indicates Do Not Change (i.e. the current count value of the Oil Debris Monitor for this bin wil...";
CM_ SG_ 2557673214 OlDrsMntrNnFrrsBn2CntCmmnd "Oil Debris Monitor Non-Ferrous Bin 2 Count Command: New starting value for total count of particles detected in Non-Ferrous bin 2.NOTE: The value FFFFFFh indicates Do Not Change (i.e. the current count value of the Oil Debris Monitor for this bin wil...";
CM_ SG_ 2557673214 OlDrsMntrNnFrrsBn3CntCmmnd "Oil Debris Monitor Non-Ferrous Bin 3 Count Command: New starting value for total count of particles detected in Non-Ferrous bin 3.NOTE: The value FFFFFFh indicates Do Not Change (i.e. the current count value of the Oil Debris Monitor for this bin wil...";
CM_ SG_ 2557673214 OlDrsMntrNnFrrsBn4CntCmmnd "Oil Debris Monitor Non-Ferrous Bin 4 Count Command: New starting value for total count of particles detected in Non-Ferrous bin 4.NOTE: The value FFFFFFh indicates Do Not Change (i.e. the current count value of the Oil Debris Monitor for this bin wil...";
CM_ SG_ 2557673214 OlDrsMntrNnFrrsBn5CntCmmnd "Oil Debris Monitor Non-Ferrous Bin 5 Count Command: New starting value for total count of particles detected in Non-Ferrous bin 5.NOTE: The value FFFFFFh indicates Do Not Change (i.e. the current count value of the Oil Debris Monitor for this bin wil...";
CM_ SG_ 2557673214 OlDrsMntrNnFrrsBn6CntCmmnd "Oil Debris Monitor Non-Ferrous Bin 6 Count Command: New starting value for total count of particles detected in Non-Ferrous bin 6.NOTE: The value FFFFFFh indicates Do Not Change (i.e. the current count value of the Oil Debris Monitor for this bin wil...";
CM_ BO_ 2557738750 "Electrified Accessory Propulsion Motor Coolant Fan 3 Command";
CM_ SG_ 2557738750 PrplsnMtrClntFn3EnlCmmnd "Propulsion Motor Coolant Fan 3 Enable Command: Enable and direction command to the Propulsion Motor Coolant Fan 3.00b = Accessory Motor Off01b = Accessory Motor On Normal/Default Direction10b = Accessory Motor On Reverse Direction11b = Don't Care/Tak...";
CM_ SG_ 2557738750 PrplsnMtrClntFn3PrntSpdCmmnd "Propulsion Motor Coolant Fan 3 Percent Speed Command: Speed command to the Propulsion Motor Coolant Fan 3 in percentage of maximum speed.Note: Both Speed Command and Percent Speed Command cannot be used at the same time.  Always set the unused speed ...";
CM_ SG_ 2557738750 PrplsnMtrClntFn3PwrHld "Propulsion Motor Coolant Fan 3 Power Hold: Command to allow the Propulsion Motor Coolant Fan 3 to remain alive independently of the electrical enable input to the Accessory Motor.  For example, this could allow continued device operation after the ke...";
CM_ SG_ 2557738750 PrplsnMtrClntFn3SpdCmmnd "Propulsion Motor Coolant Fan 3 Speed Command: Speed command to the Propulsion Motor Coolant Fan 3.Note: Both Speed Command and Percent Speed Command cannot be used at the same time.  Always set the unused speed command to Not Available.  If both comm...";
CM_ BO_ 2557804286 "Electrified Accessory Propulsion Motor Coolant Fan 2 Command";
CM_ SG_ 2557804286 PrplsnMtrClntFn2EnlCmmnd "Propulsion Motor Coolant Fan 2 Enable Command: Enable and direction command to the Power Motor Coolant Fan 2.00b = Accessory Motor Off01b = Accessory Motor On Normal/Default Direction10b = Accessory Motor On Reverse Direction11b = Don't Care/Take no ...";
CM_ SG_ 2557804286 PrplsnMtrClntFn2PrntSpdCmmnd "Propulsion Motor Coolant Fan 2 Percent Speed Command: Speed command to the Propulsion Motor Coolant Fan 2 in percentage of maximum speed.Note: Both Speed Command and Percent Speed Command cannot be used at the same time.  Always set the unused speed ...";
CM_ SG_ 2557804286 PrplsnMtrClntFn2PwrHld "Propulsion Motor Coolant Fan 2 Power Hold: Command to allow the Propulsion Motor Coolant Fan 2 to remain alive independently of the electrical enable input to the Accessory Motor.  For example, this could allow continued device operation after the ke...";
CM_ SG_ 2557804286 PrplsnMtrClntFn2SpdCmmnd "Propulsion Motor Coolant Fan 2 Speed Command: Speed command to the Propulsion Motor Coolant Fan 2.Note: Both Speed Command and Percent Speed Command cannot be used at the same time.  Always set the unused speed command to Not Available.  If both comm...";
CM_ BO_ 2557869822 "Electrified Accessory Propulsion Motor Coolant Fan 1 Command";
CM_ SG_ 2557869822 PrplsnMtrClntFn1EnlCmmnd "Propulsion Motor Coolant Fan 1 Enable Command: Enable and direction command to the Propulsion Motor Coolant Fan 1.00b = Accessory Motor Off01b = Accessory Motor On Normal/Default Direction10b = Accessory Motor On Reverse Direction11b = Don't Care/Tak...";
CM_ SG_ 2557869822 PrplsnMtrClntFn1PrntSpdCmmnd "Propulsion Motor Coolant Fan 1 Percent Speed Command: Speed command to the Propulsion Motor Coolant Fan 1 in percentage of maximum speed.Note: Both Speed Command and Percent Speed Command cannot be used at the same time.  Always set the unused speed ...";
CM_ SG_ 2557869822 PrplsnMtrClntFn1PwrHld "Propulsion Motor Coolant Fan 1 Power Hold: Command to allow the Propulsion Motor Coolant Fan 1 to remain alive independently of the electrical enable input to the Accessory Motor.  For example, this could allow continued device operation after the ke...";
CM_ SG_ 2557869822 PrplsnMtrClntFn1SpdCmmnd "Propulsion Motor Coolant Fan 1 Speed Command: Speed command to the Propulsion Motor Coolant Fan 1.Note: Both Speed Command and Percent Speed Command cannot be used at the same time.  Always set the unused speed command to Not Available.  If both comm...";
CM_ BO_ 2557935358 "Electrified Accessory Power Electronics Coolant Fan 3 Command";
CM_ SG_ 2557935358 PwrEltrnsClntFn3EnlCmmnd "Power Electronics Coolant Fan 3 Enable Command: Enable and direction command to the Power Electonics Coolant Fan 3.00b = Accessory Motor Off01b = Accessory Motor On Normal/Default Direction10b = Accessory Motor On Reverse Direction11b = Don't Care/Ta...";
CM_ SG_ 2557935358 PwrEltrnsClntFn3PrntSpdCmmnd "Power Electronics Coolant Fan 3 Percent Speed Command: Speed command to the Power Electronics Coolant Fan 3 in percentage of maximum speed.Note: Both Speed Command and Percent Speed Command cannot be used at the same time.  Always set the unused spee...";
CM_ SG_ 2557935358 PwrEltrnsClntFn3PwrHld "Power Electronics Coolant Fan 3 Power Hold: Command to allow the Power Electronics Coolant Fan 3 to remain alive independently of the electrical enable input to the Accessory Motor.  For example, this could allow continued device operation after the ...";
CM_ SG_ 2557935358 PwrEltrnsClntFn3SpdCmmnd "Power Electronics Coolant Fan 3 Speed Command: Speed command to the Power Electronics Coolant Fan 3.Note: Both Speed Command and Percent Speed Command cannot be used at the same time.  Always set the unused speed command to Not Available.  If both co...";
CM_ BO_ 2558000894 "Electrified Accessory Power Electronics Coolant Fan 2 Command";
CM_ SG_ 2558000894 PwrEltrnsClntFn2EnlCmmnd "Power Electronics Coolant Fan 2 Enable Command: Enable and direction command to the Power Electonics Coolant Fan 2.00b = Accessory Motor Off01b = Accessory Motor On Normal/Default Direction10b = Accessory Motor On Reverse Direction11b = Don't Care/Ta...";
CM_ SG_ 2558000894 PwrEltrnsClntFn2PrntSpdCmmnd "Power Electronics Coolant Fan 2 Percent Speed Command: Speed command to the Power Electronics Coolant Fan 2 in percentage of maximum speed.Note: Both Speed Command and Percent Speed Command cannot be used at the same time.  Always set the unused spee...";
CM_ SG_ 2558000894 PwrEltrnsClntFn2PwrHld "Power Electronics Coolant Fan 2 Power Hold: Command to allow the Power Electronics Coolant Fan 2 to remain alive independently of the electrical enable input to the Accessory Motor.  For example, this could allow continued device operation after the ...";
CM_ SG_ 2558000894 PwrEltrnsClntFn2SpdCmmnd "Power Electronics Coolant Fan 2 Speed Command: Speed command to the Power Electronics Coolant Fan 2.Note: Both Speed Command and Percent Speed Command cannot be used at the same time.  Always set the unused speed command to Not Available.  If both co...";
CM_ BO_ 2558066430 "Electrified Accessory Power Electronics Coolant Fan 1 Command";
CM_ SG_ 2558066430 PwrEltrnsClntFn1EnlCmmnd "Power Electronics Coolant Fan 1 Enable Command: Enable and direction command to the Power Electonics Coolant Fan 1.00b = Accessory Motor Off01b = Accessory Motor On Normal/Default Direction10b = Accessory Motor On Reverse Direction11b = Don't Care/Ta...";
CM_ SG_ 2558066430 PwrEltrnsClntFn1PrntSpdCmmnd "Power Electronics Coolant Fan 1 Percent Speed Command: Speed command to the Power Electronics Coolant Fan 1 in percentage of maximum speed.Note: Both Speed Command and Percent Speed Command cannot be used at the same time.  Always set the unused spee...";
CM_ SG_ 2558066430 PwrEltrnsClntFn1PwrHld "Power Electronics Coolant Fan 1 Power Hold: Command to allow the Power Electronics Coolant Fan 1 to remain alive independently of the electrical enable input to the Accessory Motor.  For example, this could allow continued device operation after the ...";
CM_ SG_ 2558066430 PwrEltrnsClntFn1SpdCmmnd "Power Electronics Coolant Fan 1 Speed Command: Speed command to the Power Electronics Coolant Fan 1.Note: Both Speed Command and Percent Speed Command cannot be used at the same time.  Always set the unused speed command to Not Available.  If both co...";
CM_ BO_ 2558131966 "Electrified Accessory Propulsion Motor Oil Pump Command";
CM_ SG_ 2558131966 PropulsionMotorOilPumpPowerHold "Propulsion Motor Oil Pump Power Hold: Command to allow the Propulsion Motor Oil Pump to remain alive independently of the electrical enable input to the Accessory Motor.  For example, this could allow continued device operation after the keyswitch ha...";
CM_ SG_ 2558131966 PrplsnMtrOlPmpEnlCmmnd "Propulsion Motor Oil Pump Enable Command: Enable and direction command to the Propulsion Motor Oil Pump.00b = Accessory Motor Off01b = Accessory Motor On Normal/Default Direction10b = Accessory Motor On Reverse Direction11b = Don't Care/Take no actio...";
CM_ SG_ 2558131966 PrplsnMtrOlPmpPrntSpdCmmnd "Propulsion Motor Oil Pump Percent Speed Command: Speed command to the Propulsion Motor Oil Pump in percentage of maximum speed.Note: Both Speed Command and Percent Speed Command cannot be used at the same time.  Always set the unused speed command to...";
CM_ SG_ 2558131966 PrplsnMtrOlPmpSpdCmmnd "Propulsion Motor Oil Pump Speed Command: Speed command to the Propulsion Motor Oil Pump. Note: Both Speed Command and Percent Speed Command cannot be used at the same time.  Always set the unused speed command to Not Available.  If both commands are ...";
CM_ BO_ 2558197502 "Electrified Accessory Propulsion Motor Coolant Pump Command";
CM_ SG_ 2558197502 PrplsnMtrClntPmpEnlCmmnd "Propulsion Motor Coolant Pump Enable Command: Enable and direction command to the Propulsion Motor Coolant Pump.00b = Accessory Motor Off01b = Accessory Motor On Normal/Default Direction10b = Accessory Motor On Reverse Direction11b = Don't Care/Take ...";
CM_ SG_ 2558197502 PrplsnMtrClntPmpPrntSpdCmmnd "Propulsion Motor Coolant Pump Percent Speed Command: Speed command to the Propulsion Motor Coolant Pump in percentage of maximum speed.Note: Both Speed Command and Percent Speed Command cannot be used at the same time.  Always set the unused speed co...";
CM_ SG_ 2558197502 PrplsnMtrClntPmpPwrHld "Propulsion Motor Coolant Pump Power Hold: Command to allow the Propulsion Motor Coolant Pump to remain alive independently of the electrical enable input to the Accessory Motor.  For example, this could allow continued device operation after the keys...";
CM_ SG_ 2558197502 PrplsnMtrClntPmpSpdCmmnd "Propulsion Motor Coolant Pump Speed Command: Speed command to the Propulsion Motor Coolant Pump. Note: Both Speed Command and Percent Speed Command cannot be used at the same time.  Always set the unused speed command to Not Available.  If both comma...";
CM_ BO_ 2558263038 "Electrified Accessory Power Electronics Coolant Pump Command";
CM_ SG_ 2558263038 PwrEltrnsClntPmpEnlCmmnd "Power Electronics Coolant Pump Enable Command: Enable and direction command to the Power Electonics Coolant Pump.00b = Accessory Motor Off01b = Accessory Motor On Normal/Default Direction10b = Accessory Motor On Reverse Direction11b = Don't Care/Take...";
CM_ SG_ 2558263038 PwrEltrnsClntPmpPrntSpdCmmnd "Power Electronics Coolant Pump Percent Speed Command: Speed command to the Power Electronics Coolant Pump in percentage of maximum speed.Note: Both Speed Command and Percent Speed Command cannot be used at the same time.  Always set the unused speed ...";
CM_ SG_ 2558263038 PwrEltrnsClntPmpPwrHld "Power Electronics Coolant Pump Power Hold: Command to allow the Power Electronics Coolant Pump to remain alive independently of the electrical enable input to the Accessory Motor.  For example, this could allow continued device operation after the ke...";
CM_ SG_ 2558263038 PwrEltrnsClntPmpSpdCmmnd "Power Electronics Coolant Pump Speed Command: Speed command to the Power Electronics Coolant Pump.Note: Both Speed Command and Percent Speed Command cannot be used at the same time.  Always set the unused speed command to Not Available.  If both comm...";
BA_DEF_ SG_  "SPN" INT 0 524287;
BA_DEF_ BO_  "VFrameFormat" ENUM  "StandardCAN","ExtendedCAN","reserved","J1939PG";
BA_DEF_DEF_  "SPN" 0;
BA_DEF_DEF_  "VFrameFormat" "J1939PG";
BA_ "SPN" SG_ 2365484286 Directionindicator 1619;
BA_ "SPN" SG_ 2365484286 Driver1TimeRelatedStates 1617;
BA_ "SPN" SG_ 2365484286 Driver1workingstate 1612;
BA_ "SPN" SG_ 2365484286 Driver2TimeRelatedStates 1618;
BA_ "SPN" SG_ 2365484286 Driver2workingstate 1613;
BA_ "SPN" SG_ 2365484286 Drivercarddriver1 1615;
BA_ "SPN" SG_ 2365484286 Drivercarddriver2 1616;
BA_ "SPN" SG_ 2365484286 Handlinginformation 1621;
BA_ "SPN" SG_ 2365484286 Systemevent 1622;
BA_ "SPN" SG_ 2365484286 Tachographoutputshaftspeed 1623;
BA_ "SPN" SG_ 2365484286 Tachographperformance 1620;
BA_ "SPN" SG_ 2365484286 Tachographvehiclespeed 1624;
BA_ "SPN" SG_ 2365484286 Vehiclemotion 1611;
BA_ "SPN" SG_ 2365484286 VehicleOverspeed 1614;
BA_ "SPN" SG_ 2365485566 LaserTracerHorizontalDeviation 1581;
BA_ "SPN" SG_ 2365485566 LaserTracerInformation 1583;
BA_ "SPN" SG_ 2365485566 LaserTracerTargetDeviation 1579;
BA_ "SPN" SG_ 2365485566 LaserTracerVerticalDistance 1580;
BA_ "SPN" SG_ 2365485566 LEDDisplayData2 1582;
BA_ "SPN" SG_ 2365485822 BladeControlMode 1578;
BA_ "SPN" SG_ 2365485822 BladeControlModeLeft 5407;
BA_ "SPN" SG_ 2365485822 BladeControlModeRight 5408;
BA_ "SPN" SG_ 2365485822 BladeDurationandDirection 1577;
BA_ "SPN" SG_ 2365485822 LandLevelingSystemEnableStatus 5409;
BA_ "SPN" SG_ 2365486078 MastPosition 1576;
BA_ "SPN" SG_ 2365486334 BldHghtStPntHghRsltn 1759;
BA_ "SPN" SG_ 2365486334 ModifyLevelingSystemSetPoint 1575;
BA_ "SPN" SG_ 2365486590 AbsoluteLaserStrikePosition 2794;
BA_ "SPN" SG_ 2365486590 LaserReceiverType 2576;
BA_ "SPN" SG_ 2365486590 LaserStrikeDataLatency 2793;
BA_ "SPN" SG_ 2365486590 LaserStrikeVerticalDeviation 1574;
BA_ "SPN" SG_ 2431649790 DriverAlertnessWarning 7473;
BA_ "SPN" SG_ 2431649790 LaneDepartureImminentLeftSide 1700;
BA_ "SPN" SG_ 2431649790 LaneDepartureImminentRightSide 1701;
BA_ "SPN" SG_ 2431649790 LaneDepartureLeft 3565;
BA_ "SPN" SG_ 2431649790 LaneDepartureRight 3566;
BA_ "SPN" SG_ 2431649790 LftSdLnDprtrAstlWrnngCmmnd 8138;
BA_ "SPN" SG_ 2431649790 LftSdLnDprtrOptlWrnngCmmnd 8136;
BA_ "SPN" SG_ 2431649790 RghtSdLnDprtrAstlWrnngCmmnd 8137;
BA_ "SPN" SG_ 2431649790 RghtSdLnDprtrOptlWrnngCmmnd 8135;
BA_ "SPN" SG_ 2431649790 RghtSdLnDprtrHptWrnngCmmnd 9749;
BA_ "SPN" SG_ 2431649790 LftSdLnDprtrHptWrnngCmmnd 9750;
BA_ "SPN" SG_ 2431654654 EngnFlAttr1CntrlCmmnd 633;
BA_ "SPN" SG_ 2431654654 EngnFlAttr2CntrlCmmnd 1244;
BA_ "SPN" SG_ 2431654654 EngnThrttlAttr1CntrlCmmnd 3464;
BA_ "SPN" SG_ 2431654654 EngnThrttlAttr2CntrlCmmnd 3465;
BA_ "SPN" SG_ 2431661054 Aftrtrtmnt1SCRIntrmdtNH3 5848;
BA_ "SPN" SG_ 2431661054 Aftrtrtmnt1SCRIntrmdtNH3RdngStl 5850;
BA_ "SPN" SG_ 2431661054 Atttt1SCRItdtNH3SsHtCt 5854;
BA_ "SPN" SG_ 2431661054 Atttt1SCRItdtNH3SsHtPFMI 5853;
BA_ "SPN" SG_ 2431661054 Atttt1SCRItdtNH3SsPFMI 5849;
BA_ "SPN" SG_ 2431661054 Atttt1SCRItdtNH3SsPwIR 5851;
BA_ "SPN" SG_ 2431661054 Atttt1SCRItdtNH3SstTpt 5852;
BA_ "SPN" SG_ 2431661310 Aftrtrtmnt2SCRIntrmdtNH3 5855;
BA_ "SPN" SG_ 2431661310 Aftrtrtmnt2SCRIntrmdtNH3RdngStl 5857;
BA_ "SPN" SG_ 2431661310 Atttt2SCRItdtNH3SsHtCt 5861;
BA_ "SPN" SG_ 2431661310 Atttt2SCRItdtNH3SsHtPFMI 5860;
BA_ "SPN" SG_ 2431661310 Atttt2SCRItdtNH3SsPFMI 5856;
BA_ "SPN" SG_ 2431661310 Atttt2SCRItdtNH3SsPwIR 5858;
BA_ "SPN" SG_ 2431661310 Atttt2SCRItdtNH3SstTpt 5859;
BA_ "SPN" SG_ 2431708670 EngineStartAbortRequest 7747;
BA_ "SPN" SG_ 2431708670 EngineStartConsent 7746;
BA_ "SPN" SG_ 2431708670 EngineStartControlChecksum 7751;
BA_ "SPN" SG_ 2431708670 EngineStarter1Feedback 7748;
BA_ "SPN" SG_ 2431708670 EngineStarter2Feedback 7749;
BA_ "SPN" SG_ 2431708670 EngineStartRequest 7745;
BA_ "SPN" SG_ 2431708670 EngnStrtCntrlMssgCntr 7750;
BA_ "SPN" SG_ 2431708670 TrnsmssnShftSltrRqstdVhlDrtn 7788;
BA_ "SPN" SG_ 2431710718 AtmtEngnStrtCnsntSmmr 7756;
BA_ "SPN" SG_ 2431710718 EngineStartArbitratorChecksum 7758;
BA_ "SPN" SG_ 2431710718 EngineStartControlMessageRate 7752;
BA_ "SPN" SG_ 2431710718 EngineStarterCommand 7753;
BA_ "SPN" SG_ 2431710718 EngineStartRequestLatchStatus 7754;
BA_ "SPN" SG_ 2431710718 EngnStrtArtrtrMssgCntr 7757;
BA_ "SPN" SG_ 2431710718 OprtrEngnStrtCnsntSmmr 7755;
BA_ "SPN" SG_ 2431717886 EngnFlVlv1DffrntlPrssrHghRsltn 8494;
BA_ "SPN" SG_ 2431717886 EngnGssFlSpplFltrDffrntlPrssr 12301;
BA_ "SPN" SG_ 2431717886 EngnGssFlSpplFltrIntkPrssr 12302;
BA_ "SPN" SG_ 2431719166 WellStimulationPumpFlowRate 8650;
BA_ "SPN" SG_ 2431719166 WellStimulationPumpRodLoad 8648;
BA_ "SPN" SG_ 2431719166 WllStmltnPmpCvttnStts 8649;
BA_ "SPN" SG_ 2431719166 WllStmltnPmpFldEndVlvLk 8651;
BA_ "SPN" SG_ 2431719166 WllStmltnPmpRtdRdLdPrnt 12811;
BA_ "SPN" SG_ 2432471038 EngnFlVprzr1DshrgTmprtr 6610;
BA_ "SPN" SG_ 2432471038 EngnGssFlSpplPrssr1ExtnddRng 6646;
BA_ "SPN" SG_ 2432471038 GssFlAmltrTmprtr 6815;
BA_ "SPN" SG_ 2432471038 EGssFSppPssRtCtCd 9649;
BA_ "SPN" SG_ 2432492542 EngnExhstBrkAttrCmmnd 5543;
BA_ "SPN" SG_ 2432492542 EngnTrhrgr1TrnDsrdOtltPrssr 5542;
BA_ "SPN" SG_ 2432492542 EngnTrhrgr1TrnOtltPrssr 5541;
BA_ "SPN" SG_ 2432492542 EngnTrhrgr2TrnDsrdOtltPrssr 5545;
BA_ "SPN" SG_ 2432492542 EngnTrhrgr2TrnOtltPrssr 5544;
BA_ "SPN" SG_ 2432499198 CmmnddEngnFlInjtnCntrlPrssr 5314;
BA_ "SPN" SG_ 2432499198 CommandedEngineFuelRailPressure 5313;
BA_ "SPN" SG_ 2432499198 EngnExhstGsRrltn2Vlv2Pstn 5263;
BA_ "SPN" SG_ 2432499198 EngnExhstGsRrltn2VlvPstn 5262;
BA_ "SPN" SG_ 2432520702 AftrlrClntThrmsttMd 4198;
BA_ "SPN" SG_ 2432520702 DsrdAftrlrClntIntkTmprtr 4199;
BA_ "SPN" SG_ 2432520702 DsrdAftrlrClntThrmsttOpnng 4200;
BA_ "SPN" SG_ 2432520702 EngnChrgArClrBpssVlv1Cmmnd 7421;
BA_ "SPN" SG_ 2432520702 EngnChrgArClrBpssVlv2Cmmnd 7422;
BA_ "SPN" SG_ 2432520958 DsrdEngnClntPmpOtltTmprtr 4196;
BA_ "SPN" SG_ 2432520958 DsrdEngnClntThrmsttOpnng 4197;
BA_ "SPN" SG_ 2432520958 EngineCoolantThermostatMode 4195;
BA_ "SPN" SG_ 2432520958 EngnAxlrClrSpplVlv1AttrCmmnd 5546;
BA_ "SPN" SG_ 2432520958 EngnAxlrClrSpplVlv2AttrCmmnd 5547;
BA_ "SPN" SG_ 2432541438 EngineFuel1Temperature2 3468;
BA_ "SPN" SG_ 2432541438 EngnFlSstm2GsMssFlwRt 3467;
BA_ "SPN" SG_ 2432541438 EngnFlVlv2IntkAsltPrssr 3466;
BA_ "SPN" SG_ 2432541438 EngnFlVlv2OtltAsltPrssr 3469;
BA_ "SPN" SG_ 2432541694 EngnTrhrgrCmprssrBpssAttr1Cmmnd 3470;
BA_ "SPN" SG_ 2432541694 EngnTrhrgrCmprssrBpssAttr1Pstn 3675;
BA_ "SPN" SG_ 2432541694 EngnTrhrgrCmprssrBpssAttr2Cmmnd 5369;
BA_ "SPN" SG_ 2432541694 EngnVrlGmtrTrhrgrAttr1 641;
BA_ "SPN" SG_ 2432541694 ETCpssBpssAtt1DsdPst 5366;
BA_ "SPN" SG_ 2432541694 ETCpssBpssAtt1PFMI 5367;
BA_ "SPN" SG_ 2432541694 ETCpssBpssAtt1TptStts 5368;
BA_ "SPN" SG_ 2432593918 ACCDistanceAlertSignal 1796;
BA_ "SPN" SG_ 2432593918 ACCSystemShutoffWarning 1797;
BA_ "SPN" SG_ 2432593918 ACCTargetDetected 1798;
BA_ "SPN" SG_ 2432593918 AdaptiveCruiseControlMode 1590;
BA_ "SPN" SG_ 2432593918 AdaptiveCruiseControlSetSpeed 1588;
BA_ "SPN" SG_ 2432593918 Adptvrsntrlstdstnmd 1589;
BA_ "SPN" SG_ 2432593918 Distancetoforwardvehicle 1587;
BA_ "SPN" SG_ 2432593918 ForwardCollisionWarning 5022;
BA_ "SPN" SG_ 2432593918 Roadcurvature 1591;
BA_ "SPN" SG_ 2432593918 Speedofforwardvehicle 1586;
BA_ "SPN" SG_ 2432595710 DisplayDeadbands 2577;
BA_ "SPN" SG_ 2432595710 LEDDisplayData1 1573;
BA_ "SPN" SG_ 2432595710 LEDDisplayDeadbandControl 1806;
BA_ "SPN" SG_ 2432595710 LEDDisplayModeControl 1805;
BA_ "SPN" SG_ 2432595710 LEDPatternControl 2578;
BA_ "SPN" SG_ 2498776830 EngnClndr1AvrgCmstnDrtn 6486;
BA_ "SPN" SG_ 2498776830 EngnClndr1AvrgCntrfCmstnTmng 6485;
BA_ "SPN" SG_ 2498776830 EngnClndr1AvrgStrtfCmstnTmng 6484;
BA_ "SPN" SG_ 2498776830 EngnClndr1IndtdMnEfftvPrssr 6483;
BA_ "SPN" SG_ 2498777086 EngnClndr2AvrgCmstnDrtn 6490;
BA_ "SPN" SG_ 2498777086 EngnClndr2AvrgCntrfCmstnTmng 6489;
BA_ "SPN" SG_ 2498777086 EngnClndr2AvrgStrtfCmstnTmng 6488;
BA_ "SPN" SG_ 2498777086 EngnClndr2IndtdMnEfftvPrssr 6487;
BA_ "SPN" SG_ 2498777342 EngnClndr3AvrgCmstnDrtn 6494;
BA_ "SPN" SG_ 2498777342 EngnClndr3AvrgCntrfCmstnTmng 6493;
BA_ "SPN" SG_ 2498777342 EngnClndr3AvrgStrtfCmstnTmng 6492;
BA_ "SPN" SG_ 2498777342 EngnClndr3IndtdMnEfftvPrssr 6491;
BA_ "SPN" SG_ 2498777598 EngnClndr4AvrgCmstnDrtn 6498;
BA_ "SPN" SG_ 2498777598 EngnClndr4AvrgCntrfCmstnTmng 6497;
BA_ "SPN" SG_ 2498777598 EngnClndr4AvrgStrtfCmstnTmng 6496;
BA_ "SPN" SG_ 2498777598 EngnClndr4IndtdMnEfftvPrssr 6495;
BA_ "SPN" SG_ 2498777854 EngnClndr5AvrgCmstnDrtn 6502;
BA_ "SPN" SG_ 2498777854 EngnClndr5AvrgCntrfCmstnTmng 6501;
BA_ "SPN" SG_ 2498777854 EngnClndr5AvrgStrtfCmstnTmng 6500;
BA_ "SPN" SG_ 2498777854 EngnClndr5IndtdMnEfftvPrssr 6499;
BA_ "SPN" SG_ 2498778110 EngnClndr6AvrgCmstnDrtn 6506;
BA_ "SPN" SG_ 2498778110 EngnClndr6AvrgCntrfCmstnTmng 6505;
BA_ "SPN" SG_ 2498778110 EngnClndr6AvrgStrtfCmstnTmng 6504;
BA_ "SPN" SG_ 2498778110 EngnClndr6IndtdMnEfftvPrssr 6503;
BA_ "SPN" SG_ 2498778366 EngnClndr7AvrgCmstnDrtn 6510;
BA_ "SPN" SG_ 2498778366 EngnClndr7AvrgCntrfCmstnTmng 6509;
BA_ "SPN" SG_ 2498778366 EngnClndr7AvrgStrtfCmstnTmng 6508;
BA_ "SPN" SG_ 2498778366 EngnClndr7IndtdMnEfftvPrssr 6507;
BA_ "SPN" SG_ 2498778622 EngnClndr8AvrgCmstnDrtn 6514;
BA_ "SPN" SG_ 2498778622 EngnClndr8AvrgCntrfCmstnTmng 6513;
BA_ "SPN" SG_ 2498778622 EngnClndr8AvrgStrtfCmstnTmng 6512;
BA_ "SPN" SG_ 2498778622 EngnClndr8IndtdMnEfftvPrssr 6511;
BA_ "SPN" SG_ 2498778878 EngnClndr9AvrgCmstnDrtn 6518;
BA_ "SPN" SG_ 2498778878 EngnClndr9AvrgCntrfCmstnTmng 6517;
BA_ "SPN" SG_ 2498778878 EngnClndr9AvrgStrtfCmstnTmng 6516;
BA_ "SPN" SG_ 2498778878 EngnClndr9IndtdMnEfftvPrssr 6515;
BA_ "SPN" SG_ 2498779134 EngnClndr10AvrgCmstnDrtn 6522;
BA_ "SPN" SG_ 2498779134 EngnClndr10AvrgCntrfCmstnTmng 6521;
BA_ "SPN" SG_ 2498779134 EngnClndr10AvrgStrtfCmstnTmng 6520;
BA_ "SPN" SG_ 2498779134 EngnClndr10IndtdMnEfftvPrssr 6519;
BA_ "SPN" SG_ 2498779390 EngnClndr11AvrgCmstnDrtn 6526;
BA_ "SPN" SG_ 2498779390 EngnClndr11AvrgCntrfCmstnTmng 6525;
BA_ "SPN" SG_ 2498779390 EngnClndr11AvrgStrtfCmstnTmng 6524;
BA_ "SPN" SG_ 2498779390 EngnClndr11IndtdMnEfftvPrssr 6523;
BA_ "SPN" SG_ 2498779646 EngnClndr12AvrgCmstnDrtn 6530;
BA_ "SPN" SG_ 2498779646 EngnClndr12AvrgCntrfCmstnTmng 6529;
BA_ "SPN" SG_ 2498779646 EngnClndr12AvrgStrtfCmstnTmng 6528;
BA_ "SPN" SG_ 2498779646 EngnClndr12IndtdMnEfftvPrssr 6527;
BA_ "SPN" SG_ 2498779902 EngnClndr13AvrgCmstnDrtn 6534;
BA_ "SPN" SG_ 2498779902 EngnClndr13AvrgCntrfCmstnTmng 6533;
BA_ "SPN" SG_ 2498779902 EngnClndr13AvrgStrtfCmstnTmng 6532;
BA_ "SPN" SG_ 2498779902 EngnClndr13IndtdMnEfftvPrssr 6531;
BA_ "SPN" SG_ 2498780158 EngnClndr14AvrgCmstnDrtn 6538;
BA_ "SPN" SG_ 2498780158 EngnClndr14AvrgCntrfCmstnTmng 6537;
BA_ "SPN" SG_ 2498780158 EngnClndr14AvrgStrtfCmstnTmng 6536;
BA_ "SPN" SG_ 2498780158 EngnClndr14IndtdMnEfftvPrssr 6535;
BA_ "SPN" SG_ 2498780414 EngnClndr15AvrgCmstnDrtn 6542;
BA_ "SPN" SG_ 2498780414 EngnClndr15AvrgCntrfCmstnTmng 6541;
BA_ "SPN" SG_ 2498780414 EngnClndr15AvrgStrtfCmstnTmng 6540;
BA_ "SPN" SG_ 2498780414 EngnClndr15IndtdMnEfftvPrssr 6539;
BA_ "SPN" SG_ 2498780670 EngnClndr16AvrgCmstnDrtn 6546;
BA_ "SPN" SG_ 2498780670 EngnClndr16AvrgCntrfCmstnTmng 6545;
BA_ "SPN" SG_ 2498780670 EngnClndr16AvrgStrtfCmstnTmng 6544;
BA_ "SPN" SG_ 2498780670 EngnClndr16IndtdMnEfftvPrssr 6543;
BA_ "SPN" SG_ 2498780926 EngnClndr17AvrgCmstnDrtn 6550;
BA_ "SPN" SG_ 2498780926 EngnClndr17AvrgCntrfCmstnTmng 6549;
BA_ "SPN" SG_ 2498780926 EngnClndr17AvrgStrtfCmstnTmng 6548;
BA_ "SPN" SG_ 2498780926 EngnClndr17IndtdMnEfftvPrssr 6547;
BA_ "SPN" SG_ 2498781182 EngnClndr18AvrgCmstnDrtn 6554;
BA_ "SPN" SG_ 2498781182 EngnClndr18AvrgCntrfCmstnTmng 6553;
BA_ "SPN" SG_ 2498781182 EngnClndr18AvrgStrtfCmstnTmng 6552;
BA_ "SPN" SG_ 2498781182 EngnClndr18IndtdMnEfftvPrssr 6551;
BA_ "SPN" SG_ 2498781438 EngnClndr19AvrgCmstnDrtn 6558;
BA_ "SPN" SG_ 2498781438 EngnClndr19AvrgCntrfCmstnTmng 6557;
BA_ "SPN" SG_ 2498781438 EngnClndr19AvrgStrtfCmstnTmng 6556;
BA_ "SPN" SG_ 2498781438 EngnClndr19IndtdMnEfftvPrssr 6555;
BA_ "SPN" SG_ 2498781694 EngnClndr20AvrgCmstnDrtn 6562;
BA_ "SPN" SG_ 2498781694 EngnClndr20AvrgCntrfCmstnTmng 6561;
BA_ "SPN" SG_ 2498781694 EngnClndr20AvrgStrtfCmstnTmng 6560;
BA_ "SPN" SG_ 2498781694 EngnClndr20IndtdMnEfftvPrssr 6559;
BA_ "SPN" SG_ 2498825982 DmpBdRsPstnRltvtRmmnddMxmm 8314;
BA_ "SPN" SG_ 2498825982 DumpBodyEjectorBladePosition 8315;
BA_ "SPN" SG_ 2498825982 DumpBodyRaiseAngle 8313;
BA_ "SPN" SG_ 2498825982 DumpBodyRollAngle 8312;
BA_ "SPN" SG_ 2499547902 CabDoorsLockActuationCommand 7727;
BA_ "SPN" SG_ 2499547902 LeftFrontWindowPositionCommand 7729;
BA_ "SPN" SG_ 2499547902 LeftRearWindowPositionCommand 7731;
BA_ "SPN" SG_ 2499547902 MirrorLeft1HeatCommand 7741;
BA_ "SPN" SG_ 2499547902 MirrorLeft1HorizontalCommand 7733;
BA_ "SPN" SG_ 2499547902 MirrorLeft1VerticalCommand 7734;
BA_ "SPN" SG_ 2499547902 MirrorLeft2HeatCommand 7743;
BA_ "SPN" SG_ 2499547902 MirrorLeft2HorizontalCommand 7737;
BA_ "SPN" SG_ 2499547902 MirrorLeft2VerticalCommand 7738;
BA_ "SPN" SG_ 2499547902 MirrorRight1HeatCommand 7742;
BA_ "SPN" SG_ 2499547902 MirrorRight1HorizontalCommand 7735;
BA_ "SPN" SG_ 2499547902 MirrorRight1VerticalCommand 7736;
BA_ "SPN" SG_ 2499547902 MirrorRight2HeatCommand 7744;
BA_ "SPN" SG_ 2499547902 MirrorRight2HorizontalCommand 7739;
BA_ "SPN" SG_ 2499547902 MirrorRight2VerticalCommand 7740;
BA_ "SPN" SG_ 2499547902 RemoteCabDoorLockRequest 7728;
BA_ "SPN" SG_ 2499547902 RightFrontWindowPositionCommand 7730;
BA_ "SPN" SG_ 2499547902 RightRearWindowPositionCommand 7732;
BA_ "SPN" SG_ 2499547902 MirrorFoldingSwitch 12317;
BA_ "SPN" SG_ 2499547902 MirrorAutoPanningEnable 12318;
BA_ "SPN" SG_ 2499548158 LeftFrontCabDoorLatchPosition 7723;
BA_ "SPN" SG_ 2499548158 LeftRearCabDoorLatchPosition 7725;
BA_ "SPN" SG_ 2499548158 RightFrontCabDoorLatchPosition 7724;
BA_ "SPN" SG_ 2499548158 RightRearCabDoorLatchPosition 7726;
BA_ "SPN" SG_ 2499548670 BatteryPotentialPowerInput3 7712;
BA_ "SPN" SG_ 2499548670 BatteryPotentialPowerInput4 7713;
BA_ "SPN" SG_ 2499548670 SLIBattery3NetCurrent 7714;
BA_ "SPN" SG_ 2499548670 SLIBattery4NetCurrent 7715;
BA_ "SPN" SG_ 2499548926 PayloadTemperature5 7707;
BA_ "SPN" SG_ 2499549182 PayloadTemperature1 7703;
BA_ "SPN" SG_ 2499549182 PayloadTemperature2 7704;
BA_ "SPN" SG_ 2499549182 PayloadTemperature3 7705;
BA_ "SPN" SG_ 2499549182 PayloadTemperature4 7706;
BA_ "SPN" SG_ 2499556094 Atttt1PttSsHtHSdDvDstStts 7322;
BA_ "SPN" SG_ 2499556094 Atttt1PttSsHtHSdDvPFMI 7321;
BA_ "SPN" SG_ 2499556094 Atttt1PttSsHtLwSdDvDstStts 7324;
BA_ "SPN" SG_ 2499556094 Atttt1PttSsHtLwSdDvPFMI 7323;
BA_ "SPN" SG_ 2499556094 Atttt1PttSsHtPwSppDstStts 7330;
BA_ "SPN" SG_ 2499556094 Atttt1PttSsHtPwSppPFMI 7329;
BA_ "SPN" SG_ 2499556094 Atttt1PttSsIptDstStts 7326;
BA_ "SPN" SG_ 2499556094 Atttt1PttSsIptPFMI 7325;
BA_ "SPN" SG_ 2499556094 Atttt1PttSsPwSppDstStts 7328;
BA_ "SPN" SG_ 2499556094 Atttt1PttSsPwSppPFMI 7327;
BA_ "SPN" SG_ 2499556350 EngnFl1InjtrMtrngRl1DsrdPrssr 7100;
BA_ "SPN" SG_ 2499556350 EngnFl1InjtrMtrngRl2DsrdPrssr 7101;
BA_ "SPN" SG_ 2499556606 EF1ItMtR1Pss1ExtddR 7096;
BA_ "SPN" SG_ 2499556606 EF1ItMtR1Pss2ExtddR 7097;
BA_ "SPN" SG_ 2499556606 EF1ItMtR2Pss1ExtddR 7098;
BA_ "SPN" SG_ 2499556606 EF1ItMtR2Pss2ExtddR 7099;
BA_ "SPN" SG_ 2499557118 EngnGssFlSpplBldVlv1Pstn 7083;
BA_ "SPN" SG_ 2499557118 EngnGssFlSpplBldVlv2Pstn 7084;
BA_ "SPN" SG_ 2499557118 EngnGssFlSpplBldVlv3Pstn 7085;
BA_ "SPN" SG_ 2499557118 EngnGssFlSpplShtffVlv1Pstn 7081;
BA_ "SPN" SG_ 2499557118 EngnGssFlSpplShtffVlv2Pstn 7082;
BA_ "SPN" SG_ 2499557118 InertGasSupplyValvePosition 7442;
BA_ "SPN" SG_ 2499557374 EngineOilMist10Concentration 7080;
BA_ "SPN" SG_ 2499557374 EngineOilMist9Concentration 7079;
BA_ "SPN" SG_ 2499557630 EngineOilMist1Concentration 7071;
BA_ "SPN" SG_ 2499557630 EngineOilMist2Concentration 7072;
BA_ "SPN" SG_ 2499557630 EngineOilMist3Concentration 7073;
BA_ "SPN" SG_ 2499557630 EngineOilMist4Concentration 7074;
BA_ "SPN" SG_ 2499557630 EngineOilMist5Concentration 7075;
BA_ "SPN" SG_ 2499557630 EngineOilMist6Concentration 7076;
BA_ "SPN" SG_ 2499557630 EngineOilMist7Concentration 7077;
BA_ "SPN" SG_ 2499557630 EngineOilMist8Concentration 7078;
BA_ "SPN" SG_ 2499557886 PlntGssFlSpplOtltPrssr 7067;
BA_ "SPN" SG_ 2499557886 PlntInrtGsSpplOtltPrssr 7068;
BA_ "SPN" SG_ 2499558142 EngnGssFlSpplPrssr2 7063;
BA_ "SPN" SG_ 2499558142 EngnGssFlSpplShtffVlv1IntkPrssr 7065;
BA_ "SPN" SG_ 2499558142 EngnGssFlSpplShtffVlv2IntkPrssr 7066;
BA_ "SPN" SG_ 2499558142 EngnGssFlSpplUntIntkPrssr 7064;
BA_ "SPN" SG_ 2499580158 EngnFl1InjtrMtrngRl1Prssr1 6589;
BA_ "SPN" SG_ 2499580158 EngnFl1InjtrMtrngRl1Prssr2 6590;
BA_ "SPN" SG_ 2499580158 EngnFl1InjtrMtrngRl2Prssr1 6591;
BA_ "SPN" SG_ 2499580158 EngnFl1InjtrMtrngRl2Prssr2 6592;
BA_ "SPN" SG_ 2499582206 SftTpSpdLmtRmnngCntnsIntrvlDstn 6914;
BA_ "SPN" SG_ 2499582206 SftTpSpdLmtRmnngDstn 6372;
BA_ "SPN" SG_ 2499582206 SoftTopRatioLimitExceeded 6371;
BA_ "SPN" SG_ 2499582206 SoftTopSpeedLimitActive 6370;
BA_ "SPN" SG_ 2499582206 SoftTopSpeedLimitResetDistance 6373;
BA_ "SPN" SG_ 2499583486 EngnTmngAttr1PstnCmmnd 6336;
BA_ "SPN" SG_ 2499583486 EngnTmngAttr2PstnCmmnd 6337;
BA_ "SPN" SG_ 2499583742 EngineTimingActuator1 635;
BA_ "SPN" SG_ 2499583742 EngineTimingActuator2 1245;
BA_ "SPN" SG_ 2499583742 EngnTmngAttr1RqstdPstn 6334;
BA_ "SPN" SG_ 2499583742 EngnTmngAttr2RqstdPstn 6335;
BA_ "SPN" SG_ 2499592190 TrnsmssnClth1AttrPrnt 5944;
BA_ "SPN" SG_ 2499592190 TrnsmssnClth1ClngAttrStts 5949;
BA_ "SPN" SG_ 2499592190 TrnsmssnClth2AttrPrnt 5945;
BA_ "SPN" SG_ 2499592190 TrnsmssnClth2ClngAttrStts 5950;
BA_ "SPN" SG_ 2499592190 TrnsmssnHdrlPmpAttr1Prnt 5946;
BA_ "SPN" SG_ 2499592190 TrnsmssnHdrlPmpAttr2Prnt 6582;
BA_ "SPN" SG_ 2499592190 TrnsmssnShftAttr1Prnt 5947;
BA_ "SPN" SG_ 2499592190 TrnsmssnShftAttr2Prnt 5948;
BA_ "SPN" SG_ 2499592190 TrnsmssnShftRl1AttrStts 5951;
BA_ "SPN" SG_ 2499592190 TrnsmssnShftRl2AttrStts 5952;
BA_ "SPN" SG_ 2499592190 TrnsmssnShftRl3AttrStts 5953;
BA_ "SPN" SG_ 2499592190 TrnsmssnShftRl4AttrStts 5954;
BA_ "SPN" SG_ 2499592190 TrnsmssnShftRl5AttrStts 5955;
BA_ "SPN" SG_ 2499592190 TrnsmssnShftRl6AttrStts 5956;
BA_ "SPN" SG_ 2499592446 TransmissionShiftRail1Position 4218;
BA_ "SPN" SG_ 2499592446 TransmissionShiftRail2Position 4219;
BA_ "SPN" SG_ 2499592446 TransmissionShiftRail3Position 4220;
BA_ "SPN" SG_ 2499592446 TransmissionShiftRail4Position 5941;
BA_ "SPN" SG_ 2499592446 TransmissionShiftRail5Position 5942;
BA_ "SPN" SG_ 2499592446 TransmissionShiftRail6Position 5943;
BA_ "SPN" SG_ 2499604222 BladeElevationDeviationLeft 5410;
BA_ "SPN" SG_ 2499604222 BladeElevationDeviationRight 5411;
BA_ "SPN" SG_ 2499604222 BldRfrnElvtnOffstLft 5412;
BA_ "SPN" SG_ 2499604222 BldRfrnElvtnOffstRght 5413;
BA_ "SPN" SG_ 2499604478 EExstGsRt1OttAstPssHRst 5431;
BA_ "SPN" SG_ 2499604478 EFDvPssHRstExtddR 7469;
BA_ "SPN" SG_ 2499604478 EngnExhstGsRrltn1IntkAsltPrssr 5430;
BA_ "SPN" SG_ 2499604478 EngnOlPrssrHghRsltnExtnddRng 7468;
BA_ "SPN" SG_ 2499607550 EExstMdB1FwBVvAttPst 5277;
BA_ "SPN" SG_ 2499607550 EExstMdB2FwBVvAttPst 5279;
BA_ "SPN" SG_ 2499614462 DrvrOpntClssftnSstmStts 4963;
BA_ "SPN" SG_ 2499614462 OpntClssftnSstm10Stts 4972;
BA_ "SPN" SG_ 2499614462 OpntClssftnSstm3Stts 4965;
BA_ "SPN" SG_ 2499614462 OpntClssftnSstm4Stts 4966;
BA_ "SPN" SG_ 2499614462 OpntClssftnSstm5Stts 4967;
BA_ "SPN" SG_ 2499614462 OpntClssftnSstm6Stts 4968;
BA_ "SPN" SG_ 2499614462 OpntClssftnSstm7Stts 4969;
BA_ "SPN" SG_ 2499614462 OpntClssftnSstm8Stts 4970;
BA_ "SPN" SG_ 2499614462 OpntClssftnSstm9Stts 4971;
BA_ "SPN" SG_ 2499614462 PssngrOpntClssftnSstmStts 4964;
BA_ "SPN" SG_ 2499614718 Beltlock10Status 4961;
BA_ "SPN" SG_ 2499614718 Beltlock3Status 4954;
BA_ "SPN" SG_ 2499614718 Beltlock4Status 4955;
BA_ "SPN" SG_ 2499614718 Beltlock5Status 4956;
BA_ "SPN" SG_ 2499614718 Beltlock6Status 4957;
BA_ "SPN" SG_ 2499614718 Beltlock7Status 4958;
BA_ "SPN" SG_ 2499614718 Beltlock8Status 4959;
BA_ "SPN" SG_ 2499614718 Beltlock9Status 4960;
BA_ "SPN" SG_ 2499614718 DriverBeltlockStatus 4952;
BA_ "SPN" SG_ 2499614718 PassengerBeltlockStatus 4953;
BA_ "SPN" SG_ 2499614718 PssngrArgDtvtnSwthStts 4962;
BA_ "SPN" SG_ 2499624702 Aftrtrtmnt1SCRIntkTmprtr 4360;
BA_ "SPN" SG_ 2499624702 Aftrtrtmnt1SCROtltTmprtr 4363;
BA_ "SPN" SG_ 2499624702 Atttt1SCRItTptPFMI 4361;
BA_ "SPN" SG_ 2499624702 Atttt1SCROttTptPFMI 4362;
BA_ "SPN" SG_ 2499630078 EngineExhaustTemperatureAverage 4151;
BA_ "SPN" SG_ 2499630078 EngnExhstBnk1TmprtrAvrg 4153;
BA_ "SPN" SG_ 2499630078 EngnExhstBnk2TmprtrAvrg 4152;
BA_ "SPN" SG_ 2499635454 GrossCombinationWeight 417;
BA_ "SPN" SG_ 2499635454 NetVehicleWeightChange 413;
BA_ "SPN" SG_ 2499635966 AdditionalAxleGroupLocation 5935;
BA_ "SPN" SG_ 2499635966 AxleGroupLocation 4073;
BA_ "SPN" SG_ 2499635966 AxleGroupWeight 409;
BA_ "SPN" SG_ 2499641854 EExstGsRt1CBpssAttPst 3672;
BA_ "SPN" SG_ 2550660862 ValveAssemblyLoadsensePressure 4088;
BA_ "SPN" SG_ 2550660862 ValveAssemblySupplyPressure 4089;
BA_ "SPN" SG_ 2550660862 ValveLoadSensePressure 4086;
BA_ "SPN" SG_ 2550660862 ValvePilotPressure 4087;
BA_ "SPN" SG_ 2550988542 EngineClutchEngageRequestStatus 7844;
BA_ "SPN" SG_ 2550988542 ReadyForClutchEngagementStatus 7847;
BA_ "SPN" SG_ 2550988542 AcceleratorPedal3Position 28;
BA_ "SPN" SG_ 2557214462 WSttPpDsPssCtStPtCd 9198;
BA_ "SPN" SG_ 2557214462 WSttPpStPssCtStPtCd 9197;
BA_ "SPN" SG_ 2557345534 WllStmltnPmpPlngrFrngOrdr 8870;
BA_ "SPN" SG_ 2557345534 WllStmltnPmpRdLdHghThrshld 8869;
BA_ "SPN" SG_ 2557345534 WllStmltnPmpStnPrssrHghThrshld 8865;
BA_ "SPN" SG_ 2557345534 WllStmltnPmpStnPrssrLwThrshld 8864;
BA_ "SPN" SG_ 2557345534 WSttPpCstSpdHTsd 8868;
BA_ "SPN" SG_ 2557345534 WSttPpCstSpdLwTsd 8867;
BA_ "SPN" SG_ 2557345534 WSttPpDsPssHTsd 8866;
BA_ "SPN" SG_ 2557345534 WSttPpGBxOPssHTsd 8861;
BA_ "SPN" SG_ 2557345534 WSttPpGBxOPssLwTsd 8860;
BA_ "SPN" SG_ 2557345534 WSttPpGBxOTptHTsd 8863;
BA_ "SPN" SG_ 2557345534 WSttPpGBxOTptLwTsd 8862;
BA_ "SPN" SG_ 2557673214 OlDrsMntrCnfgrtnIdntftnNmr 8191;
BA_ "SPN" SG_ 2557673214 OlDrsMntrFrrsBn1CntCmmnd 8192;
BA_ "SPN" SG_ 2557673214 OlDrsMntrFrrsBn2CntCmmnd 8193;
BA_ "SPN" SG_ 2557673214 OlDrsMntrFrrsBn3CntCmmnd 8194;
BA_ "SPN" SG_ 2557673214 OlDrsMntrFrrsBn4CntCmmnd 8195;
BA_ "SPN" SG_ 2557673214 OlDrsMntrFrrsBn5CntCmmnd 8196;
BA_ "SPN" SG_ 2557673214 OlDrsMntrFrrsBn6CntCmmnd 8197;
BA_ "SPN" SG_ 2557673214 OlDrsMntrNnFrrsBn1CntCmmnd 8198;
BA_ "SPN" SG_ 2557673214 OlDrsMntrNnFrrsBn2CntCmmnd 8199;
BA_ "SPN" SG_ 2557673214 OlDrsMntrNnFrrsBn3CntCmmnd 8200;
BA_ "SPN" SG_ 2557673214 OlDrsMntrNnFrrsBn4CntCmmnd 8201;
BA_ "SPN" SG_ 2557673214 OlDrsMntrNnFrrsBn5CntCmmnd 8202;
BA_ "SPN" SG_ 2557673214 OlDrsMntrNnFrrsBn6CntCmmnd 8203;
BA_ "SPN" SG_ 2557738750 PrplsnMtrClntFn3EnlCmmnd 8063;
BA_ "SPN" SG_ 2557738750 PrplsnMtrClntFn3PrntSpdCmmnd 8066;
BA_ "SPN" SG_ 2557738750 PrplsnMtrClntFn3PwrHld 8064;
BA_ "SPN" SG_ 2557738750 PrplsnMtrClntFn3SpdCmmnd 8065;
BA_ "SPN" SG_ 2557804286 PrplsnMtrClntFn2EnlCmmnd 8051;
BA_ "SPN" SG_ 2557804286 PrplsnMtrClntFn2PrntSpdCmmnd 8054;
BA_ "SPN" SG_ 2557804286 PrplsnMtrClntFn2PwrHld 8052;
BA_ "SPN" SG_ 2557804286 PrplsnMtrClntFn2SpdCmmnd 8053;
BA_ "SPN" SG_ 2557869822 PrplsnMtrClntFn1EnlCmmnd 8039;
BA_ "SPN" SG_ 2557869822 PrplsnMtrClntFn1PrntSpdCmmnd 8042;
BA_ "SPN" SG_ 2557869822 PrplsnMtrClntFn1PwrHld 8040;
BA_ "SPN" SG_ 2557869822 PrplsnMtrClntFn1SpdCmmnd 8041;
BA_ "SPN" SG_ 2557935358 PwrEltrnsClntFn3EnlCmmnd 8027;
BA_ "SPN" SG_ 2557935358 PwrEltrnsClntFn3PrntSpdCmmnd 8030;
BA_ "SPN" SG_ 2557935358 PwrEltrnsClntFn3PwrHld 8028;
BA_ "SPN" SG_ 2557935358 PwrEltrnsClntFn3SpdCmmnd 8029;
BA_ "SPN" SG_ 2558000894 PwrEltrnsClntFn2EnlCmmnd 8015;
BA_ "SPN" SG_ 2558000894 PwrEltrnsClntFn2PrntSpdCmmnd 8018;
BA_ "SPN" SG_ 2558000894 PwrEltrnsClntFn2PwrHld 8016;
BA_ "SPN" SG_ 2558000894 PwrEltrnsClntFn2SpdCmmnd 8017;
BA_ "SPN" SG_ 2558066430 PwrEltrnsClntFn1EnlCmmnd 8003;
BA_ "SPN" SG_ 2558066430 PwrEltrnsClntFn1PrntSpdCmmnd 8006;
BA_ "SPN" SG_ 2558066430 PwrEltrnsClntFn1PwrHld 8004;
BA_ "SPN" SG_ 2558066430 PwrEltrnsClntFn1SpdCmmnd 8005;
BA_ "SPN" SG_ 2558131966 PropulsionMotorOilPumpPowerHold 7992;
BA_ "SPN" SG_ 2558131966 PrplsnMtrOlPmpEnlCmmnd 7991;
BA_ "SPN" SG_ 2558131966 PrplsnMtrOlPmpPrntSpdCmmnd 7994;
BA_ "SPN" SG_ 2558131966 PrplsnMtrOlPmpSpdCmmnd 7993;
BA_ "SPN" SG_ 2558197502 PrplsnMtrClntPmpEnlCmmnd 7979;
BA_ "SPN" SG_ 2558197502 PrplsnMtrClntPmpPrntSpdCmmnd 7982;
BA_ "SPN" SG_ 2558197502 PrplsnMtrClntPmpPwrHld 7980;
BA_ "SPN" SG_ 2558197502 PrplsnMtrClntPmpSpdCmmnd 7981;
BA_ "SPN" SG_ 2558263038 PwrEltrnsClntPmpEnlCmmnd 7967;
BA_ "SPN" SG_ 2558263038 PwrEltrnsClntPmpPrntSpdCmmnd 7970;
BA_ "SPN" SG_ 2558263038 PwrEltrnsClntPmpPwrHld 7968;
BA_ "SPN" SG_ 2558263038 PwrEltrnsClntPmpSpdCmmnd 7969;
VAL_ 2365484286 Directionindicator 3 "NotAvailable" 2 "Error" 1 "Reverse" 0 "Forward" ;
VAL_ 2365484286 Driver1TimeRelatedStates 15 "NotAvailable" 14 "Error" 13 "Other" 7 "1100Reserved" 6 "Limit616HReached" 5 "Limit515MinBefore16H" 4 "Limit49HReached" 3 "Limit315MinBefore9H" 2 "Limit24HReached" 1 "Limit115MinBefore4H" 0 "Normal_NoLimitsReached" ;
VAL_ 2365484286 Driver1workingstate 7 "NotAvailable" 6 "Error" 4 "101Reserved" 3 "DriveBehindWheel" 2 "WrkLdngUnldingWorkingInAnOffice" 1 "DriverAvailableShortBreak" 0 "RestSleeping" ;
VAL_ 2365484286 Driver2TimeRelatedStates 15 "NotAvailable" 14 "Error" 13 "Other" 7 "1100Reserved" 6 "Limit616HReached" 5 "Limit515MinBefore16H" 4 "Limit49HReached" 3 "Limit315MinBefore9H" 2 "Limit24HReached" 1 "Limit115MinBefore4H" 0 "Normal_NoLimitsReached" ;
VAL_ 2365484286 Driver2workingstate 7 "NotAvailable" 6 "Error" 4 "101Reserved" 3 "DriveBehindWheel" 2 "WrkLdngUnldingWorkingInAnOffice" 1 "DriverAvailableShortBreak" 0 "RestSleeping" ;
VAL_ 2365484286 Drivercarddriver1 3 "NotAvailable" 2 "Error" 1 "DriverCardPresent" 0 "DriverCardNotPresent" ;
VAL_ 2365484286 Drivercarddriver2 3 "NotAvailable" 2 "Error" 1 "DriverCardPresent" 0 "DriverCardNotPresent" ;
VAL_ 2365484286 Handlinginformation 3 "NotAvailable" 2 "Error" 1 "HandlingInformation" 0 "NoHandlingInformation" ;
VAL_ 2365484286 Systemevent 3 "NotAvailable" 2 "Error" 1 "TachographEvent" 0 "NoTachographEvent" ;
VAL_ 2365484286 Tachographperformance 3 "NotAvailable" 2 "Error" 1 "PerformanceAnalysis" 0 "NormalPerformance" ;
VAL_ 2365484286 Vehiclemotion 3 "NotAvailable" 2 "Error" 1 "VehicleMotionDetected" 0 "VehicleMotionNotDetected" ;
VAL_ 2365484286 VehicleOverspeed 3 "NotAvailable" 2 "Error" 1 "Overspeed" 0 "NoOverspeed" ;
VAL_ 2365485566 LaserTracerInformation 32 "Curb" 16 "Stringline" 8 "PreviousPass" 4 "ValidTarget" 2 "LaserIsReady" 1 "LaserPowerIsOn" ;
VAL_ 2365485566 LEDDisplayData2 511 "NotAvailable" 254 "Error" 159 "NoData" 149 "HighCoarse" 148 "HighMedium_Coarse" 147 "HighMedium" 146 "HighMedium_Fine" 145 "HighFine" 144 "OnGrade" 132 "LowFine" 131 "LowMedium_Fine" 130 "LowMedium" 129 "LowMedium_Coarse" 128 "LowCoarse" 64 "RightLEDOn" 32 "LeftLEDOn" 16 "DownLEDOn" 8 "UpLEDOn" 4 "OngradeCLEDOn" 2 "OngradeBLEDOn" 1 "OngradeALEDOn" ;
VAL_ 2365485822 LandLevelingSystemEnableStatus 3 "NotAvailable_NotInstalled" 2 "Error" 1 "Enabled" 0 "Disabled" ;
VAL_ 2431649790 LaneDepartureImminentLeftSide 3 "NotUsed" 2 "Reserved" 1 "Imminent" 0 "NotImminent" ;
VAL_ 2431649790 LaneDepartureImminentRightSide 3 "NotUsed" 2 "Reserved" 1 "Imminent" 0 "NotImminent" ;
VAL_ 2431649790 LaneDepartureLeft 3 "TakeNoAction" 2 "Reserved" 1 "MddlOfVhclDprtsThLnTTheLeftSide" 0 "MddlOfVhclDsNtDprtThLnTThLftSde" ;
VAL_ 2431649790 LaneDepartureRight 3 "TakeNoAction" 2 "Reserved" 1 "MddlOfVhclDprtsThLnTThRightSide" 0 "MddlOfVhclDsNtDprtThLnTThRghtSd" ;
VAL_ 2432593918 ACCDistanceAlertSignal 3 "TakeNoAction" 2 "Reserved" 1 "ACCDASActive" 0 "ACCDASNotActive" ;
VAL_ 2432593918 ACCSystemShutoffWarning 3 "TakeNoAction" 2 "Reserved" 1 "ACCSSOWActive" 0 "ACCSSOWNotActive" ;
VAL_ 2432593918 ACCTargetDetected 3 "TakeNoAction" 2 "Reserved" 1 "TargetDetected" 0 "NoTargetsDetected" ;
VAL_ 2432593918 ForwardCollisionWarning 3 "notAvailable" 2 "ErrorIndicator" 1 "CollisionIsImminent" 0 "NoWarning" ;
VAL_ 2432595710 DisplayDeadbands 15 "NotAvailable" 3 "1110Reserved" 2 "Wide_24mm" 1 "Standard_12mm" 0 "Narrow_45mm" ;
VAL_ 2432595710 LEDDisplayData1 511 "NotAvailable" 254 "Error" 159 "NoData" 149 "HighCoarse" 148 "HighMedium_Coarse" 147 "HighMedium" 146 "HighMedium_Fine" 145 "HighFine" 144 "OnGrade" 132 "LowFine" 131 "LowMedium_Fine" 130 "LowMedium" 129 "LowMedium_Coarse" 128 "LowCoarse" 32 "LowCoarseLEDOn" 16 "LowFineLEDOn" 8 "OngradeLEDOn" 4 "HighFineLEDOn" 2 "HighCoarseLEDOn" ;
VAL_ 2499614718 Beltlock10Status 3 "NotAvailable" 2 "ErrrBltlckSttCannotBeDetermined" 1 "Locked" 0 "Unlocked" ;
VAL_ 2499614718 Beltlock3Status 3 "NotAvailable" 2 "ErrrBltlckSttCannotBeDetermined" 1 "Locked" 0 "Unlocked" ;
VAL_ 2499614718 Beltlock4Status 3 "NotAvailable" 2 "ErrrBltlckSttCannotBeDetermined" 1 "Locked" 0 "Unlocked" ;
VAL_ 2499614718 Beltlock5Status 3 "NotAvailable" 2 "ErrrBltlckSttCannotBeDetermined" 1 "Locked" 0 "Unlocked" ;
VAL_ 2499614718 Beltlock6Status 3 "NotAvailable" 2 "ErrrBltlckSttCannotBeDetermined" 1 "Locked" 0 "Unlocked" ;
VAL_ 2499614718 Beltlock7Status 3 "NotAvailable" 2 "ErrrBltlckSttCannotBeDetermined" 1 "Locked" 0 "Unlocked" ;
VAL_ 2499614718 Beltlock8Status 3 "NotAvailable" 2 "ErrrBltlckSttCannotBeDetermined" 1 "Locked" 0 "Unlocked" ;
VAL_ 2499614718 Beltlock9Status 3 "NotAvailable" 2 "ErrrBltlckSttCannotBeDetermined" 1 "Locked" 0 "Unlocked" ;
VAL_ 2499614718 DriverBeltlockStatus 3 "NotAvailable" 2 "ErrrBltlckSttCannotBeDetermined" 1 "Locked" 0 "Unlocked" ;
VAL_ 2499614718 PassengerBeltlockStatus 3 "NotAvailable" 2 "ErrrBltlckSttCannotBeDetermined" 1 "Locked" 0 "Unlocked" ;
VAL_ 2499635966 AxleGroupLocation 3 "TrailerFAxleGroup" 2 "TrailerEAxleGroup" 1 "SteerAxleGroup" 0 "Reserved" ;
VAL_ 2499614462 DrvrOpntClssftnSstmStts 7 "NotAvailable" 6 "ErrrClssfctnOfOccpntCnntBDtrmnd" 5 "Reserved" 4 "LargeAdult" 3 "Adult" 2 "SmallAdult" 1 "Child" 0 "Empty" ;
VAL_ 2499614462 PssngrOpntClssftnSstmStts 7 "NotAvailable" 5 "ErrrClssfctnOfOccpntCnntBDtrmnd" 3 "Adult" 4 "LargeAdult" 2 "SmallAdult" 1 "Child" 0 "Empty" ;
VAL_ 2499614462 OpntClssftnSstm3Stts 3 "NotAvailable" 2 "ErrrClssfctonCannotBeDetermined" 1 "Occupied" 0 "Empty" ;
VAL_ 2499614462 OpntClssftnSstm4Stts 3 "NotAvailable" 2 "ErrrClssfctonCannotBeDetermined" 1 "Occupied" 0 "Empty" ;
VAL_ 2499614462 OpntClssftnSstm5Stts 3 "NotAvailable" 2 "ErrrClssfctonCannotBeDetermined" 1 "Occupied" 0 "Empty" ;
VAL_ 2499614462 OpntClssftnSstm6Stts 3 "NotAvailable" 2 "ErrrClssfctonCannotBeDetermined" 1 "Occupied" 0 "Empty" ;
VAL_ 2499614462 OpntClssftnSstm7Stts 3 "NotAvailable" 2 "ErrrClssfctonCannotBeDetermined" 1 "Occupied" 0 "Empty" ;
VAL_ 2499614462 OpntClssftnSstm8Stts 3 "NotAvailable" 2 "ErrrClssfctonCannotBeDetermined" 1 "Occupied" 0 "Empty" ;
VAL_ 2499614462 OpntClssftnSstm9Stts 3 "NotAvailable" 2 "ErrrClssfctonCannotBeDetermined" 1 "Occupied" 0 "Empty" ;
VAL_ 2499614462 OpntClssftnSstm10Stts 3 "NotAvailable" 2 "ErrrClssfctonCannotBeDetermined" 1 "Occupied" 0 "Empty" ;
VAL_ 2499614718 PssngrArgDtvtnSwthStts 3 "NotAvailable" 2 "ErrrSttOfDctvtnSwtchCnntBDtrmnd" 1 "PassengerAirbagDeactivated" 0 "PassengerAirbagActivated" ;
VAL_ 2432520702 AftrlrClntThrmsttMd 3 "DontCare_Reserved" 2 "Reserved" 1 "PosCtrlMode" 0 "TempCtrlMode" ;
VAL_ 2432520958 EngineCoolantThermostatMode 3 "DontCare_Reserved" 2 "Reserved" 1 "PosCtrlMode" 0 "TempCtrlMode" ;
VAL_ 2432541694 ETCpssBpssAtt1TptStts 7 "NotAvailable" 6 "Error" 5 "NotDefined" 4 "LowMostSevere" 3 "LowLeastSevere" 2 "InRange" 1 "HighLeastSevere" 0 "HighMostSevere" ;
VAL_ 2432593918 AdaptiveCruiseControlMode 7 "NotAvailable_NotValid" 6 "DsbldErrrCndtnUsdTIndctThtACCIs" 5 "FinishMode" 4 "HldMdUsdTIndctThtACCHsLstThPrvs" 3 "OvertakeMode" 2 "DstncCtrlActvUsdTIndctThtACCIsO" 1 "SpeedCtrlActive" 0 "OffUsdTIndctACCIsEnbldInClbCnfg" ;
VAL_ 2432593918 Adptvrsntrlstdstnmd 7 "NotAvailable_NotValid" 6 "ErrorCondition" 5 "ConventionalCruiseCtrlMode" 4 "ACCDistanceMode5" 3 "ACCDistanceMode4" 2 "ACCDistanceMode3" 1 "ACCDistanceMode2" 0 "ACCDistanceMode1" ;
VAL_ 2365485822 BladeControlMode 2 "InactiveAutomaticMode" 1 "AutomaticMode" 0 "ManualMode" ;
VAL_ 2365485822 BladeControlModeLeft 15 "NotAvailable" 14 "Error" 3 "1101Reserved" 2 "InactiveAuto" 1 "Auto" 0 "Manual" ;
VAL_ 2365485822 BladeControlModeRight 15 "NotAvailable" 14 "Error" 3 "1101Reserved" 2 "InactiveAuto" 1 "Auto" 0 "Manual" ;
VAL_ 2432595710 LEDDisplayModeControl 15 "NotAvailableNotApplicable" 3 "1110Reserved" 2 "CenterOnGradeDisplayMode2" 1 "OffsetOnGradeDisplayMode" 0 "CenterOnGradeDisplayMode1" ;
VAL_ 2432595710 LEDDisplayDeadbandControl 15 "NotAvailableNotApplicable" 5 "1110Reserved" 4 "_1Mm" 3 "_5Mm" 2 "_24Mm" 1 "_12Mm" 0 "_45Mm" ;
VAL_ 2432595710 LEDPatternControl 15 "NotAvailable" 3 "1110Reserved" 2 "7Channel" 1 "Offset" 0 "5Channel" ;
